VERSION ""

NS_ :

BS_:

BU_: Bat1 OpticalSensor EMUS_BMS SCIMO_PE TelemetryNode Master SensorF SensorR BrakeF BrakeR PDU HVCU HVTU TestBench MDB1 MDB2 MDB3 MDB4 MDB5 MDB6 Track CLU

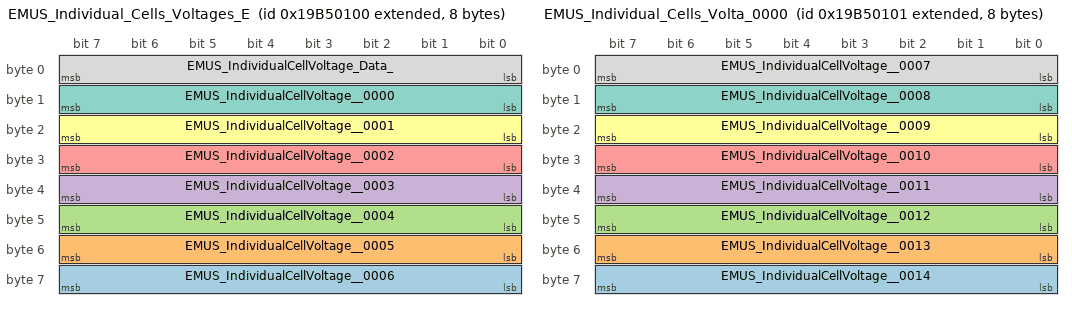
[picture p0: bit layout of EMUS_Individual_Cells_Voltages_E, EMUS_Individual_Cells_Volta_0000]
BO_ 2578776320 EMUS_Individual_Cells_Voltages_E: 8 EMUS_BMS
 SG_ EMUS_IndividualCellVoltage__0006 : 56|8@1+ (0.01,2) [2|4.55] "V" Vector__XXX
 SG_ EMUS_IndividualCellVoltage__0005 : 48|8@1+ (0.01,2) [2|4.55] "V" Vector__XXX
 SG_ EMUS_IndividualCellVoltage__0004 : 40|8@1+ (0.01,2) [2|4.55] "V" Vector__XXX
 SG_ EMUS_IndividualCellVoltage__0003 : 32|8@1+ (0.01,2) [2|4.55] "V" Vector__XXX
 SG_ EMUS_IndividualCellVoltage__0002 : 24|8@1+ (0.01,2) [2|4.55] "V" Vector__XXX
 SG_ EMUS_IndividualCellVoltage__0001 : 16|8@1+ (0.01,2) [2|4.55] "V" Vector__XXX
 SG_ EMUS_IndividualCellVoltage__0000 : 8|8@1+ (0.01,2) [2|4.55] "V" Vector__XXX
 SG_ EMUS_IndividualCellVoltage_Data_ : 0|8@1+ (0.01,2) [2|4.55] "V" Vector__XXX

BO_ 2578776321 EMUS_Individual_Cells_Volta_0000: 8 EMUS_BMS
 SG_ EMUS_IndividualCellVoltage__0014 : 56|8@1+ (0.01,2) [2|4.55] "V" Vector__XXX
 SG_ EMUS_IndividualCellVoltage__0013 : 48|8@1+ (0.01,2) [2|4.55] "V" Vector__XXX
 SG_ EMUS_IndividualCellVoltage__0012 : 40|8@1+ (0.01,2) [2|4.55] "V" Vector__XXX
 SG_ EMUS_IndividualCellVoltage__0011 : 32|8@1+ (0.01,2) [2|4.55] "V" Vector__XXX
 SG_ EMUS_IndividualCellVoltage__0010 : 24|8@1+ (0.01,2) [2|4.55] "V" Vector__XXX
 SG_ EMUS_IndividualCellVoltage__0009 : 16|8@1+ (0.01,2) [2|4.55] "V" Vector__XXX
 SG_ EMUS_IndividualCellVoltage__0008 : 8|8@1+ (0.01,2) [2|4.55] "V" Vector__XXX
 SG_ EMUS_IndividualCellVoltage__0007 : 0|8@1+ (0.01,2) [2|4.55] "V" Vector__XXX

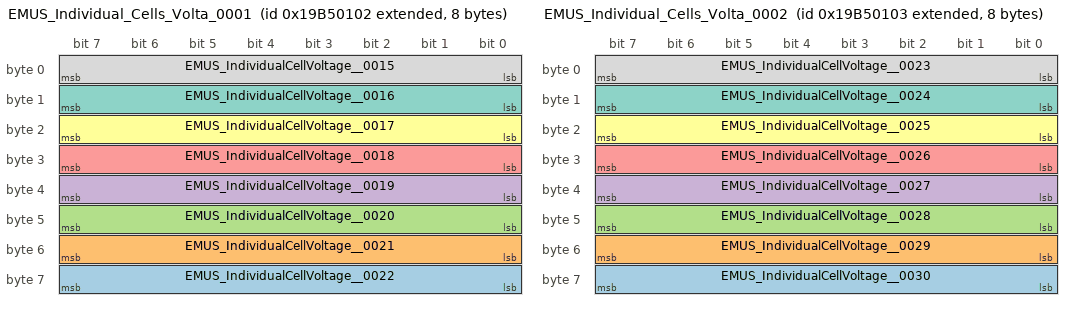
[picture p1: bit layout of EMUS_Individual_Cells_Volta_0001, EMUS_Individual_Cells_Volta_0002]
BO_ 2578776322 EMUS_Individual_Cells_Volta_0001: 8 EMUS_BMS
 SG_ EMUS_IndividualCellVoltage__0022 : 56|8@1+ (0.01,2) [2|4.55] "V" Vector__XXX
 SG_ EMUS_IndividualCellVoltage__0021 : 48|8@1+ (0.01,2) [2|4.55] "V" Vector__XXX
 SG_ EMUS_IndividualCellVoltage__0020 : 40|8@1+ (0.01,2) [2|4.55] "V" Vector__XXX
 SG_ EMUS_IndividualCellVoltage__0019 : 32|8@1+ (0.01,2) [2|4.55] "V" Vector__XXX
 SG_ EMUS_IndividualCellVoltage__0018 : 24|8@1+ (0.01,2) [2|4.55] "V" Vector__XXX
 SG_ EMUS_IndividualCellVoltage__0017 : 16|8@1+ (0.01,2) [2|4.55] "V" Vector__XXX
 SG_ EMUS_IndividualCellVoltage__0016 : 8|8@1+ (0.01,2) [2|4.55] "V" Vector__XXX
 SG_ EMUS_IndividualCellVoltage__0015 : 0|8@1+ (0.01,2) [2|4.55] "V" Vector__XXX

BO_ 2578776323 EMUS_Individual_Cells_Volta_0002: 8 EMUS_BMS
 SG_ EMUS_IndividualCellVoltage__0030 : 56|8@1+ (0.01,2) [2|4.55] "V" Vector__XXX
 SG_ EMUS_IndividualCellVoltage__0029 : 48|8@1+ (0.01,2) [2|4.55] "V" Vector__XXX
 SG_ EMUS_IndividualCellVoltage__0028 : 40|8@1+ (0.01,2) [2|4.55] "V" Vector__XXX
 SG_ EMUS_IndividualCellVoltage__0027 : 32|8@1+ (0.01,2) [2|4.55] "V" Vector__XXX
 SG_ EMUS_IndividualCellVoltage__0026 : 24|8@1+ (0.01,2) [2|4.55] "V" Vector__XXX
 SG_ EMUS_IndividualCellVoltage__0025 : 16|8@1+ (0.01,2) [2|4.55] "V" Vector__XXX
 SG_ EMUS_IndividualCellVoltage__0024 : 8|8@1+ (0.01,2) [2|4.55] "V" Vector__XXX
 SG_ EMUS_IndividualCellVoltage__0023 : 0|8@1+ (0.01,2) [2|4.55] "V" Vector__XXX

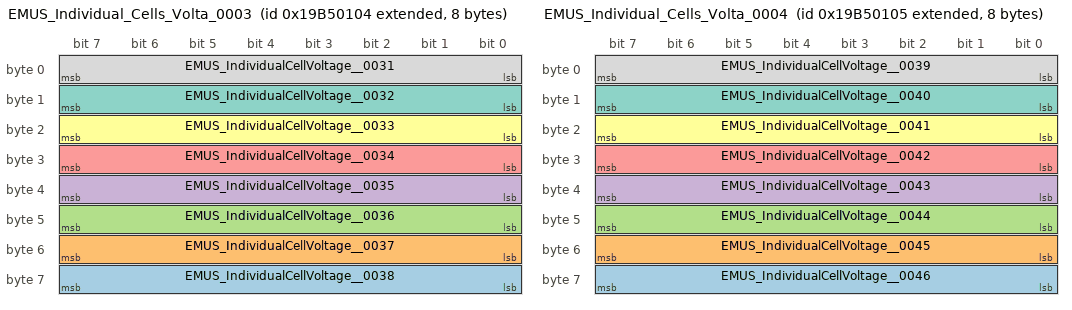
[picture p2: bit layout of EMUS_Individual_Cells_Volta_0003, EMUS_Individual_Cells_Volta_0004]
BO_ 2578776324 EMUS_Individual_Cells_Volta_0003: 8 EMUS_BMS
 SG_ EMUS_IndividualCellVoltage__0038 : 56|8@1+ (0.01,2) [2|4.55] "V" Vector__XXX
 SG_ EMUS_IndividualCellVoltage__0037 : 48|8@1+ (0.01,2) [2|4.55] "V" Vector__XXX
 SG_ EMUS_IndividualCellVoltage__0036 : 40|8@1+ (0.01,2) [2|4.55] "V" Vector__XXX
 SG_ EMUS_IndividualCellVoltage__0035 : 32|8@1+ (0.01,2) [2|4.55] "V" Vector__XXX
 SG_ EMUS_IndividualCellVoltage__0034 : 24|8@1+ (0.01,2) [2|4.55] "V" Vector__XXX
 SG_ EMUS_IndividualCellVoltage__0033 : 16|8@1+ (0.01,2) [2|4.55] "V" Vector__XXX
 SG_ EMUS_IndividualCellVoltage__0032 : 8|8@1+ (0.01,2) [2|4.55] "V" Vector__XXX
 SG_ EMUS_IndividualCellVoltage__0031 : 0|8@1+ (0.01,2) [2|4.55] "V" Vector__XXX

BO_ 2578776325 EMUS_Individual_Cells_Volta_0004: 8 EMUS_BMS
 SG_ EMUS_IndividualCellVoltage__0046 : 56|8@1+ (0.01,2) [2|4.55] "V" Vector__XXX
 SG_ EMUS_IndividualCellVoltage__0045 : 48|8@1+ (0.01,2) [2|4.55] "V" Vector__XXX
 SG_ EMUS_IndividualCellVoltage__0044 : 40|8@1+ (0.01,2) [2|4.55] "V" Vector__XXX
 SG_ EMUS_IndividualCellVoltage__0043 : 32|8@1+ (0.01,2) [2|4.55] "V" Vector__XXX
 SG_ EMUS_IndividualCellVoltage__0042 : 24|8@1+ (0.01,2) [2|4.55] "V" Vector__XXX
 SG_ EMUS_IndividualCellVoltage__0041 : 16|8@1+ (0.01,2) [2|4.55] "V" Vector__XXX
 SG_ EMUS_IndividualCellVoltage__0040 : 8|8@1+ (0.01,2) [2|4.55] "V" Vector__XXX
 SG_ EMUS_IndividualCellVoltage__0039 : 0|8@1+ (0.01,2) [2|4.55] "V" Vector__XXX

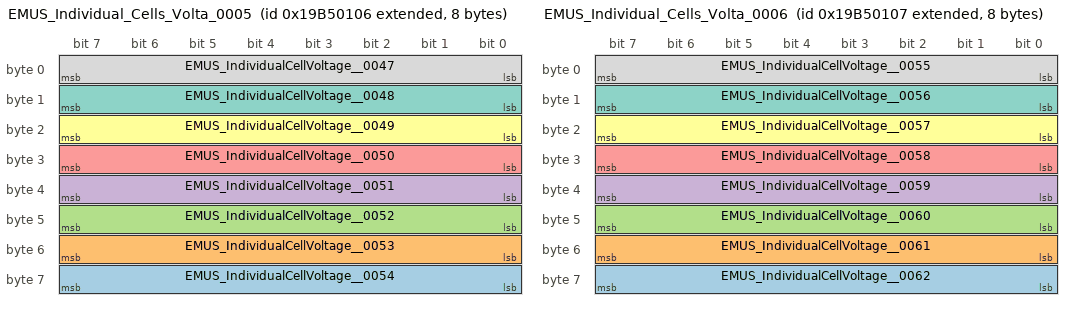
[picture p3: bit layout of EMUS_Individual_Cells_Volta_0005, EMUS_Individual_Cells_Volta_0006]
BO_ 2578776326 EMUS_Individual_Cells_Volta_0005: 8 EMUS_BMS
 SG_ EMUS_IndividualCellVoltage__0054 : 56|8@1+ (0.01,2) [2|4.55] "V" Vector__XXX
 SG_ EMUS_IndividualCellVoltage__0053 : 48|8@1+ (0.01,2) [2|4.55] "V" Vector__XXX
 SG_ EMUS_IndividualCellVoltage__0052 : 40|8@1+ (0.01,2) [2|4.55] "V" Vector__XXX
 SG_ EMUS_IndividualCellVoltage__0051 : 32|8@1+ (0.01,2) [2|4.55] "V" Vector__XXX
 SG_ EMUS_IndividualCellVoltage__0050 : 24|8@1+ (0.01,2) [2|4.55] "V" Vector__XXX
 SG_ EMUS_IndividualCellVoltage__0049 : 16|8@1+ (0.01,2) [2|4.55] "V" Vector__XXX
 SG_ EMUS_IndividualCellVoltage__0048 : 8|8@1+ (0.01,2) [2|4.55] "V" Vector__XXX
 SG_ EMUS_IndividualCellVoltage__0047 : 0|8@1+ (0.01,2) [2|4.55] "V" Vector__XXX

BO_ 2578776327 EMUS_Individual_Cells_Volta_0006: 8 EMUS_BMS
 SG_ EMUS_IndividualCellVoltage__0062 : 56|8@1+ (0.01,2) [2|4.55] "V" Vector__XXX
 SG_ EMUS_IndividualCellVoltage__0061 : 48|8@1+ (0.01,2) [2|4.55] "V" Vector__XXX
 SG_ EMUS_IndividualCellVoltage__0060 : 40|8@1+ (0.01,2) [2|4.55] "V" Vector__XXX
 SG_ EMUS_IndividualCellVoltage__0059 : 32|8@1+ (0.01,2) [2|4.55] "V" Vector__XXX
 SG_ EMUS_IndividualCellVoltage__0058 : 24|8@1+ (0.01,2) [2|4.55] "V" Vector__XXX
 SG_ EMUS_IndividualCellVoltage__0057 : 16|8@1+ (0.01,2) [2|4.55] "V" Vector__XXX
 SG_ EMUS_IndividualCellVoltage__0056 : 8|8@1+ (0.01,2) [2|4.55] "V" Vector__XXX
 SG_ EMUS_IndividualCellVoltage__0055 : 0|8@1+ (0.01,2) [2|4.55] "V" Vector__XXX

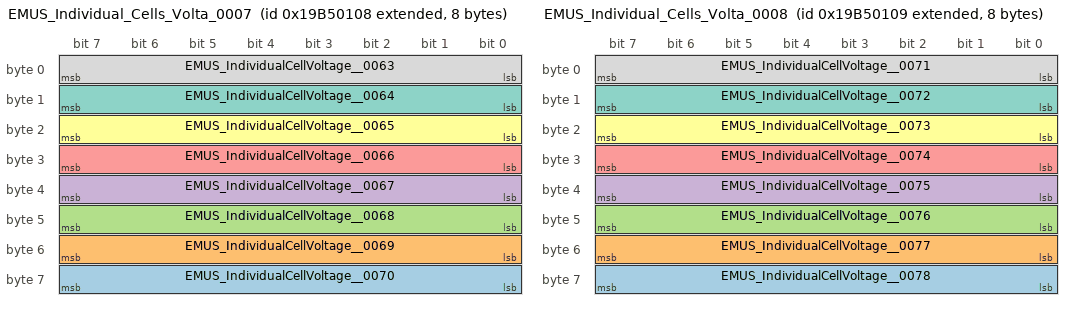
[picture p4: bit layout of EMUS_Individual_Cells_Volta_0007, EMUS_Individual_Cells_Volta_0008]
BO_ 2578776328 EMUS_Individual_Cells_Volta_0007: 8 EMUS_BMS
 SG_ EMUS_IndividualCellVoltage__0070 : 56|8@1+ (0.01,2) [2|4.55] "V" Vector__XXX
 SG_ EMUS_IndividualCellVoltage__0069 : 48|8@1+ (0.01,2) [2|4.55] "V" Vector__XXX
 SG_ EMUS_IndividualCellVoltage__0068 : 40|8@1+ (0.01,2) [2|4.55] "V" Vector__XXX
 SG_ EMUS_IndividualCellVoltage__0067 : 32|8@1+ (0.01,2) [2|4.55] "V" Vector__XXX
 SG_ EMUS_IndividualCellVoltage__0066 : 24|8@1+ (0.01,2) [2|4.55] "V" Vector__XXX
 SG_ EMUS_IndividualCellVoltage__0065 : 16|8@1+ (0.01,2) [2|4.55] "V" Vector__XXX
 SG_ EMUS_IndividualCellVoltage__0064 : 8|8@1+ (0.01,2) [2|4.55] "V" Vector__XXX
 SG_ EMUS_IndividualCellVoltage__0063 : 0|8@1+ (0.01,2) [2|4.55] "V" Vector__XXX

BO_ 2578776329 EMUS_Individual_Cells_Volta_0008: 8 EMUS_BMS
 SG_ EMUS_IndividualCellVoltage__0078 : 56|8@1+ (0.01,2) [2|4.55] "V" Vector__XXX
 SG_ EMUS_IndividualCellVoltage__0077 : 48|8@1+ (0.01,2) [2|4.55] "V" Vector__XXX
 SG_ EMUS_IndividualCellVoltage__0076 : 40|8@1+ (0.01,2) [2|4.55] "V" Vector__XXX
 SG_ EMUS_IndividualCellVoltage__0075 : 32|8@1+ (0.01,2) [2|4.55] "V" Vector__XXX
 SG_ EMUS_IndividualCellVoltage__0074 : 24|8@1+ (0.01,2) [2|4.55] "V" Vector__XXX
 SG_ EMUS_IndividualCellVoltage__0073 : 16|8@1+ (0.01,2) [2|4.55] "V" Vector__XXX
 SG_ EMUS_IndividualCellVoltage__0072 : 8|8@1+ (0.01,2) [2|4.55] "V" Vector__XXX
 SG_ EMUS_IndividualCellVoltage__0071 : 0|8@1+ (0.01,2) [2|4.55] "V" Vector__XXX

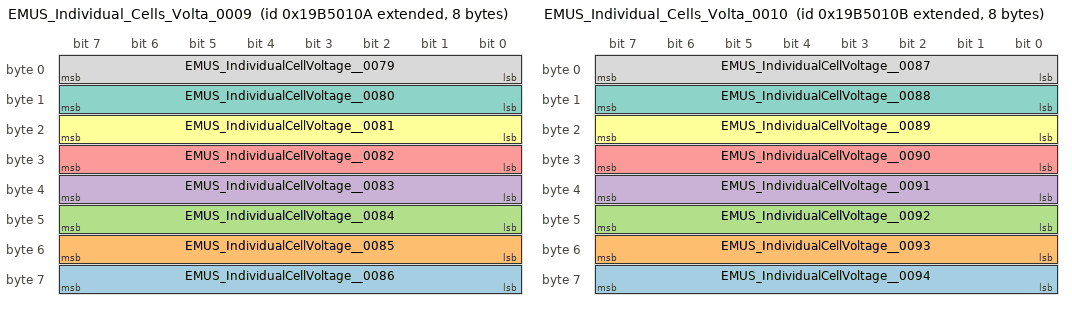
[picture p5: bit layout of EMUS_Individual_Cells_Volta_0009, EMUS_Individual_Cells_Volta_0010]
BO_ 2578776330 EMUS_Individual_Cells_Volta_0009: 8 EMUS_BMS
 SG_ EMUS_IndividualCellVoltage__0086 : 56|8@1+ (0.01,2) [2|4.55] "V" Vector__XXX
 SG_ EMUS_IndividualCellVoltage__0085 : 48|8@1+ (0.01,2) [2|4.55] "V" Vector__XXX
 SG_ EMUS_IndividualCellVoltage__0084 : 40|8@1+ (0.01,2) [2|4.55] "V" Vector__XXX
 SG_ EMUS_IndividualCellVoltage__0083 : 32|8@1+ (0.01,2) [2|4.55] "V" Vector__XXX
 SG_ EMUS_IndividualCellVoltage__0082 : 24|8@1+ (0.01,2) [2|4.55] "V" Vector__XXX
 SG_ EMUS_IndividualCellVoltage__0081 : 16|8@1+ (0.01,2) [2|4.55] "V" Vector__XXX
 SG_ EMUS_IndividualCellVoltage__0080 : 8|8@1+ (0.01,2) [2|4.55] "V" Vector__XXX
 SG_ EMUS_IndividualCellVoltage__0079 : 0|8@1+ (0.01,2) [2|4.55] "V" Vector__XXX

BO_ 2578776331 EMUS_Individual_Cells_Volta_0010: 8 EMUS_BMS
 SG_ EMUS_IndividualCellVoltage__0094 : 56|8@1+ (0.01,2) [2|4.55] "V" Vector__XXX
 SG_ EMUS_IndividualCellVoltage__0093 : 48|8@1+ (0.01,2) [2|4.55] "V" Vector__XXX
 SG_ EMUS_IndividualCellVoltage__0092 : 40|8@1+ (0.01,2) [2|4.55] "V" Vector__XXX
 SG_ EMUS_IndividualCellVoltage__0091 : 32|8@1+ (0.01,2) [2|4.55] "V" Vector__XXX
 SG_ EMUS_IndividualCellVoltage__0090 : 24|8@1+ (0.01,2) [2|4.55] "V" Vector__XXX
 SG_ EMUS_IndividualCellVoltage__0089 : 16|8@1+ (0.01,2) [2|4.55] "V" Vector__XXX
 SG_ EMUS_IndividualCellVoltage__0088 : 8|8@1+ (0.01,2) [2|4.55] "V" Vector__XXX
 SG_ EMUS_IndividualCellVoltage__0087 : 0|8@1+ (0.01,2) [2|4.55] "V" Vector__XXX

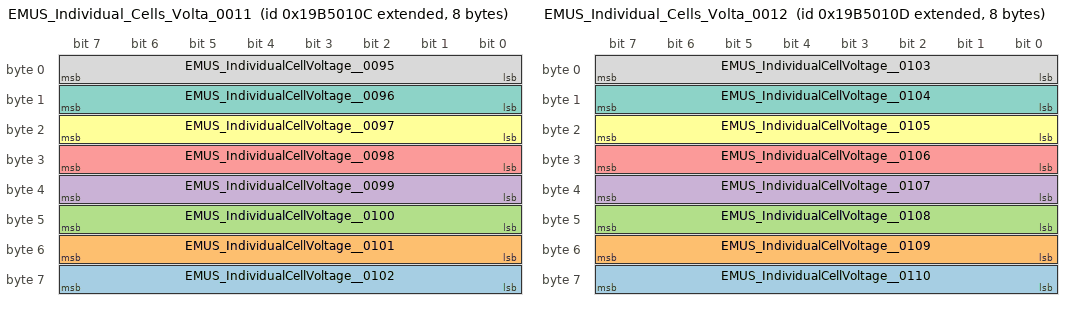
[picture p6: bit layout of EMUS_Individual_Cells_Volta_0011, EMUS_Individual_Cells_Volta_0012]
BO_ 2578776332 EMUS_Individual_Cells_Volta_0011: 8 EMUS_BMS
 SG_ EMUS_IndividualCellVoltage__0102 : 56|8@1+ (0.01,2) [2|4.55] "V" Vector__XXX
 SG_ EMUS_IndividualCellVoltage__0101 : 48|8@1+ (0.01,2) [2|4.55] "V" Vector__XXX
 SG_ EMUS_IndividualCellVoltage__0100 : 40|8@1+ (0.01,2) [2|4.55] "V" Vector__XXX
 SG_ EMUS_IndividualCellVoltage__0099 : 32|8@1+ (0.01,2) [2|4.55] "V" Vector__XXX
 SG_ EMUS_IndividualCellVoltage__0098 : 24|8@1+ (0.01,2) [2|4.55] "V" Vector__XXX
 SG_ EMUS_IndividualCellVoltage__0097 : 16|8@1+ (0.01,2) [2|4.55] "V" Vector__XXX
 SG_ EMUS_IndividualCellVoltage__0096 : 8|8@1+ (0.01,2) [2|4.55] "V" Vector__XXX
 SG_ EMUS_IndividualCellVoltage__0095 : 0|8@1+ (0.01,2) [2|4.55] "V" Vector__XXX

BO_ 2578776333 EMUS_Individual_Cells_Volta_0012: 8 EMUS_BMS
 SG_ EMUS_IndividualCellVoltage__0110 : 56|8@1+ (0.01,2) [2|4.55] "V" Vector__XXX
 SG_ EMUS_IndividualCellVoltage__0109 : 48|8@1+ (0.01,2) [2|4.55] "V" Vector__XXX
 SG_ EMUS_IndividualCellVoltage__0108 : 40|8@1+ (0.01,2) [2|4.55] "V" Vector__XXX
 SG_ EMUS_IndividualCellVoltage__0107 : 32|8@1+ (0.01,2) [2|4.55] "V" Vector__XXX
 SG_ EMUS_IndividualCellVoltage__0106 : 24|8@1+ (0.01,2) [2|4.55] "V" Vector__XXX
 SG_ EMUS_IndividualCellVoltage__0105 : 16|8@1+ (0.01,2) [2|4.55] "V" Vector__XXX
 SG_ EMUS_IndividualCellVoltage__0104 : 8|8@1+ (0.01,2) [2|4.55] "V" Vector__XXX
 SG_ EMUS_IndividualCellVoltage__0103 : 0|8@1+ (0.01,2) [2|4.55] "V" Vector__XXX

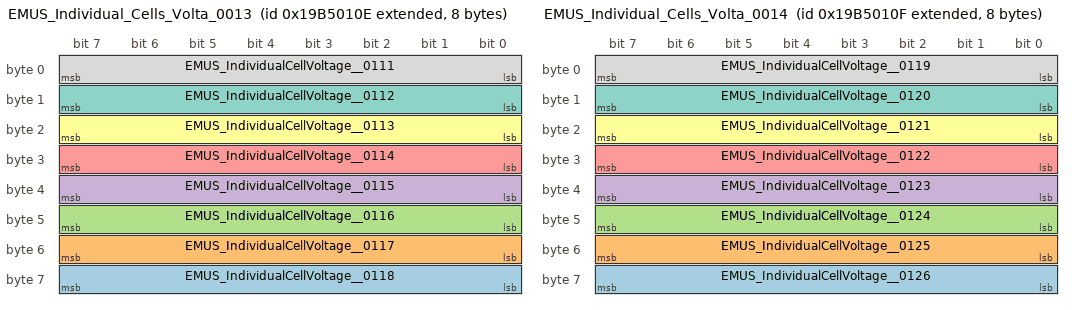
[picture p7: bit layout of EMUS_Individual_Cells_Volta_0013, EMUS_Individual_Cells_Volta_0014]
BO_ 2578776334 EMUS_Individual_Cells_Volta_0013: 8 EMUS_BMS
 SG_ EMUS_IndividualCellVoltage__0118 : 56|8@1+ (0.01,2) [2|4.55] "V" Vector__XXX
 SG_ EMUS_IndividualCellVoltage__0117 : 48|8@1+ (0.01,2) [2|4.55] "V" Vector__XXX
 SG_ EMUS_IndividualCellVoltage__0116 : 40|8@1+ (0.01,2) [2|4.55] "V" Vector__XXX
 SG_ EMUS_IndividualCellVoltage__0115 : 32|8@1+ (0.01,2) [2|4.55] "V" Vector__XXX
 SG_ EMUS_IndividualCellVoltage__0114 : 24|8@1+ (0.01,2) [2|4.55] "V" Vector__XXX
 SG_ EMUS_IndividualCellVoltage__0113 : 16|8@1+ (0.01,2) [2|4.55] "V" Vector__XXX
 SG_ EMUS_IndividualCellVoltage__0112 : 8|8@1+ (0.01,2) [2|4.55] "V" Vector__XXX
 SG_ EMUS_IndividualCellVoltage__0111 : 0|8@1+ (0.01,2) [2|4.55] "V" Vector__XXX

BO_ 2578776335 EMUS_Individual_Cells_Volta_0014: 8 EMUS_BMS
 SG_ EMUS_IndividualCellVoltage__0126 : 56|8@1+ (0.01,2) [2|4.55] "V" Vector__XXX
 SG_ EMUS_IndividualCellVoltage__0125 : 48|8@1+ (0.01,2) [2|4.55] "V" Vector__XXX
 SG_ EMUS_IndividualCellVoltage__0124 : 40|8@1+ (0.01,2) [2|4.55] "V" Vector__XXX
 SG_ EMUS_IndividualCellVoltage__0123 : 32|8@1+ (0.01,2) [2|4.55] "V" Vector__XXX
 SG_ EMUS_IndividualCellVoltage__0122 : 24|8@1+ (0.01,2) [2|4.55] "V" Vector__XXX
 SG_ EMUS_IndividualCellVoltage__0121 : 16|8@1+ (0.01,2) [2|4.55] "V" Vector__XXX
 SG_ EMUS_IndividualCellVoltage__0120 : 8|8@1+ (0.01,2) [2|4.55] "V" Vector__XXX
 SG_ EMUS_IndividualCellVoltage__0119 : 0|8@1+ (0.01,2) [2|4.55] "V" Vector__XXX

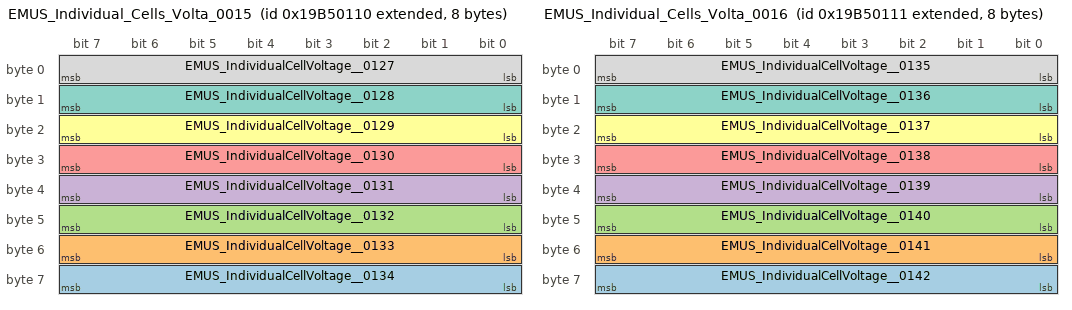
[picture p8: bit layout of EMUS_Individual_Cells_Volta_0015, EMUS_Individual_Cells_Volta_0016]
BO_ 2578776336 EMUS_Individual_Cells_Volta_0015: 8 EMUS_BMS
 SG_ EMUS_IndividualCellVoltage__0134 : 56|8@1+ (0.01,2) [2|4.55] "V" Vector__XXX
 SG_ EMUS_IndividualCellVoltage__0133 : 48|8@1+ (0.01,2) [2|4.55] "V" Vector__XXX
 SG_ EMUS_IndividualCellVoltage__0132 : 40|8@1+ (0.01,2) [2|4.55] "V" Vector__XXX
 SG_ EMUS_IndividualCellVoltage__0131 : 32|8@1+ (0.01,2) [2|4.55] "V" Vector__XXX
 SG_ EMUS_IndividualCellVoltage__0130 : 24|8@1+ (0.01,2) [2|4.55] "V" Vector__XXX
 SG_ EMUS_IndividualCellVoltage__0129 : 16|8@1+ (0.01,2) [2|4.55] "V" Vector__XXX
 SG_ EMUS_IndividualCellVoltage__0128 : 8|8@1+ (0.01,2) [2|4.55] "V" Vector__XXX
 SG_ EMUS_IndividualCellVoltage__0127 : 0|8@1+ (0.01,2) [2|4.55] "V" Vector__XXX

BO_ 2578776337 EMUS_Individual_Cells_Volta_0016: 8 EMUS_BMS
 SG_ EMUS_IndividualCellVoltage__0142 : 56|8@1+ (0.01,2) [2|4.55] "V" Vector__XXX
 SG_ EMUS_IndividualCellVoltage__0141 : 48|8@1+ (0.01,2) [2|4.55] "V" Vector__XXX
 SG_ EMUS_IndividualCellVoltage__0140 : 40|8@1+ (0.01,2) [2|4.55] "V" Vector__XXX
 SG_ EMUS_IndividualCellVoltage__0139 : 32|8@1+ (0.01,2) [2|4.55] "V" Vector__XXX
 SG_ EMUS_IndividualCellVoltage__0138 : 24|8@1+ (0.01,2) [2|4.55] "V" Vector__XXX
 SG_ EMUS_IndividualCellVoltage__0137 : 16|8@1+ (0.01,2) [2|4.55] "V" Vector__XXX
 SG_ EMUS_IndividualCellVoltage__0136 : 8|8@1+ (0.01,2) [2|4.55] "V" Vector__XXX
 SG_ EMUS_IndividualCellVoltage__0135 : 0|8@1+ (0.01,2) [2|4.55] "V" Vector__XXX

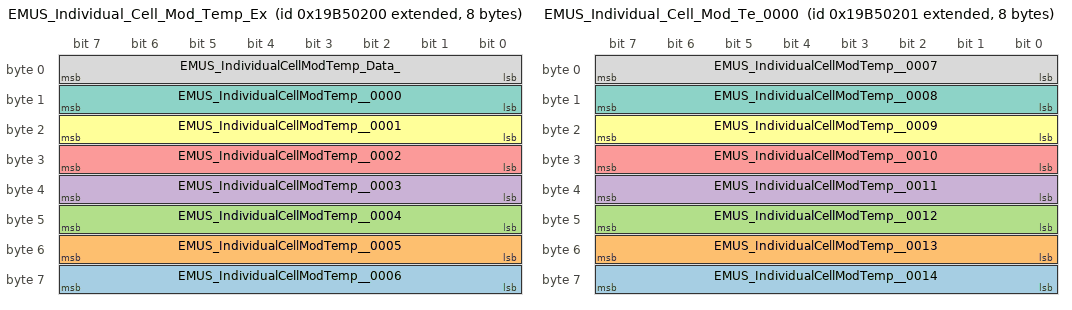
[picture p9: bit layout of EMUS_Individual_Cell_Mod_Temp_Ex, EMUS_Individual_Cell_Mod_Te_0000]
BO_ 2578776576 EMUS_Individual_Cell_Mod_Temp_Ex: 8 EMUS_BMS
 SG_ EMUS_IndividualCellModTemp__0006 : 56|8@1+ (1,-100) [-100|155] "%" Vector__XXX
 SG_ EMUS_IndividualCellModTemp__0005 : 48|8@1+ (1,-100) [-100|155] "%" Vector__XXX
 SG_ EMUS_IndividualCellModTemp__0004 : 40|8@1+ (1,-100) [-100|155] "%" Vector__XXX
 SG_ EMUS_IndividualCellModTemp__0003 : 32|8@1+ (1,-100) [-100|155] "%" Vector__XXX
 SG_ EMUS_IndividualCellModTemp__0002 : 24|8@1+ (1,-100) [-100|155] "%" Vector__XXX
 SG_ EMUS_IndividualCellModTemp__0001 : 16|8@1+ (1,-100) [-100|155] "%" Vector__XXX
 SG_ EMUS_IndividualCellModTemp__0000 : 8|8@1+ (1,-100) [-100|155] "%" Vector__XXX
 SG_ EMUS_IndividualCellModTemp_Data_ : 0|8@1+ (1,-100) [-100|155] "%" Vector__XXX

BO_ 2578776577 EMUS_Individual_Cell_Mod_Te_0000: 8 EMUS_BMS
 SG_ EMUS_IndividualCellModTemp__0014 : 56|8@1+ (1,-100) [-100|155] "%" Vector__XXX
 SG_ EMUS_IndividualCellModTemp__0013 : 48|8@1+ (1,-100) [-100|155] "%" Vector__XXX
 SG_ EMUS_IndividualCellModTemp__0012 : 40|8@1+ (1,-100) [-100|155] "%" Vector__XXX
 SG_ EMUS_IndividualCellModTemp__0011 : 32|8@1+ (1,-100) [-100|155] "%" Vector__XXX
 SG_ EMUS_IndividualCellModTemp__0010 : 24|8@1+ (1,-100) [-100|155] "%" Vector__XXX
 SG_ EMUS_IndividualCellModTemp__0009 : 16|8@1+ (1,-100) [-100|155] "%" Vector__XXX
 SG_ EMUS_IndividualCellModTemp__0008 : 8|8@1+ (1,-100) [-100|155] "%" Vector__XXX
 SG_ EMUS_IndividualCellModTemp__0007 : 0|8@1+ (1,-100) [-100|155] "%" Vector__XXX

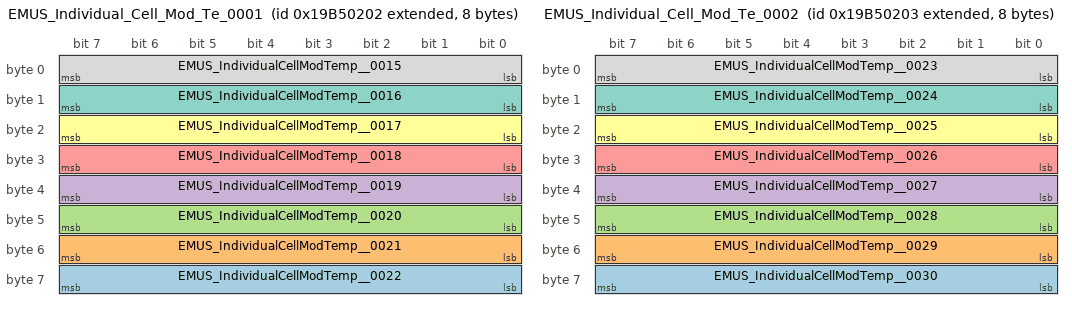
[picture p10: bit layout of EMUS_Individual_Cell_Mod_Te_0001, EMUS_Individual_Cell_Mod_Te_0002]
BO_ 2578776578 EMUS_Individual_Cell_Mod_Te_0001: 8 EMUS_BMS
 SG_ EMUS_IndividualCellModTemp__0022 : 56|8@1+ (1,-100) [-100|155] "%" Vector__XXX
 SG_ EMUS_IndividualCellModTemp__0021 : 48|8@1+ (1,-100) [-100|155] "%" Vector__XXX
 SG_ EMUS_IndividualCellModTemp__0020 : 40|8@1+ (1,-100) [-100|155] "%" Vector__XXX
 SG_ EMUS_IndividualCellModTemp__0019 : 32|8@1+ (1,-100) [-100|155] "%" Vector__XXX
 SG_ EMUS_IndividualCellModTemp__0018 : 24|8@1+ (1,-100) [-100|155] "%" Vector__XXX
 SG_ EMUS_IndividualCellModTemp__0017 : 16|8@1+ (1,-100) [-100|155] "%" Vector__XXX
 SG_ EMUS_IndividualCellModTemp__0016 : 8|8@1+ (1,-100) [-100|155] "%" Vector__XXX
 SG_ EMUS_IndividualCellModTemp__0015 : 0|8@1+ (1,-100) [-100|155] "%" Vector__XXX

BO_ 2578776579 EMUS_Individual_Cell_Mod_Te_0002: 8 EMUS_BMS
 SG_ EMUS_IndividualCellModTemp__0030 : 56|8@1+ (1,-100) [-100|155] "%" Vector__XXX
 SG_ EMUS_IndividualCellModTemp__0029 : 48|8@1+ (1,-100) [-100|155] "%" Vector__XXX
 SG_ EMUS_IndividualCellModTemp__0028 : 40|8@1+ (1,-100) [-100|155] "%" Vector__XXX
 SG_ EMUS_IndividualCellModTemp__0027 : 32|8@1+ (1,-100) [-100|155] "%" Vector__XXX
 SG_ EMUS_IndividualCellModTemp__0026 : 24|8@1+ (1,-100) [-100|155] "%" Vector__XXX
 SG_ EMUS_IndividualCellModTemp__0025 : 16|8@1+ (1,-100) [-100|155] "%" Vector__XXX
 SG_ EMUS_IndividualCellModTemp__0024 : 8|8@1+ (1,-100) [-100|155] "%" Vector__XXX
 SG_ EMUS_IndividualCellModTemp__0023 : 0|8@1+ (1,-100) [-100|155] "%" Vector__XXX

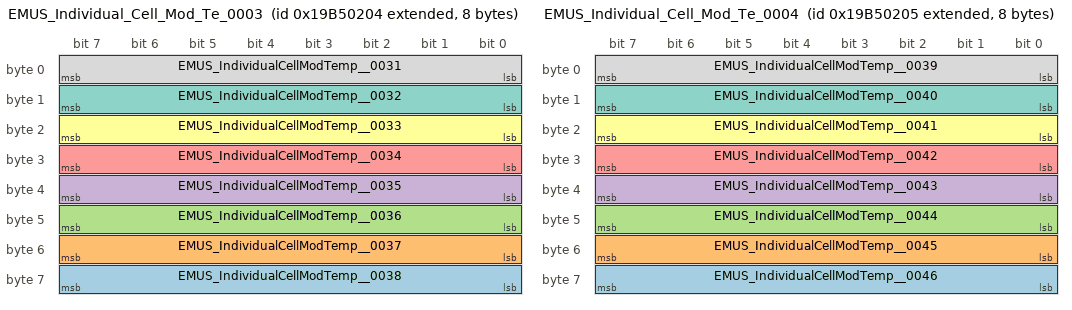
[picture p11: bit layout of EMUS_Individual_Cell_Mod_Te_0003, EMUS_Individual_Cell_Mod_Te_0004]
BO_ 2578776580 EMUS_Individual_Cell_Mod_Te_0003: 8 EMUS_BMS
 SG_ EMUS_IndividualCellModTemp__0038 : 56|8@1+ (1,-100) [-100|155] "%" Vector__XXX
 SG_ EMUS_IndividualCellModTemp__0037 : 48|8@1+ (1,-100) [-100|155] "%" Vector__XXX
 SG_ EMUS_IndividualCellModTemp__0036 : 40|8@1+ (1,-100) [-100|155] "%" Vector__XXX
 SG_ EMUS_IndividualCellModTemp__0035 : 32|8@1+ (1,-100) [-100|155] "%" Vector__XXX
 SG_ EMUS_IndividualCellModTemp__0034 : 24|8@1+ (1,-100) [-100|155] "%" Vector__XXX
 SG_ EMUS_IndividualCellModTemp__0033 : 16|8@1+ (1,-100) [-100|155] "%" Vector__XXX
 SG_ EMUS_IndividualCellModTemp__0032 : 8|8@1+ (1,-100) [-100|155] "%" Vector__XXX
 SG_ EMUS_IndividualCellModTemp__0031 : 0|8@1+ (1,-100) [-100|155] "%" Vector__XXX

BO_ 2578776581 EMUS_Individual_Cell_Mod_Te_0004: 8 EMUS_BMS
 SG_ EMUS_IndividualCellModTemp__0046 : 56|8@1+ (1,-100) [-100|155] "%" Vector__XXX
 SG_ EMUS_IndividualCellModTemp__0045 : 48|8@1+ (1,-100) [-100|155] "%" Vector__XXX
 SG_ EMUS_IndividualCellModTemp__0044 : 40|8@1+ (1,-100) [-100|155] "%" Vector__XXX
 SG_ EMUS_IndividualCellModTemp__0043 : 32|8@1+ (1,-100) [-100|155] "%" Vector__XXX
 SG_ EMUS_IndividualCellModTemp__0042 : 24|8@1+ (1,-100) [-100|155] "%" Vector__XXX
 SG_ EMUS_IndividualCellModTemp__0041 : 16|8@1+ (1,-100) [-100|155] "%" Vector__XXX
 SG_ EMUS_IndividualCellModTemp__0040 : 8|8@1+ (1,-100) [-100|155] "%" Vector__XXX
 SG_ EMUS_IndividualCellModTemp__0039 : 0|8@1+ (1,-100) [-100|155] "%" Vector__XXX

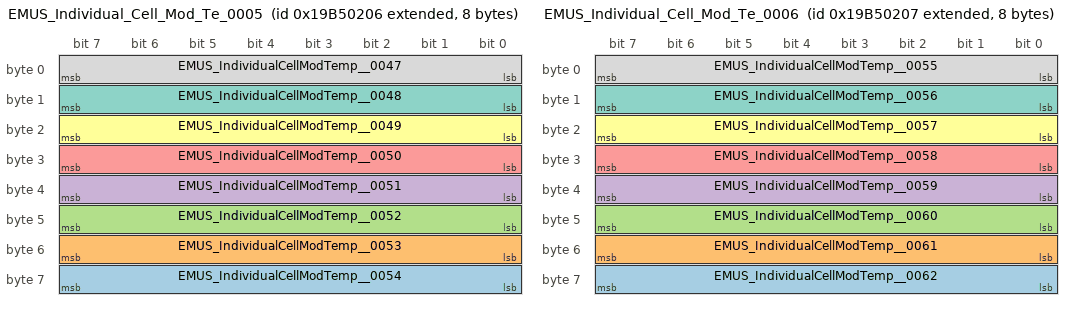
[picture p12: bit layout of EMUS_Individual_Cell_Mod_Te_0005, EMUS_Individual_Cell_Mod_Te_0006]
BO_ 2578776582 EMUS_Individual_Cell_Mod_Te_0005: 8 EMUS_BMS
 SG_ EMUS_IndividualCellModTemp__0054 : 56|8@1+ (1,-100) [-100|155] "%" Vector__XXX
 SG_ EMUS_IndividualCellModTemp__0053 : 48|8@1+ (1,-100) [-100|155] "%" Vector__XXX
 SG_ EMUS_IndividualCellModTemp__0052 : 40|8@1+ (1,-100) [-100|155] "%" Vector__XXX
 SG_ EMUS_IndividualCellModTemp__0051 : 32|8@1+ (1,-100) [-100|155] "%" Vector__XXX
 SG_ EMUS_IndividualCellModTemp__0050 : 24|8@1+ (1,-100) [-100|155] "%" Vector__XXX
 SG_ EMUS_IndividualCellModTemp__0049 : 16|8@1+ (1,-100) [-100|155] "%" Vector__XXX
 SG_ EMUS_IndividualCellModTemp__0048 : 8|8@1+ (1,-100) [-100|155] "%" Vector__XXX
 SG_ EMUS_IndividualCellModTemp__0047 : 0|8@1+ (1,-100) [-100|155] "%" Vector__XXX

BO_ 2578776583 EMUS_Individual_Cell_Mod_Te_0006: 8 EMUS_BMS
 SG_ EMUS_IndividualCellModTemp__0062 : 56|8@1+ (1,-100) [-100|155] "%" Vector__XXX
 SG_ EMUS_IndividualCellModTemp__0061 : 48|8@1+ (1,-100) [-100|155] "%" Vector__XXX
 SG_ EMUS_IndividualCellModTemp__0060 : 40|8@1+ (1,-100) [-100|155] "%" Vector__XXX
 SG_ EMUS_IndividualCellModTemp__0059 : 32|8@1+ (1,-100) [-100|155] "%" Vector__XXX
 SG_ EMUS_IndividualCellModTemp__0058 : 24|8@1+ (1,-100) [-100|155] "%" Vector__XXX
 SG_ EMUS_IndividualCellModTemp__0057 : 16|8@1+ (1,-100) [-100|155] "%" Vector__XXX
 SG_ EMUS_IndividualCellModTemp__0056 : 8|8@1+ (1,-100) [-100|155] "%" Vector__XXX
 SG_ EMUS_IndividualCellModTemp__0055 : 0|8@1+ (1,-100) [-100|155] "%" Vector__XXX

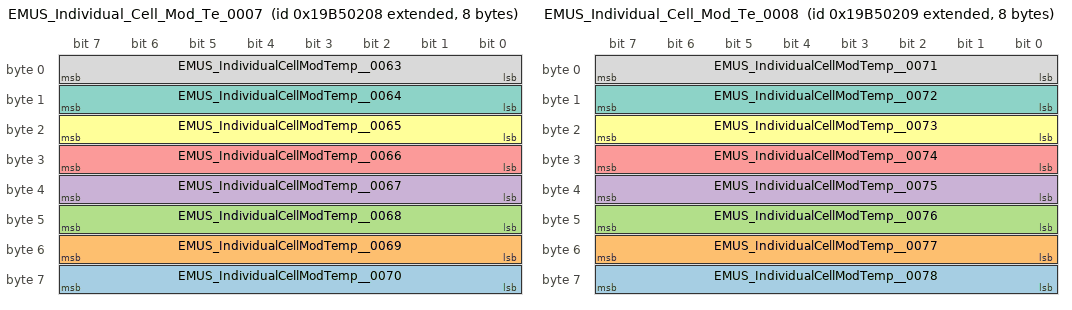
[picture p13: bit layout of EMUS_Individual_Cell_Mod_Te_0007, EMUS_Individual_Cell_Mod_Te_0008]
BO_ 2578776584 EMUS_Individual_Cell_Mod_Te_0007: 8 EMUS_BMS
 SG_ EMUS_IndividualCellModTemp__0070 : 56|8@1+ (1,-100) [-100|155] "%" Vector__XXX
 SG_ EMUS_IndividualCellModTemp__0069 : 48|8@1+ (1,-100) [-100|155] "%" Vector__XXX
 SG_ EMUS_IndividualCellModTemp__0068 : 40|8@1+ (1,-100) [-100|155] "%" Vector__XXX
 SG_ EMUS_IndividualCellModTemp__0067 : 32|8@1+ (1,-100) [-100|155] "%" Vector__XXX
 SG_ EMUS_IndividualCellModTemp__0066 : 24|8@1+ (1,-100) [-100|155] "%" Vector__XXX
 SG_ EMUS_IndividualCellModTemp__0065 : 16|8@1+ (1,-100) [-100|155] "%" Vector__XXX
 SG_ EMUS_IndividualCellModTemp__0064 : 8|8@1+ (1,-100) [-100|155] "%" Vector__XXX
 SG_ EMUS_IndividualCellModTemp__0063 : 0|8@1+ (1,-100) [-100|155] "%" Vector__XXX

BO_ 2578776585 EMUS_Individual_Cell_Mod_Te_0008: 8 EMUS_BMS
 SG_ EMUS_IndividualCellModTemp__0078 : 56|8@1+ (1,-100) [-100|155] "%" Vector__XXX
 SG_ EMUS_IndividualCellModTemp__0077 : 48|8@1+ (1,-100) [-100|155] "%" Vector__XXX
 SG_ EMUS_IndividualCellModTemp__0076 : 40|8@1+ (1,-100) [-100|155] "%" Vector__XXX
 SG_ EMUS_IndividualCellModTemp__0075 : 32|8@1+ (1,-100) [-100|155] "%" Vector__XXX
 SG_ EMUS_IndividualCellModTemp__0074 : 24|8@1+ (1,-100) [-100|155] "%" Vector__XXX
 SG_ EMUS_IndividualCellModTemp__0073 : 16|8@1+ (1,-100) [-100|155] "%" Vector__XXX
 SG_ EMUS_IndividualCellModTemp__0072 : 8|8@1+ (1,-100) [-100|155] "%" Vector__XXX
 SG_ EMUS_IndividualCellModTemp__0071 : 0|8@1+ (1,-100) [-100|155] "%" Vector__XXX

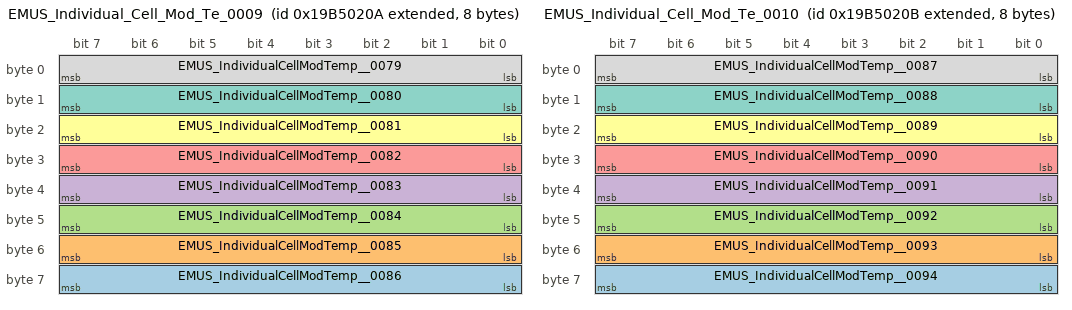
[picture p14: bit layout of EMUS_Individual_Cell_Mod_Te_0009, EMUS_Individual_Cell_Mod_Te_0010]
BO_ 2578776586 EMUS_Individual_Cell_Mod_Te_0009: 8 EMUS_BMS
 SG_ EMUS_IndividualCellModTemp__0086 : 56|8@1+ (1,-100) [-100|155] "%" Vector__XXX
 SG_ EMUS_IndividualCellModTemp__0085 : 48|8@1+ (1,-100) [-100|155] "%" Vector__XXX
 SG_ EMUS_IndividualCellModTemp__0084 : 40|8@1+ (1,-100) [-100|155] "%" Vector__XXX
 SG_ EMUS_IndividualCellModTemp__0083 : 32|8@1+ (1,-100) [-100|155] "%" Vector__XXX
 SG_ EMUS_IndividualCellModTemp__0082 : 24|8@1+ (1,-100) [-100|155] "%" Vector__XXX
 SG_ EMUS_IndividualCellModTemp__0081 : 16|8@1+ (1,-100) [-100|155] "%" Vector__XXX
 SG_ EMUS_IndividualCellModTemp__0080 : 8|8@1+ (1,-100) [-100|155] "%" Vector__XXX
 SG_ EMUS_IndividualCellModTemp__0079 : 0|8@1+ (1,-100) [-100|155] "%" Vector__XXX

BO_ 2578776587 EMUS_Individual_Cell_Mod_Te_0010: 8 EMUS_BMS
 SG_ EMUS_IndividualCellModTemp__0094 : 56|8@1+ (1,-100) [-100|155] "%" Vector__XXX
 SG_ EMUS_IndividualCellModTemp__0093 : 48|8@1+ (1,-100) [-100|155] "%" Vector__XXX
 SG_ EMUS_IndividualCellModTemp__0092 : 40|8@1+ (1,-100) [-100|155] "%" Vector__XXX
 SG_ EMUS_IndividualCellModTemp__0091 : 32|8@1+ (1,-100) [-100|155] "%" Vector__XXX
 SG_ EMUS_IndividualCellModTemp__0090 : 24|8@1+ (1,-100) [-100|155] "%" Vector__XXX
 SG_ EMUS_IndividualCellModTemp__0089 : 16|8@1+ (1,-100) [-100|155] "%" Vector__XXX
 SG_ EMUS_IndividualCellModTemp__0088 : 8|8@1+ (1,-100) [-100|155] "%" Vector__XXX
 SG_ EMUS_IndividualCellModTemp__0087 : 0|8@1+ (1,-100) [-100|155] "%" Vector__XXX

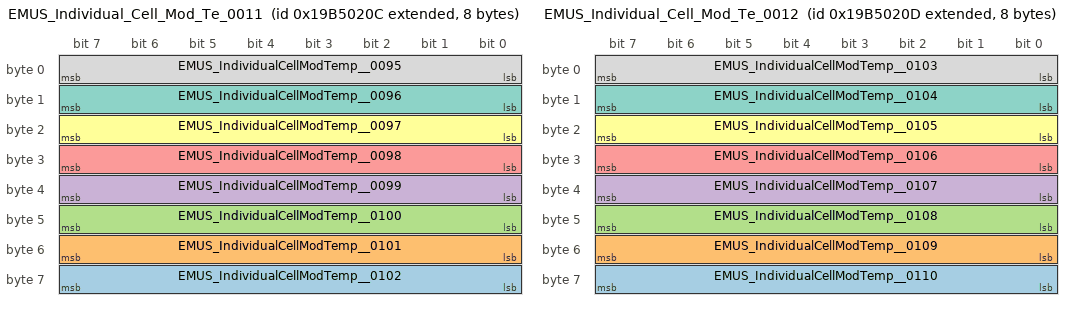
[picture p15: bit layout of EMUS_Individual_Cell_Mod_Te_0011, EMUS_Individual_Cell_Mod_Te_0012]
BO_ 2578776588 EMUS_Individual_Cell_Mod_Te_0011: 8 EMUS_BMS
 SG_ EMUS_IndividualCellModTemp__0102 : 56|8@1+ (1,-100) [-100|155] "%" Vector__XXX
 SG_ EMUS_IndividualCellModTemp__0101 : 48|8@1+ (1,-100) [-100|155] "%" Vector__XXX
 SG_ EMUS_IndividualCellModTemp__0100 : 40|8@1+ (1,-100) [-100|155] "%" Vector__XXX
 SG_ EMUS_IndividualCellModTemp__0099 : 32|8@1+ (1,-100) [-100|155] "%" Vector__XXX
 SG_ EMUS_IndividualCellModTemp__0098 : 24|8@1+ (1,-100) [-100|155] "%" Vector__XXX
 SG_ EMUS_IndividualCellModTemp__0097 : 16|8@1+ (1,-100) [-100|155] "%" Vector__XXX
 SG_ EMUS_IndividualCellModTemp__0096 : 8|8@1+ (1,-100) [-100|155] "%" Vector__XXX
 SG_ EMUS_IndividualCellModTemp__0095 : 0|8@1+ (1,-100) [-100|155] "%" Vector__XXX

BO_ 2578776589 EMUS_Individual_Cell_Mod_Te_0012: 8 EMUS_BMS
 SG_ EMUS_IndividualCellModTemp__0110 : 56|8@1+ (1,-100) [-100|155] "%" Vector__XXX
 SG_ EMUS_IndividualCellModTemp__0109 : 48|8@1+ (1,-100) [-100|155] "%" Vector__XXX
 SG_ EMUS_IndividualCellModTemp__0108 : 40|8@1+ (1,-100) [-100|155] "%" Vector__XXX
 SG_ EMUS_IndividualCellModTemp__0107 : 32|8@1+ (1,-100) [-100|155] "%" Vector__XXX
 SG_ EMUS_IndividualCellModTemp__0106 : 24|8@1+ (1,-100) [-100|155] "%" Vector__XXX
 SG_ EMUS_IndividualCellModTemp__0105 : 16|8@1+ (1,-100) [-100|155] "%" Vector__XXX
 SG_ EMUS_IndividualCellModTemp__0104 : 8|8@1+ (1,-100) [-100|155] "%" Vector__XXX
 SG_ EMUS_IndividualCellModTemp__0103 : 0|8@1+ (1,-100) [-100|155] "%" Vector__XXX

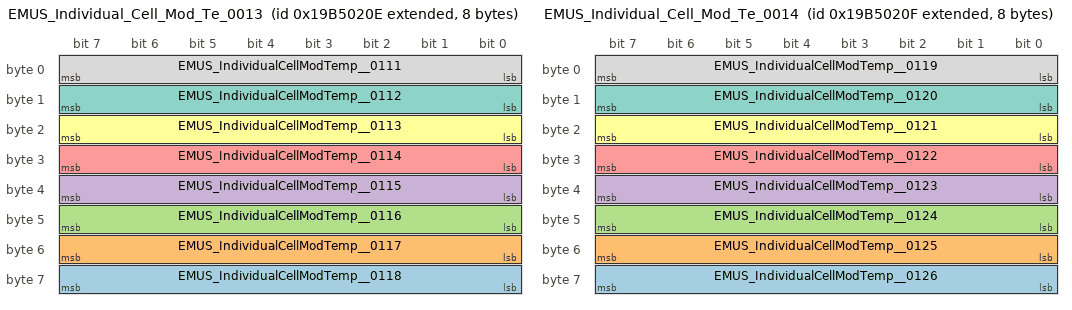
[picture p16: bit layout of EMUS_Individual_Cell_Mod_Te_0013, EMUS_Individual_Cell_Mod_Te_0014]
BO_ 2578776590 EMUS_Individual_Cell_Mod_Te_0013: 8 EMUS_BMS
 SG_ EMUS_IndividualCellModTemp__0118 : 56|8@1+ (1,-100) [-100|155] "%" Vector__XXX
 SG_ EMUS_IndividualCellModTemp__0117 : 48|8@1+ (1,-100) [-100|155] "%" Vector__XXX
 SG_ EMUS_IndividualCellModTemp__0116 : 40|8@1+ (1,-100) [-100|155] "%" Vector__XXX
 SG_ EMUS_IndividualCellModTemp__0115 : 32|8@1+ (1,-100) [-100|155] "%" Vector__XXX
 SG_ EMUS_IndividualCellModTemp__0114 : 24|8@1+ (1,-100) [-100|155] "%" Vector__XXX
 SG_ EMUS_IndividualCellModTemp__0113 : 16|8@1+ (1,-100) [-100|155] "%" Vector__XXX
 SG_ EMUS_IndividualCellModTemp__0112 : 8|8@1+ (1,-100) [-100|155] "%" Vector__XXX
 SG_ EMUS_IndividualCellModTemp__0111 : 0|8@1+ (1,-100) [-100|155] "%" Vector__XXX

BO_ 2578776591 EMUS_Individual_Cell_Mod_Te_0014: 8 EMUS_BMS
 SG_ EMUS_IndividualCellModTemp__0126 : 56|8@1+ (1,-100) [-100|155] "%" Vector__XXX
 SG_ EMUS_IndividualCellModTemp__0125 : 48|8@1+ (1,-100) [-100|155] "%" Vector__XXX
 SG_ EMUS_IndividualCellModTemp__0124 : 40|8@1+ (1,-100) [-100|155] "%" Vector__XXX
 SG_ EMUS_IndividualCellModTemp__0123 : 32|8@1+ (1,-100) [-100|155] "%" Vector__XXX
 SG_ EMUS_IndividualCellModTemp__0122 : 24|8@1+ (1,-100) [-100|155] "%" Vector__XXX
 SG_ EMUS_IndividualCellModTemp__0121 : 16|8@1+ (1,-100) [-100|155] "%" Vector__XXX
 SG_ EMUS_IndividualCellModTemp__0120 : 8|8@1+ (1,-100) [-100|155] "%" Vector__XXX
 SG_ EMUS_IndividualCellModTemp__0119 : 0|8@1+ (1,-100) [-100|155] "%" Vector__XXX

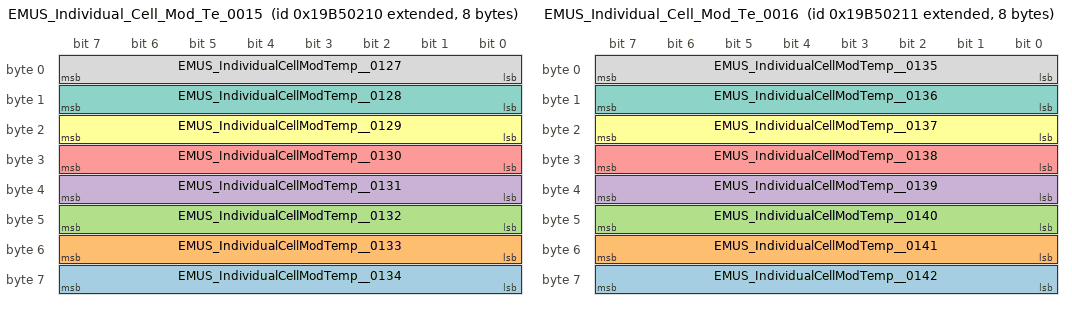
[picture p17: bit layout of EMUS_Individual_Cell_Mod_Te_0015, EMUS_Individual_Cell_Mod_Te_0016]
BO_ 2578776592 EMUS_Individual_Cell_Mod_Te_0015: 8 EMUS_BMS
 SG_ EMUS_IndividualCellModTemp__0134 : 56|8@1+ (1,-100) [-100|155] "%" Vector__XXX
 SG_ EMUS_IndividualCellModTemp__0133 : 48|8@1+ (1,-100) [-100|155] "%" Vector__XXX
 SG_ EMUS_IndividualCellModTemp__0132 : 40|8@1+ (1,-100) [-100|155] "%" Vector__XXX
 SG_ EMUS_IndividualCellModTemp__0131 : 32|8@1+ (1,-100) [-100|155] "%" Vector__XXX
 SG_ EMUS_IndividualCellModTemp__0130 : 24|8@1+ (1,-100) [-100|155] "%" Vector__XXX
 SG_ EMUS_IndividualCellModTemp__0129 : 16|8@1+ (1,-100) [-100|155] "%" Vector__XXX
 SG_ EMUS_IndividualCellModTemp__0128 : 8|8@1+ (1,-100) [-100|155] "%" Vector__XXX
 SG_ EMUS_IndividualCellModTemp__0127 : 0|8@1+ (1,-100) [-100|155] "%" Vector__XXX

BO_ 2578776593 EMUS_Individual_Cell_Mod_Te_0016: 8 EMUS_BMS
 SG_ EMUS_IndividualCellModTemp__0142 : 56|8@1+ (1,-100) [-100|155] "%" Vector__XXX
 SG_ EMUS_IndividualCellModTemp__0141 : 48|8@1+ (1,-100) [-100|155] "%" Vector__XXX
 SG_ EMUS_IndividualCellModTemp__0140 : 40|8@1+ (1,-100) [-100|155] "%" Vector__XXX
 SG_ EMUS_IndividualCellModTemp__0139 : 32|8@1+ (1,-100) [-100|155] "%" Vector__XXX
 SG_ EMUS_IndividualCellModTemp__0138 : 24|8@1+ (1,-100) [-100|155] "%" Vector__XXX
 SG_ EMUS_IndividualCellModTemp__0137 : 16|8@1+ (1,-100) [-100|155] "%" Vector__XXX
 SG_ EMUS_IndividualCellModTemp__0136 : 8|8@1+ (1,-100) [-100|155] "%" Vector__XXX
 SG_ EMUS_IndividualCellModTemp__0135 : 0|8@1+ (1,-100) [-100|155] "%" Vector__XXX

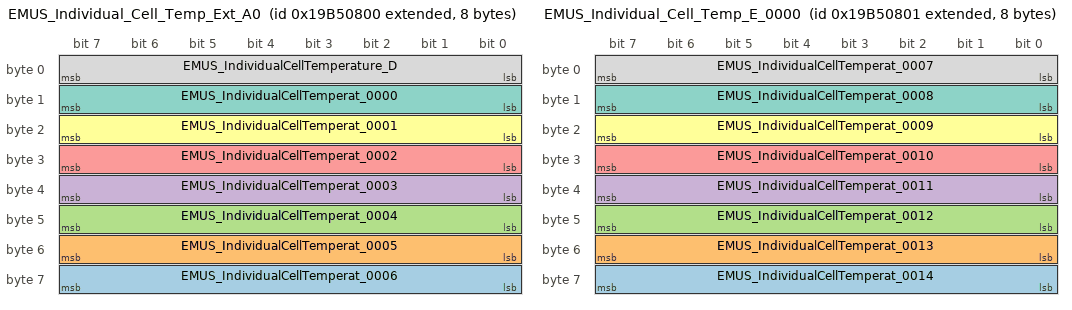
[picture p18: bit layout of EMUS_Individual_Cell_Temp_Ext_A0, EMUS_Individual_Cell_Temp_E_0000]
BO_ 2578778112 EMUS_Individual_Cell_Temp_Ext_A0: 8 EMUS_BMS
 SG_ EMUS_IndividualCellTemperat_0006 : 56|8@1+ (1,-100) [-100|155] "%" Vector__XXX
 SG_ EMUS_IndividualCellTemperat_0005 : 48|8@1+ (1,-100) [-100|155] "%" Vector__XXX
 SG_ EMUS_IndividualCellTemperat_0004 : 40|8@1+ (1,-100) [-100|155] "%" Vector__XXX
 SG_ EMUS_IndividualCellTemperat_0003 : 32|8@1+ (1,-100) [-100|155] "%" Vector__XXX
 SG_ EMUS_IndividualCellTemperat_0002 : 24|8@1+ (1,-100) [-100|155] "%" Vector__XXX
 SG_ EMUS_IndividualCellTemperat_0001 : 16|8@1+ (1,-100) [-100|155] "%" Vector__XXX
 SG_ EMUS_IndividualCellTemperat_0000 : 8|8@1+ (1,-100) [-100|155] "%" Vector__XXX
 SG_ EMUS_IndividualCellTemperature_D : 0|8@1+ (1,-100) [-100|155] "%" Vector__XXX

BO_ 2578778113 EMUS_Individual_Cell_Temp_E_0000: 8 EMUS_BMS
 SG_ EMUS_IndividualCellTemperat_0014 : 56|8@1+ (1,-100) [-100|155] "%" Vector__XXX
 SG_ EMUS_IndividualCellTemperat_0013 : 48|8@1+ (1,-100) [-100|155] "%" Vector__XXX
 SG_ EMUS_IndividualCellTemperat_0012 : 40|8@1+ (1,-100) [-100|155] "%" Vector__XXX
 SG_ EMUS_IndividualCellTemperat_0011 : 32|8@1+ (1,-100) [-100|155] "%" Vector__XXX
 SG_ EMUS_IndividualCellTemperat_0010 : 24|8@1+ (1,-100) [-100|155] "%" Vector__XXX
 SG_ EMUS_IndividualCellTemperat_0009 : 16|8@1+ (1,-100) [-100|155] "%" Vector__XXX
 SG_ EMUS_IndividualCellTemperat_0008 : 8|8@1+ (1,-100) [-100|155] "%" Vector__XXX
 SG_ EMUS_IndividualCellTemperat_0007 : 0|8@1+ (1,-100) [-100|155] "%" Vector__XXX

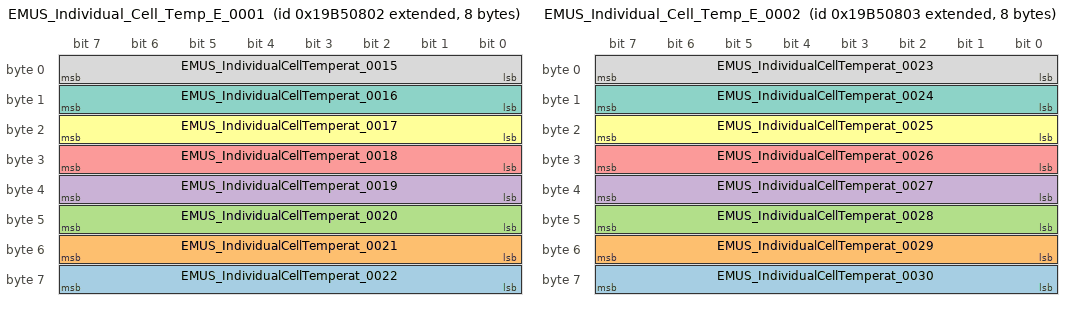
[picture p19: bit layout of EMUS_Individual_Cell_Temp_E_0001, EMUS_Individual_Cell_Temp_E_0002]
BO_ 2578778114 EMUS_Individual_Cell_Temp_E_0001: 8 EMUS_BMS
 SG_ EMUS_IndividualCellTemperat_0022 : 56|8@1+ (1,-100) [-100|155] "%" Vector__XXX
 SG_ EMUS_IndividualCellTemperat_0021 : 48|8@1+ (1,-100) [-100|155] "%" Vector__XXX
 SG_ EMUS_IndividualCellTemperat_0020 : 40|8@1+ (1,-100) [-100|155] "%" Vector__XXX
 SG_ EMUS_IndividualCellTemperat_0019 : 32|8@1+ (1,-100) [-100|155] "%" Vector__XXX
 SG_ EMUS_IndividualCellTemperat_0018 : 24|8@1+ (1,-100) [-100|155] "%" Vector__XXX
 SG_ EMUS_IndividualCellTemperat_0017 : 16|8@1+ (1,-100) [-100|155] "%" Vector__XXX
 SG_ EMUS_IndividualCellTemperat_0016 : 8|8@1+ (1,-100) [-100|155] "%" Vector__XXX
 SG_ EMUS_IndividualCellTemperat_0015 : 0|8@1+ (1,-100) [-100|155] "%" Vector__XXX

BO_ 2578778115 EMUS_Individual_Cell_Temp_E_0002: 8 EMUS_BMS
 SG_ EMUS_IndividualCellTemperat_0030 : 56|8@1+ (1,-100) [-100|155] "%" Vector__XXX
 SG_ EMUS_IndividualCellTemperat_0029 : 48|8@1+ (1,-100) [-100|155] "%" Vector__XXX
 SG_ EMUS_IndividualCellTemperat_0028 : 40|8@1+ (1,-100) [-100|155] "%" Vector__XXX
 SG_ EMUS_IndividualCellTemperat_0027 : 32|8@1+ (1,-100) [-100|155] "%" Vector__XXX
 SG_ EMUS_IndividualCellTemperat_0026 : 24|8@1+ (1,-100) [-100|155] "%" Vector__XXX
 SG_ EMUS_IndividualCellTemperat_0025 : 16|8@1+ (1,-100) [-100|155] "%" Vector__XXX
 SG_ EMUS_IndividualCellTemperat_0024 : 8|8@1+ (1,-100) [-100|155] "%" Vector__XXX
 SG_ EMUS_IndividualCellTemperat_0023 : 0|8@1+ (1,-100) [-100|155] "%" Vector__XXX

BO_ 2578778116 EMUS_Individual_Cell_Temp_E_0003: 8 EMUS_BMS
 SG_ EMUS_IndividualCellTemperat_0038 : 56|8@1+ (1,-100) [-100|155] "%" Vector__XXX
 SG_ EMUS_IndividualCellTemperat_0037 : 48|8@1+ (1,-100) [-100|155] "%" Vector__XXX
 SG_ EMUS_IndividualCellTemperat_0036 : 40|8@1+ (1,-100) [-100|155] "%" Vector__XXX
 SG_ EMUS_IndividualCellTemperat_0035 : 32|8@1+ (1,-100) [-100|155] "%" Vector__XXX
 SG_ EMUS_IndividualCellTemperat_0034 : 24|8@1+ (1,-100) [-100|155] "%" Vector__XXX
 SG_ EMUS_IndividualCellTemperat_0033 : 16|8@1+ (1,-100) [-100|155] "%" Vector__XXX
 SG_ EMUS_IndividualCellTemperat_0032 : 8|8@1+ (1,-100) [-100|155] "%" Vector__XXX
 SG_ EMUS_IndividualCellTemperat_0031 : 0|8@1+ (1,-100) [-100|155] "%" Vector__XXX

BO_ 2578778117 EMUS_Individual_Cell_Temp_E_0004: 8 EMUS_BMS
 SG_ EMUS_IndividualCellTemperat_0046 : 56|8@1+ (1,-100) [-100|155] "%" Vector__XXX
 SG_ EMUS_IndividualCellTemperat_0045 : 48|8@1+ (1,-100) [-100|155] "%" Vector__XXX
 SG_ EMUS_IndividualCellTemperat_0044 : 40|8@1+ (1,-100) [-100|155] "%" Vector__XXX
 SG_ EMUS_IndividualCellTemperat_0043 : 32|8@1+ (1,-100) [-100|155] "%" Vector__XXX
 SG_ EMUS_IndividualCellTemperat_0042 : 24|8@1+ (1,-100) [-100|155] "%" Vector__XXX
 SG_ EMUS_IndividualCellTemperat_0041 : 16|8@1+ (1,-100) [-100|155] "%" Vector__XXX
 SG_ EMUS_IndividualCellTemperat_0040 : 8|8@1+ (1,-100) [-100|155] "%" Vector__XXX
 SG_ EMUS_IndividualCellTemperat_0039 : 0|8@1+ (1,-100) [-100|155] "%" Vector__XXX

BO_ 2578778118 EMUS_Individual_Cell_Temp_E_0005: 8 EMUS_BMS
 SG_ EMUS_IndividualCellTemperat_0054 : 56|8@1+ (1,-100) [-100|155] "%" Vector__XXX
 SG_ EMUS_IndividualCellTemperat_0053 : 48|8@1+ (1,-100) [-100|155] "%" Vector__XXX
 SG_ EMUS_IndividualCellTemperat_0052 : 40|8@1+ (1,-100) [-100|155] "%" Vector__XXX
 SG_ EMUS_IndividualCellTemperat_0051 : 32|8@1+ (1,-100) [-100|155] "%" Vector__XXX
 SG_ EMUS_IndividualCellTemperat_0050 : 24|8@1+ (1,-100) [-100|155] "%" Vector__XXX
 SG_ EMUS_IndividualCellTemperat_0049 : 16|8@1+ (1,-100) [-100|155] "%" Vector__XXX
 SG_ EMUS_IndividualCellTemperat_0048 : 8|8@1+ (1,-100) [-100|155] "%" Vector__XXX
 SG_ EMUS_IndividualCellTemperat_0047 : 0|8@1+ (1,-100) [-100|155] "%" Vector__XXX

BO_ 2578778119 EMUS_Individual_Cell_Temp_E_0006: 8 EMUS_BMS
 SG_ EMUS_IndividualCellTemperat_0062 : 56|8@1+ (1,-100) [-100|155] "%" Vector__XXX
 SG_ EMUS_IndividualCellTemperat_0061 : 48|8@1+ (1,-100) [-100|155] "%" Vector__XXX
 SG_ EMUS_IndividualCellTemperat_0060 : 40|8@1+ (1,-100) [-100|155] "%" Vector__XXX
 SG_ EMUS_IndividualCellTemperat_0059 : 32|8@1+ (1,-100) [-100|155] "%" Vector__XXX
 SG_ EMUS_IndividualCellTemperat_0058 : 24|8@1+ (1,-100) [-100|155] "%" Vector__XXX
 SG_ EMUS_IndividualCellTemperat_0057 : 16|8@1+ (1,-100) [-100|155] "%" Vector__XXX
 SG_ EMUS_IndividualCellTemperat_0056 : 8|8@1+ (1,-100) [-100|155] "%" Vector__XXX
 SG_ EMUS_IndividualCellTemperat_0055 : 0|8@1+ (1,-100) [-100|155] "%" Vector__XXX

BO_ 2578778120 EMUS_Individual_Cell_Temp_E_0007: 8 EMUS_BMS
 SG_ EMUS_IndividualCellTemperat_0070 : 56|8@1+ (1,-100) [-100|155] "%" Vector__XXX
 SG_ EMUS_IndividualCellTemperat_0069 : 48|8@1+ (1,-100) [-100|155] "%" Vector__XXX
 SG_ EMUS_IndividualCellTemperat_0068 : 40|8@1+ (1,-100) [-100|155] "%" Vector__XXX
 SG_ EMUS_IndividualCellTemperat_0067 : 32|8@1+ (1,-100) [-100|155] "%" Vector__XXX
 SG_ EMUS_IndividualCellTemperat_0066 : 24|8@1+ (1,-100) [-100|155] "%" Vector__XXX
 SG_ EMUS_IndividualCellTemperat_0065 : 16|8@1+ (1,-100) [-100|155] "%" Vector__XXX
 SG_ EMUS_IndividualCellTemperat_0064 : 8|8@1+ (1,-100) [-100|155] "%" Vector__XXX
 SG_ EMUS_IndividualCellTemperat_0063 : 0|8@1+ (1,-100) [-100|155] "%" Vector__XXX

BO_ 2578778121 EMUS_Individual_Cell_Temp_E_0008: 8 EMUS_BMS
 SG_ EMUS_IndividualCellTemperat_0078 : 56|8@1+ (1,-100) [-100|155] "%" Vector__XXX
 SG_ EMUS_IndividualCellTemperat_0077 : 48|8@1+ (1,-100) [-100|155] "%" Vector__XXX
 SG_ EMUS_IndividualCellTemperat_0076 : 40|8@1+ (1,-100) [-100|155] "%" Vector__XXX
 SG_ EMUS_IndividualCellTemperat_0075 : 32|8@1+ (1,-100) [-100|155] "%" Vector__XXX
 SG_ EMUS_IndividualCellTemperat_0074 : 24|8@1+ (1,-100) [-100|155] "%" Vector__XXX
 SG_ EMUS_IndividualCellTemperat_0073 : 16|8@1+ (1,-100) [-100|155] "%" Vector__XXX
 SG_ EMUS_IndividualCellTemperat_0072 : 8|8@1+ (1,-100) [-100|155] "%" Vector__XXX
 SG_ EMUS_IndividualCellTemperat_0071 : 0|8@1+ (1,-100) [-100|155] "%" Vector__XXX

BO_ 2578778122 EMUS_Individual_Cell_Temp_Ext_A1: 8 EMUS_BMS
 SG_ EMUS_IndividualCellTemperat_0086 : 56|8@1+ (1,-100) [-100|155] "%" Vector__XXX
 SG_ EMUS_IndividualCellTemperat_0085 : 48|8@1+ (1,-100) [-100|155] "%" Vector__XXX
 SG_ EMUS_IndividualCellTemperat_0084 : 40|8@1+ (1,-100) [-100|155] "%" Vector__XXX
 SG_ EMUS_IndividualCellTemperat_0083 : 32|8@1+ (1,-100) [-100|155] "%" Vector__XXX
 SG_ EMUS_IndividualCellTemperat_0082 : 24|8@1+ (1,-100) [-100|155] "%" Vector__XXX
 SG_ EMUS_IndividualCellTemperat_0081 : 16|8@1+ (1,-100) [-100|155] "%" Vector__XXX
 SG_ EMUS_IndividualCellTemperat_0080 : 8|8@1+ (1,-100) [-100|155] "%" Vector__XXX
 SG_ EMUS_IndividualCellTemperat_0079 : 0|8@1+ (1,-100) [-100|155] "%" Vector__XXX

BO_ 2578776075 EMUS_Individual_Cells_Volta_0017: 8 EMUS_BMS
 SG_ EMUS_IndividualCellVoltage__0149 : 56|8@1+ (0.01,2) [2|4.55] "V" Vector__XXX
 SG_ EMUS_IndividualCellVoltage__0148 : 48|8@1+ (0.01,2) [2|4.55] "V" Vector__XXX
 SG_ EMUS_IndividualCellVoltage__0147 : 40|8@1+ (0.01,2) [2|4.55] "V" Vector__XXX
 SG_ EMUS_IndividualCellVoltage__0146 : 32|8@1+ (0.01,2) [2|4.55] "V" Vector__XXX
 SG_ EMUS_IndividualCellVoltage__0145 : 24|8@1+ (0.01,2) [2|4.55] "V" Vector__XXX
 SG_ EMUS_IndividualCellVoltage__0144 : 16|8@1+ (0.01,2) [2|4.55] "V" Vector__XXX
 SG_ EMUS_IndividualCellVoltage__0143 : 8|8@1+ (0.01,2) [2|4.55] "V" Vector__XXX
 SG_ EMUS_Individual_Cells_Group_Opt_ : 0|8@1+ (1,0) [0|255] "" Vector__XXX

BO_ 2578776077 EMUS_Individual_Cell_Balan_Rate_: 8 EMUS_BMS
 SG_ EMUS_IndividualCellBalancRa_0005 : 56|8@1+ (0.392156862745098,0) [0|100] "%" Vector__XXX
 SG_ EMUS_IndividualCellBalancRa_0004 : 48|8@1+ (0.392156862745098,0) [0|100] "%" Vector__XXX
 SG_ EMUS_IndividualCellBalancRa_0003 : 40|8@1+ (0.392156862745098,0) [0|100] "%" Vector__XXX
 SG_ EMUS_IndividualCellBalancRa_0002 : 32|8@1+ (0.392156862745098,0) [0|100] "%" Vector__XXX
 SG_ EMUS_IndividualCellBalancRa_0001 : 24|8@1+ (0.392156862745098,0) [0|100] "%" Vector__XXX
 SG_ EMUS_IndividualCellBalancRa_0000 : 16|8@1+ (0.392156862745098,0) [0|100] "%" Vector__XXX
 SG_ EMUS_IndividualCellBalancRate_Da : 8|8@1+ (0.392156862745098,0) [0|100] "%" Vector__XXX
 SG_ EMUS_Individual_Cells_Group_0000 : 0|8@1+ (1,0) [0|255] "" Vector__XXX

BO_ 2578776832 EMUS_Individual_Cell_Balan__0000: 8 EMUS_BMS
 SG_ EMUS_IndividualCellBalancRa_0013 : 56|8@1+ (0.392156862745098,0) [0|100] "%" Vector__XXX
 SG_ EMUS_IndividualCellBalancRa_0012 : 48|8@1+ (0.392156862745098,0) [0|100] "%" Vector__XXX
 SG_ EMUS_IndividualCellBalancRa_0011 : 40|8@1+ (0.392156862745098,0) [0|100] "%" Vector__XXX
 SG_ EMUS_IndividualCellBalancRa_0010 : 32|8@1+ (0.392156862745098,0) [0|100] "%" Vector__XXX
 SG_ EMUS_IndividualCellBalancRa_0009 : 24|8@1+ (0.392156862745098,0) [0|100] "%" Vector__XXX
 SG_ EMUS_IndividualCellBalancRa_0008 : 16|8@1+ (0.392156862745098,0) [0|100] "%" Vector__XXX
 SG_ EMUS_IndividualCellBalancRa_0007 : 8|8@1+ (0.392156862745098,0) [0|100] "%" Vector__XXX
 SG_ EMUS_IndividualCellBalancRa_0006 : 0|8@1+ (0.392156862745098,0) [0|100] "%" Vector__XXX

BO_ 2578776833 EMUS_Individual_Cell_Balan__0001: 8 EMUS_BMS
 SG_ EMUS_IndividualCellBalancRa_0021 : 56|8@1+ (0.392156862745098,0) [0|100] "%" Vector__XXX
 SG_ EMUS_IndividualCellBalancRa_0020 : 48|8@1+ (0.392156862745098,0) [0|100] "%" Vector__XXX
 SG_ EMUS_IndividualCellBalancRa_0019 : 40|8@1+ (0.392156862745098,0) [0|100] "%" Vector__XXX
 SG_ EMUS_IndividualCellBalancRa_0018 : 32|8@1+ (0.392156862745098,0) [0|100] "%" Vector__XXX
 SG_ EMUS_IndividualCellBalancRa_0017 : 24|8@1+ (0.392156862745098,0) [0|100] "%" Vector__XXX
 SG_ EMUS_IndividualCellBalancRa_0016 : 16|8@1+ (0.392156862745098,0) [0|100] "%" Vector__XXX
 SG_ EMUS_IndividualCellBalancRa_0015 : 8|8@1+ (0.392156862745098,0) [0|100] "%" Vector__XXX
 SG_ EMUS_IndividualCellBalancRa_0014 : 0|8@1+ (0.392156862745098,0) [0|100] "%" Vector__XXX

BO_ 2578776834 EMUS_Individual_Cell_Balan__0002: 8 EMUS_BMS
 SG_ EMUS_IndividualCellBalancRa_0029 : 56|8@1+ (0.392156862745098,0) [0|100] "%" Vector__XXX
 SG_ EMUS_IndividualCellBalancRa_0028 : 48|8@1+ (0.392156862745098,0) [0|100] "%" Vector__XXX
 SG_ EMUS_IndividualCellBalancRa_0027 : 40|8@1+ (0.392156862745098,0) [0|100] "%" Vector__XXX
 SG_ EMUS_IndividualCellBalancRa_0026 : 32|8@1+ (0.392156862745098,0) [0|100] "%" Vector__XXX
 SG_ EMUS_IndividualCellBalancRa_0025 : 24|8@1+ (0.392156862745098,0) [0|100] "%" Vector__XXX
 SG_ EMUS_IndividualCellBalancRa_0024 : 16|8@1+ (0.392156862745098,0) [0|100] "%" Vector__XXX
 SG_ EMUS_IndividualCellBalancRa_0023 : 8|8@1+ (0.392156862745098,0) [0|100] "%" Vector__XXX
 SG_ EMUS_IndividualCellBalancRa_0022 : 0|8@1+ (0.392156862745098,0) [0|100] "%" Vector__XXX

BO_ 2578776835 EMUS_Individual_Cell_Balan__0003: 8 EMUS_BMS
 SG_ EMUS_IndividualCellBalancRa_0037 : 56|8@1+ (0.392156862745098,0) [0|100] "%" Vector__XXX
 SG_ EMUS_IndividualCellBalancRa_0036 : 48|8@1+ (0.392156862745098,0) [0|100] "%" Vector__XXX
 SG_ EMUS_IndividualCellBalancRa_0035 : 40|8@1+ (0.392156862745098,0) [0|100] "%" Vector__XXX
 SG_ EMUS_IndividualCellBalancRa_0034 : 32|8@1+ (0.392156862745098,0) [0|100] "%" Vector__XXX
 SG_ EMUS_IndividualCellBalancRa_0033 : 24|8@1+ (0.392156862745098,0) [0|100] "%" Vector__XXX
 SG_ EMUS_IndividualCellBalancRa_0032 : 16|8@1+ (0.392156862745098,0) [0|100] "%" Vector__XXX
 SG_ EMUS_IndividualCellBalancRa_0031 : 8|8@1+ (0.392156862745098,0) [0|100] "%" Vector__XXX
 SG_ EMUS_IndividualCellBalancRa_0030 : 0|8@1+ (0.392156862745098,0) [0|100] "%" Vector__XXX

BO_ 2578776836 EMUS_Individual_Cell_Balan__0004: 8 EMUS_BMS
 SG_ EMUS_IndividualCellBalancRa_0045 : 56|8@1+ (0.392156862745098,0) [0|100] "%" Vector__XXX
 SG_ EMUS_IndividualCellBalancRa_0044 : 48|8@1+ (0.392156862745098,0) [0|100] "%" Vector__XXX
 SG_ EMUS_IndividualCellBalancRa_0043 : 40|8@1+ (0.392156862745098,0) [0|100] "%" Vector__XXX
 SG_ EMUS_IndividualCellBalancRa_0042 : 32|8@1+ (0.392156862745098,0) [0|100] "%" Vector__XXX
 SG_ EMUS_IndividualCellBalancRa_0041 : 24|8@1+ (0.392156862745098,0) [0|100] "%" Vector__XXX
 SG_ EMUS_IndividualCellBalancRa_0040 : 16|8@1+ (0.392156862745098,0) [0|100] "%" Vector__XXX
 SG_ EMUS_IndividualCellBalancRa_0039 : 8|8@1+ (0.392156862745098,0) [0|100] "%" Vector__XXX
 SG_ EMUS_IndividualCellBalancRa_0038 : 0|8@1+ (0.392156862745098,0) [0|100] "%" Vector__XXX

BO_ 2578776837 EMUS_Individual_Cell_Balan__0005: 8 EMUS_BMS
 SG_ EMUS_IndividualCellBalancRa_0053 : 56|8@1+ (0.392156862745098,0) [0|100] "%" Vector__XXX
 SG_ EMUS_IndividualCellBalancRa_0052 : 48|8@1+ (0.392156862745098,0) [0|100] "%" Vector__XXX
 SG_ EMUS_IndividualCellBalancRa_0051 : 40|8@1+ (0.392156862745098,0) [0|100] "%" Vector__XXX
 SG_ EMUS_IndividualCellBalancRa_0050 : 32|8@1+ (0.392156862745098,0) [0|100] "%" Vector__XXX
 SG_ EMUS_IndividualCellBalancRa_0049 : 24|8@1+ (0.392156862745098,0) [0|100] "%" Vector__XXX
 SG_ EMUS_IndividualCellBalancRa_0048 : 16|8@1+ (0.392156862745098,0) [0|100] "%" Vector__XXX
 SG_ EMUS_IndividualCellBalancRa_0047 : 8|8@1+ (0.392156862745098,0) [0|100] "%" Vector__XXX
 SG_ EMUS_IndividualCellBalancRa_0046 : 0|8@1+ (0.392156862745098,0) [0|100] "%" Vector__XXX

BO_ 2578776838 EMUS_Individual_Cell_Balan__0006: 8 EMUS_BMS
 SG_ EMUS_IndividualCellBalancRa_0061 : 56|8@1+ (0.392156862745098,0) [0|100] "%" Vector__XXX
 SG_ EMUS_IndividualCellBalancRa_0060 : 48|8@1+ (0.392156862745098,0) [0|100] "%" Vector__XXX
 SG_ EMUS_IndividualCellBalancRa_0059 : 40|8@1+ (0.392156862745098,0) [0|100] "%" Vector__XXX
 SG_ EMUS_IndividualCellBalancRa_0058 : 32|8@1+ (0.392156862745098,0) [0|100] "%" Vector__XXX
 SG_ EMUS_IndividualCellBalancRa_0057 : 24|8@1+ (0.392156862745098,0) [0|100] "%" Vector__XXX
 SG_ EMUS_IndividualCellBalancRa_0056 : 16|8@1+ (0.392156862745098,0) [0|100] "%" Vector__XXX
 SG_ EMUS_IndividualCellBalancRa_0055 : 8|8@1+ (0.392156862745098,0) [0|100] "%" Vector__XXX
 SG_ EMUS_IndividualCellBalancRa_0054 : 0|8@1+ (0.392156862745098,0) [0|100] "%" Vector__XXX

BO_ 2578776839 EMUS_Individual_Cell_Balan__0007: 8 EMUS_BMS
 SG_ EMUS_IndividualCellBalancRa_0069 : 56|8@1+ (0.392156862745098,0) [0|100] "%" Vector__XXX
 SG_ EMUS_IndividualCellBalancRa_0068 : 48|8@1+ (0.392156862745098,0) [0|100] "%" Vector__XXX
 SG_ EMUS_IndividualCellBalancRa_0067 : 40|8@1+ (0.392156862745098,0) [0|100] "%" Vector__XXX
 SG_ EMUS_IndividualCellBalancRa_0066 : 32|8@1+ (0.392156862745098,0) [0|100] "%" Vector__XXX
 SG_ EMUS_IndividualCellBalancRa_0065 : 24|8@1+ (0.392156862745098,0) [0|100] "%" Vector__XXX
 SG_ EMUS_IndividualCellBalancRa_0064 : 16|8@1+ (0.392156862745098,0) [0|100] "%" Vector__XXX
 SG_ EMUS_IndividualCellBalancRa_0063 : 8|8@1+ (0.392156862745098,0) [0|100] "%" Vector__XXX
 SG_ EMUS_IndividualCellBalancRa_0062 : 0|8@1+ (0.392156862745098,0) [0|100] "%" Vector__XXX

BO_ 2578776840 EMUS_Individual_Cell_Balan__0008: 8 EMUS_BMS
 SG_ EMUS_IndividualCellBalancRa_0077 : 56|8@1+ (0.392156862745098,0) [0|100] "%" Vector__XXX
 SG_ EMUS_IndividualCellBalancRa_0076 : 48|8@1+ (0.392156862745098,0) [0|100] "%" Vector__XXX
 SG_ EMUS_IndividualCellBalancRa_0075 : 40|8@1+ (0.392156862745098,0) [0|100] "%" Vector__XXX
 SG_ EMUS_IndividualCellBalancRa_0074 : 32|8@1+ (0.392156862745098,0) [0|100] "%" Vector__XXX
 SG_ EMUS_IndividualCellBalancRa_0073 : 24|8@1+ (0.392156862745098,0) [0|100] "%" Vector__XXX
 SG_ EMUS_IndividualCellBalancRa_0072 : 16|8@1+ (0.392156862745098,0) [0|100] "%" Vector__XXX
 SG_ EMUS_IndividualCellBalancRa_0071 : 8|8@1+ (0.392156862745098,0) [0|100] "%" Vector__XXX
 SG_ EMUS_IndividualCellBalancRa_0070 : 0|8@1+ (0.392156862745098,0) [0|100] "%" Vector__XXX

BO_ 2578776841 EMUS_Individual_Cell_Balan__0009: 8 EMUS_BMS
 SG_ EMUS_IndividualCellBalancRa_0085 : 56|8@1+ (0.392156862745098,0) [0|100] "%" Vector__XXX
 SG_ EMUS_IndividualCellBalancRa_0084 : 48|8@1+ (0.392156862745098,0) [0|100] "%" Vector__XXX
 SG_ EMUS_IndividualCellBalancRa_0083 : 40|8@1+ (0.392156862745098,0) [0|100] "%" Vector__XXX
 SG_ EMUS_IndividualCellBalancRa_0082 : 32|8@1+ (0.392156862745098,0) [0|100] "%" Vector__XXX
 SG_ EMUS_IndividualCellBalancRa_0081 : 24|8@1+ (0.392156862745098,0) [0|100] "%" Vector__XXX
 SG_ EMUS_IndividualCellBalancRa_0080 : 16|8@1+ (0.392156862745098,0) [0|100] "%" Vector__XXX
 SG_ EMUS_IndividualCellBalancRa_0079 : 8|8@1+ (0.392156862745098,0) [0|100] "%" Vector__XXX
 SG_ EMUS_IndividualCellBalancRa_0078 : 0|8@1+ (0.392156862745098,0) [0|100] "%" Vector__XXX

BO_ 2578776842 EMUS_Individual_Cell_Balan__0010: 8 EMUS_BMS
 SG_ EMUS_IndividualCellBalancRa_0093 : 56|8@1+ (0.392156862745098,0) [0|100] "%" Vector__XXX
 SG_ EMUS_IndividualCellBalancRa_0092 : 48|8@1+ (0.392156862745098,0) [0|100] "%" Vector__XXX
 SG_ EMUS_IndividualCellBalancRa_0091 : 40|8@1+ (0.392156862745098,0) [0|100] "%" Vector__XXX
 SG_ EMUS_IndividualCellBalancRa_0090 : 32|8@1+ (0.392156862745098,0) [0|100] "%" Vector__XXX
 SG_ EMUS_IndividualCellBalancRa_0089 : 24|8@1+ (0.392156862745098,0) [0|100] "%" Vector__XXX
 SG_ EMUS_IndividualCellBalancRa_0088 : 16|8@1+ (0.392156862745098,0) [0|100] "%" Vector__XXX
 SG_ EMUS_IndividualCellBalancRa_0087 : 8|8@1+ (0.392156862745098,0) [0|100] "%" Vector__XXX
 SG_ EMUS_IndividualCellBalancRa_0086 : 0|8@1+ (0.392156862745098,0) [0|100] "%" Vector__XXX

BO_ 2578776843 EMUS_Individual_Cell_Balan__0011: 8 EMUS_BMS
 SG_ EMUS_IndividualCellBalancRa_0101 : 56|8@1+ (0.392156862745098,0) [0|100] "%" Vector__XXX
 SG_ EMUS_IndividualCellBalancRa_0100 : 48|8@1+ (0.392156862745098,0) [0|100] "%" Vector__XXX
 SG_ EMUS_IndividualCellBalancRa_0099 : 40|8@1+ (0.392156862745098,0) [0|100] "%" Vector__XXX
 SG_ EMUS_IndividualCellBalancRa_0098 : 32|8@1+ (0.392156862745098,0) [0|100] "%" Vector__XXX
 SG_ EMUS_IndividualCellBalancRa_0097 : 24|8@1+ (0.392156862745098,0) [0|100] "%" Vector__XXX
 SG_ EMUS_IndividualCellBalancRa_0096 : 16|8@1+ (0.392156862745098,0) [0|100] "%" Vector__XXX
 SG_ EMUS_IndividualCellBalancRa_0095 : 8|8@1+ (0.392156862745098,0) [0|100] "%" Vector__XXX
 SG_ EMUS_IndividualCellBalancRa_0094 : 0|8@1+ (0.392156862745098,0) [0|100] "%" Vector__XXX

BO_ 2578776844 EMUS_Individual_Cell_Balan__0012: 8 EMUS_BMS
 SG_ EMUS_IndividualCellBalancRa_0109 : 56|8@1+ (0.392156862745098,0) [0|100] "%" Vector__XXX
 SG_ EMUS_IndividualCellBalancRa_0108 : 48|8@1+ (0.392156862745098,0) [0|100] "%" Vector__XXX
 SG_ EMUS_IndividualCellBalancRa_0107 : 40|8@1+ (0.392156862745098,0) [0|100] "%" Vector__XXX
 SG_ EMUS_IndividualCellBalancRa_0106 : 32|8@1+ (0.392156862745098,0) [0|100] "%" Vector__XXX
 SG_ EMUS_IndividualCellBalancRa_0105 : 24|8@1+ (0.392156862745098,0) [0|100] "%" Vector__XXX
 SG_ EMUS_IndividualCellBalancRa_0104 : 16|8@1+ (0.392156862745098,0) [0|100] "%" Vector__XXX
 SG_ EMUS_IndividualCellBalancRa_0103 : 8|8@1+ (0.392156862745098,0) [0|100] "%" Vector__XXX
 SG_ EMUS_IndividualCellBalancRa_0102 : 0|8@1+ (0.392156862745098,0) [0|100] "%" Vector__XXX

BO_ 2578776845 EMUS_Individual_Cell_Balan__0013: 8 EMUS_BMS
 SG_ EMUS_IndividualCellBalancRa_0117 : 56|8@1+ (0.392156862745098,0) [0|100] "%" Vector__XXX
 SG_ EMUS_IndividualCellBalancRa_0116 : 48|8@1+ (0.392156862745098,0) [0|100] "%" Vector__XXX
 SG_ EMUS_IndividualCellBalancRa_0115 : 40|8@1+ (0.392156862745098,0) [0|100] "%" Vector__XXX
 SG_ EMUS_IndividualCellBalancRa_0114 : 32|8@1+ (0.392156862745098,0) [0|100] "%" Vector__XXX
 SG_ EMUS_IndividualCellBalancRa_0113 : 24|8@1+ (0.392156862745098,0) [0|100] "%" Vector__XXX
 SG_ EMUS_IndividualCellBalancRa_0112 : 16|8@1+ (0.392156862745098,0) [0|100] "%" Vector__XXX
 SG_ EMUS_IndividualCellBalancRa_0111 : 8|8@1+ (0.392156862745098,0) [0|100] "%" Vector__XXX
 SG_ EMUS_IndividualCellBalancRa_0110 : 0|8@1+ (0.392156862745098,0) [0|100] "%" Vector__XXX

BO_ 2578776846 EMUS_Individual_Cell_Balan__0014: 8 EMUS_BMS
 SG_ EMUS_IndividualCellBalancRa_0125 : 56|8@1+ (0.392156862745098,0) [0|100] "%" Vector__XXX
 SG_ EMUS_IndividualCellBalancRa_0124 : 48|8@1+ (0.392156862745098,0) [0|100] "%" Vector__XXX
 SG_ EMUS_IndividualCellBalancRa_0123 : 40|8@1+ (0.392156862745098,0) [0|100] "%" Vector__XXX
 SG_ EMUS_IndividualCellBalancRa_0122 : 32|8@1+ (0.392156862745098,0) [0|100] "%" Vector__XXX
 SG_ EMUS_IndividualCellBalancRa_0121 : 24|8@1+ (0.392156862745098,0) [0|100] "%" Vector__XXX
 SG_ EMUS_IndividualCellBalancRa_0120 : 16|8@1+ (0.392156862745098,0) [0|100] "%" Vector__XXX
 SG_ EMUS_IndividualCellBalancRa_0119 : 8|8@1+ (0.392156862745098,0) [0|100] "%" Vector__XXX
 SG_ EMUS_IndividualCellBalancRa_0118 : 0|8@1+ (0.392156862745098,0) [0|100] "%" Vector__XXX

BO_ 2578776847 EMUS_Individual_Cell_Balan__0015: 8 EMUS_BMS
 SG_ EMUS_IndividualCellBalancRa_0133 : 56|8@1+ (0.392156862745098,0) [0|100] "%" Vector__XXX
 SG_ EMUS_IndividualCellBalancRa_0132 : 48|8@1+ (0.392156862745098,0) [0|100] "%" Vector__XXX
 SG_ EMUS_IndividualCellBalancRa_0131 : 40|8@1+ (0.392156862745098,0) [0|100] "%" Vector__XXX
 SG_ EMUS_IndividualCellBalancRa_0130 : 32|8@1+ (0.392156862745098,0) [0|100] "%" Vector__XXX
 SG_ EMUS_IndividualCellBalancRa_0129 : 24|8@1+ (0.392156862745098,0) [0|100] "%" Vector__XXX
 SG_ EMUS_IndividualCellBalancRa_0128 : 16|8@1+ (0.392156862745098,0) [0|100] "%" Vector__XXX
 SG_ EMUS_IndividualCellBalancRa_0127 : 8|8@1+ (0.392156862745098,0) [0|100] "%" Vector__XXX
 SG_ EMUS_IndividualCellBalancRa_0126 : 0|8@1+ (0.392156862745098,0) [0|100] "%" Vector__XXX

BO_ 2578776848 EMUS_Individual_Cell_Balan__0016: 8 EMUS_BMS
 SG_ EMUS_IndividualCellBalancRa_0141 : 56|8@1+ (0.392156862745098,0) [0|100] "%" Vector__XXX
 SG_ EMUS_IndividualCellBalancRa_0140 : 48|8@1+ (0.392156862745098,0) [0|100] "%" Vector__XXX
 SG_ EMUS_IndividualCellBalancRa_0139 : 40|8@1+ (0.392156862745098,0) [0|100] "%" Vector__XXX
 SG_ EMUS_IndividualCellBalancRa_0138 : 32|8@1+ (0.392156862745098,0) [0|100] "%" Vector__XXX
 SG_ EMUS_IndividualCellBalancRa_0137 : 24|8@1+ (0.392156862745098,0) [0|100] "%" Vector__XXX
 SG_ EMUS_IndividualCellBalancRa_0136 : 16|8@1+ (0.392156862745098,0) [0|100] "%" Vector__XXX
 SG_ EMUS_IndividualCellBalancRa_0135 : 8|8@1+ (0.392156862745098,0) [0|100] "%" Vector__XXX
 SG_ EMUS_IndividualCellBalancRa_0134 : 0|8@1+ (0.392156862745098,0) [0|100] "%" Vector__XXX

BO_ 2578776849 EMUS_Individual_Cell_Balan__0017: 8 EMUS_BMS
 SG_ EMUS_IndividualCellBalancRa_0149 : 56|8@1+ (0.392156862745098,0) [0|100] "%" Vector__XXX
 SG_ EMUS_IndividualCellBalancRa_0148 : 48|8@1+ (0.392156862745098,0) [0|100] "%" Vector__XXX
 SG_ EMUS_IndividualCellBalancRa_0147 : 40|8@1+ (0.392156862745098,0) [0|100] "%" Vector__XXX
 SG_ EMUS_IndividualCellBalancRa_0146 : 32|8@1+ (0.392156862745098,0) [0|100] "%" Vector__XXX
 SG_ EMUS_IndividualCellBalancRa_0145 : 24|8@1+ (0.392156862745098,0) [0|100] "%" Vector__XXX
 SG_ EMUS_IndividualCellBalancRa_0144 : 16|8@1+ (0.392156862745098,0) [0|100] "%" Vector__XXX
 SG_ EMUS_IndividualCellBalancRa_0143 : 8|8@1+ (0.392156862745098,0) [0|100] "%" Vector__XXX
 SG_ EMUS_IndividualCellBalancRa_0142 : 0|8@1+ (0.392156862745098,0) [0|100] "%" Vector__XXX

BO_ 2578776076 EMUS_Individual_Cell_Mod_Te_0017: 8 EMUS_BMS
 SG_ EMUS_IndividualCellModTemp__0149 : 56|8@1+ (1,-100) [-100|155] "%" Vector__XXX
 SG_ EMUS_IndividualCellModTemp__0148 : 48|8@1+ (1,-100) [-100|155] "%" Vector__XXX
 SG_ EMUS_IndividualCellModTemp__0147 : 40|8@1+ (1,-100) [-100|155] "%" Vector__XXX
 SG_ EMUS_IndividualCellModTemp__0146 : 32|8@1+ (1,-100) [-100|155] "%" Vector__XXX
 SG_ EMUS_IndividualCellModTemp__0145 : 24|8@1+ (1,-100) [-100|155] "%" Vector__XXX
 SG_ EMUS_IndividualCellModTemp__0144 : 16|8@1+ (1,-100) [-100|155] "%" Vector__XXX
 SG_ EMUS_IndividualCellModTemp__0143 : 8|8@1+ (1,-100) [-100|155] "%" Vector__XXX
 SG_ EMUS_Individual_Cells_Group_0001 : 0|8@1+ (1,0) [0|255] "" Vector__XXX

BO_ 2578776078 EMUS_Individual_Cell_Temp_Ext_B: 8 EMUS_BMS
 SG_ EMUS_IndividualCellTemperat_0149 : 56|8@1+ (1,-100) [-100|155] "%" Vector__XXX
 SG_ EMUS_IndividualCellTemperat_0148 : 48|8@1+ (1,-100) [-100|155] "%" Vector__XXX
 SG_ EMUS_IndividualCellTemperat_0147 : 40|8@1+ (1,-100) [-100|155] "%" Vector__XXX
 SG_ EMUS_IndividualCellTemperat_0146 : 32|8@1+ (1,-100) [-100|155] "%" Vector__XXX
 SG_ EMUS_IndividualCellTemperat_0145 : 24|8@1+ (1,-100) [-100|155] "%" Vector__XXX
 SG_ EMUS_IndividualCellTemperat_0144 : 16|8@1+ (1,-100) [-100|155] "%" Vector__XXX
 SG_ EMUS_IndividualCellTemperat_0143 : 8|8@1+ (1,-100) [-100|155] "%" Vector__XXX
 SG_ EMUS_Individual_Cells_Group_0002 : 0|8@1+ (1,0) [0|255] "" Vector__XXX

BO_ 2578777091 EMUS_Login_Set_Password_Status_E: 8 EMUS_BMS
 SG_ EMUS_LoginSetPasswordStatus : 0|8@1+ (1,0) [0|255] "" Vector__XXX

BO_ 409 HVTU_TX_Voltage: 6 HVTU
 SG_ HVTU_EMUS_MaxCellVoltage : 40|8@1+ (0.01,2) [2|4.55] "V" Vector__XXX
 SG_ HVTU_EMUS_Pack_Voltage : 16|24@1- (0.01,0) [-83886.08|83886.07] "V" Vector__XXX
 SG_ HVTU_EMUS_AvgCellVoltage : 8|8@1+ (0.01,2) [2|4.55] "V" Vector__XXX
 SG_ HVTU_EMUS_MinCellVoltage : 0|8@1+ (0.01,2) [2|4.55] "V" Vector__XXX

BO_ 473 HVTU_RX_PDO1: 0 Vector__XXX

BO_ 537 HVTU_TX_Balance_Rate: 3 HVTU
 SG_ HVTU_EMUS_MinCellBalanceRate : 16|8@1+ (0.392156862745098,0) [0|100] "%" Vector__XXX
 SG_ HVTU_EMUS_MaxCellBalanceRate : 8|8@1+ (0.392156862745098,0) [0|100] "%" Vector__XXX
 SG_ HVTU_EMUS_AvgCellBalanceRate : 0|8@1+ (0.392156862745098,0) [0|100] "%" Vector__XXX

BO_ 601 HVTU_RX_PDO2: 0 Vector__XXX

BO_ 665 HVTU_TX_Cell_Mod_Temp: 3 HVTU
 SG_ HVTU_EMUS_MinCellModTemp : 16|8@1+ (1,-100) [-100|155] "ï¿½C" Vector__XXX
 SG_ HVTU_EMUS_AvgCellModTemp : 8|8@1+ (1,-100) [-100|155] "ï¿½C" Vector__XXX
 SG_ HVTU_EMUS_MaxCellModTemp : 0|8@1+ (1,-100) [-100|155] "ï¿½C" Vector__XXX

BO_ 729 HVTU_RX_PDO3: 0 Vector__XXX

BO_ 793 HVTU_TX_Cell_Temp: 3 HVTU
 SG_ HVTU_EMUS_MinCellTemp : 16|8@1+ (1,-100) [-100|155] "ï¿½C" Vector__XXX
 SG_ HVTU_EMUS_MaxCellTemp : 8|8@1+ (1,-100) [-100|155] "ï¿½C" Vector__XXX
 SG_ HVTU_EMUS_AvgCellTemp : 0|8@1+ (1,-100) [-100|155] "ï¿½C" Vector__XXX

BO_ 857 HVTU_RX_PDO4: 0 Vector__XXX

BO_ 921 HVTU_TX_Diagnostics: 3 HVTU
 SG_ HVTU_EMUS_Diag_UnderVoltage : 18|1@1+ (1,0) [0|0] "" Vector__XXX
 SG_ HVTU_EMUS_Diag_Pack_UnderVoltage : 17|1@1+ (1,0) [0|0] "" Vector__XXX
 SG_ HVTU_EMUS_Diag_OverVoltage : 16|1@1+ (1,0) [0|0] "" Vector__XXX
 SG_ HVTU_EMUS_Diag_NoCurrentSensor : 15|1@1+ (1,0) [0|0] "" Vector__XXX
 SG_ HVTU_EMUS_Diag_NumOfCellsVal : 14|1@1+ (1,0) [0|0] "" Vector__XXX
 SG_ HVTU_EMUS_Diag_NoCellComm : 13|1@1+ (1,0) [0|0] "" Vector__XXX
 SG_ HVTU_EMUS_Diag_LowVoltage : 12|1@1+ (1,0) [0|0] "" Vector__XXX
 SG_ HVTU_EMUS_Diag_Leackage : 11|1@1+ (1,0) [0|0] "" Vector__XXX
 SG_ HVTU_EMUS_Diag_HighTemp : 10|1@1+ (1,0) [0|0] "" Vector__XXX
 SG_ HVTU_EMUS_Diag_HighCurrent : 9|1@1+ (1,0) [0|0] "" Vector__XXX
 SG_ HVTU_EMUS_Diag_DchrgOverCurrent : 8|1@1+ (1,0) [0|0] "" Vector__XXX
 SG_ HVTU_EMUS_Diag_ChargeOverCurrent : 7|1@1+ (1,0) [0|0] "" Vector__XXX
 SG_ HVTU_EMUS_Diag_CellVoltValid : 6|1@1+ (1,0) [0|0] "" Vector__XXX
 SG_ HVTU_EMUS_Diag_CellTempValid : 5|1@1+ (1,0) [0|0] "" Vector__XXX
 SG_ HVTU_EMUS_Diag_CellOverHeat : 4|1@1+ (1,0) [0|0] "" Vector__XXX
 SG_ HVTU_EMUS_Diag_CellModTempValid : 3|1@1+ (1,0) [0|0] "" Vector__XXX
 SG_ HVTU_EMUS_Diag_CellModOverHeat : 2|1@1+ (1,0) [0|0] "" Vector__XXX
 SG_ HVTU_EMUS_Diag_CellBalanceValid : 1|1@1+ (1,0) [0|0] "" Vector__XXX
 SG_ HVTU_EMUS_Diag_BatChargeFinish : 0|1@1+ (1,0) [0|0] "" Vector__XXX

BO_ 985 HVTU_TX_Current_SOC: 5 HVTU
 SG_ HVTU_EMUS_Pack_SOC : 32|8@1+ (1,0) [0|100] "%" Vector__XXX
 SG_ HVTU_EMUS_Pack_Est_Charge : 16|16@1+ (0.1,0) [0|6553.5] "Ah" Vector__XXX
 SG_ HVTU_EMUS_Pack_Current : 0|16@1- (0.1,0) [-3276.8|3276.7] "A" Vector__XXX

BO_ 1049 HVTU_TX_PDO7: 0 HVTU

BO_ 1113 HVTU_TX_PDO8: 0 HVTU

BO_ 1177 HVTU_TX_PDO9: 0 HVTU

BO_ 1241 HVTU_TX_PDO10: 0 HVTU

BO_ 1305 HVTU_TX_PDO11: 0 HVTU

BO_ 1369 HVTU_TX_PDO12: 0 HVTU

BO_ 1433 HVTU_SDO_Resp: 8 HVTU
 SG_ HVTU_OD_CAN2_DelayedTxMessages m1129 : 16|24@1+ (1,0) [0|16777215] ""  TelemetryNode
 SG_ HVTU_OD_CAN2_ErrorStatus m1128 : 16|8@1+ (1,0) [0|255] ""  TelemetryNode
 SG_ HVTU_OD_CAN2_DiscardedTxMessages m1127 : 16|24@1+ (1,0) [0|16777215] ""  TelemetryNode
 SG_ HVTU_OD_CAN2_Status m1126 : 16|8@1+ (1,0) [0|255] ""  TelemetryNode
 SG_ HVTU_OD_CAN2_Baudrate m1124 : 16|16@1+ (1,0) [125|1000] "kbps"  TelemetryNode
 SG_ HVTU_OD_CAN2_autoErrorReset m1123 : 16|8@1+ (1,0) [0|255] ""  TelemetryNode
 SG_ HVTU_OD_CAN2_lastErrorCode m1122 : 16|32@1+ (1,0) [0|4294967295] ""  TelemetryNode
 SG_ HVTU_OD_CAN2_RxErrCnt m1121 : 16|8@1+ (1,0) [0|255] ""  TelemetryNode
 SG_ HVTU_OD_CAN2_TxErrCnt m1120 : 16|8@1+ (1,0) [0|255] ""  TelemetryNode
 SG_ HVTU_OD_CAN1_DelayedTxMessages m1113 : 16|24@1+ (1,0) [0|16777215] ""  TelemetryNode
 SG_ HVTU_OD_CAN1_ErrorStatus m1112 : 16|8@1+ (1,0) [0|255] ""  TelemetryNode
 SG_ HVTU_OD_CAN1_DiscardedTxMessages m1111 : 16|24@1+ (1,0) [0|16777215] ""  TelemetryNode
 SG_ HVTU_OD_CAN1_Status m1110 : 16|8@1+ (1,0) [0|255] ""  TelemetryNode
 SG_ HVTU_OD_CAN1_Baudrate m1108 : 16|16@1+ (1,0) [125|1000] "kbps"  TelemetryNode
 SG_ HVTU_OD_CAN1_autoErrorReset m1107 : 16|8@1+ (1,0) [0|255] ""  TelemetryNode
 SG_ HVTU_OD_CAN1_lastErrorCode m1106 : 16|32@1+ (1,0) [0|4294967295] ""  TelemetryNode
 SG_ HVTU_OD_CAN1_RxErrCnt m1105 : 16|8@1+ (1,0) [0|255] ""  TelemetryNode
 SG_ HVTU_OD_CAN1_TxErrCnt m1104 : 16|8@1+ (1,0) [0|255] ""  TelemetryNode
 SG_ HVTU_OD_BuildTime m1073 : 16|24@1+ (1,0) [0|16777215] ""  TelemetryNode
 SG_ HVTU_OD_BuildDate m1072 : 16|32@1+ (1,0) [0|4294967295] ""  TelemetryNode
 SG_ HVTU_OD_ChipUID2 m1057 : 16|48@1+ (1,0) [0|281474976710655] ""  TelemetryNode
 SG_ HVTU_OD_ChipUID1 m1056 : 16|48@1+ (1,0) [0|281474976710655] ""  TelemetryNode
 SG_ HVTU_OD_SdcOut m1046 : 16|8@1+ (1,0) [0|255] ""  TelemetryNode
 SG_ HVTU_OD_SdcIn m1045 : 16|8@1+ (1,0) [0|255] ""  TelemetryNode
 SG_ HVTU_OD_runtime m1044 : 16|24@1+ (1,0) [0|16777215] "ms"  TelemetryNode
 SG_ HVTU_OD_InputVoltage m1043 : 16|16@1+ (0.001,0) [0|65.535] "V"  TelemetryNode
 SG_ HVTU_OD_BoardTemp m1042 : 16|16@1+ (0.01,-30) [-30|625.35] "°C"  TelemetryNode
 SG_ HVTU_OD_MemFree m1041 : 16|16@1+ (4,0) [0|262140] "bytes"  TelemetryNode
 SG_ HVTU_OD_CpuUsage m1040 : 16|8@1+ (0.5,0) [0|100] "%"  TelemetryNode
 SG_ HVTU_OD_OdEntrySendInterval m33 : 16|16@1+ (1,0) [0|65535] "ms"  TelemetryNode
 SG_ HVTU_OD_SendOdOnBootup m32 : 16|8@1+ (1,0) [0|255] ""  TelemetryNode
 SG_ HVTU_OD_HeartbeatInterval m16 : 16|16@1+ (1,0) [0|65535] "ms"  TelemetryNode
 SG_ HVTU_OD_DbcVersion m5 : 16|16@1+ (1,0) [0|65535] ""  TelemetryNode
 SG_ HVTU_OD_StackVersion m4 : 16|16@1+ (1,0) [0|65535] ""  TelemetryNode
 SG_ HVTU_OD_ProtocolVersion m3 : 16|16@1+ (1,0) [0|65535] ""  TelemetryNode
 SG_ HVTU_OD_NodeStatus m2 : 16|8@1+ (1,0) [0|255] ""  TelemetryNode
 SG_ HVTU_OD_NodeID m1 : 16|8@1+ (1,0) [0|255] ""  TelemetryNode
 SG_ HVTU_SDO_RespCode : 12|4@1+ (1,0) [0|0] ""  TelemetryNode
 SG_ HVTU_SDO_ID M : 0|12@1+ (1,0) [0|4095] ""  TelemetryNode

BO_ 1497 HVTU_SDO_Req_Up: 8 TelemetryNode
 SG_ HVTU_OD_CAN2_DelayedTxMessages m1129 : 16|24@1+ (1,0) [0|16777215] ""  HVTU
 SG_ HVTU_OD_CAN2_ErrorStatus m1128 : 16|8@1+ (1,0) [0|255] ""  HVTU
 SG_ HVTU_OD_CAN2_DiscardedTxMessages m1127 : 16|24@1+ (1,0) [0|16777215] ""  HVTU
 SG_ HVTU_OD_CAN2_Status m1126 : 16|8@1+ (1,0) [0|255] ""  HVTU
 SG_ HVTU_OD_CAN2_Baudrate m1124 : 16|16@1+ (1,0) [125|1000] "kbps"  HVTU
 SG_ HVTU_OD_CAN2_autoErrorReset m1123 : 16|8@1+ (1,0) [0|255] ""  HVTU
 SG_ HVTU_OD_CAN2_lastErrorCode m1122 : 16|32@1+ (1,0) [0|4294967295] ""  HVTU
 SG_ HVTU_OD_CAN2_RxErrCnt m1121 : 16|8@1+ (1,0) [0|255] ""  HVTU
 SG_ HVTU_OD_CAN2_TxErrCnt m1120 : 16|8@1+ (1,0) [0|255] ""  HVTU
 SG_ HVTU_OD_CAN1_DelayedTxMessages m1113 : 16|24@1+ (1,0) [0|16777215] ""  HVTU
 SG_ HVTU_OD_CAN1_ErrorStatus m1112 : 16|8@1+ (1,0) [0|255] ""  HVTU
 SG_ HVTU_OD_CAN1_DiscardedTxMessages m1111 : 16|24@1+ (1,0) [0|16777215] ""  HVTU
 SG_ HVTU_OD_CAN1_Status m1110 : 16|8@1+ (1,0) [0|255] ""  HVTU
 SG_ HVTU_OD_CAN1_Baudrate m1108 : 16|16@1+ (1,0) [125|1000] "kbps"  HVTU
 SG_ HVTU_OD_CAN1_autoErrorReset m1107 : 16|8@1+ (1,0) [0|255] ""  HVTU
 SG_ HVTU_OD_CAN1_lastErrorCode m1106 : 16|32@1+ (1,0) [0|4294967295] ""  HVTU
 SG_ HVTU_OD_CAN1_RxErrCnt m1105 : 16|8@1+ (1,0) [0|255] ""  HVTU
 SG_ HVTU_OD_CAN1_TxErrCnt m1104 : 16|8@1+ (1,0) [0|255] ""  HVTU
 SG_ HVTU_OD_BuildTime m1073 : 16|24@1+ (1,0) [0|16777215] ""  HVTU
 SG_ HVTU_OD_BuildDate m1072 : 16|32@1+ (1,0) [0|4294967295] ""  HVTU
 SG_ HVTU_OD_ChipUID2 m1057 : 16|48@1+ (1,0) [0|281474976710655] ""  HVTU
 SG_ HVTU_OD_ChipUID1 m1056 : 16|48@1+ (1,0) [0|281474976710655] ""  HVTU
 SG_ HVTU_OD_SdcOut m1046 : 16|8@1+ (1,0) [0|255] ""  HVTU
 SG_ HVTU_OD_SdcIn m1045 : 16|8@1+ (1,0) [0|255] ""  HVTU
 SG_ HVTU_OD_runtime m1044 : 16|24@1+ (1,0) [0|16777215] "ms"  HVTU
 SG_ HVTU_OD_InputVoltage m1043 : 16|16@1+ (0.001,0) [0|65.535] "V"  HVTU
 SG_ HVTU_OD_BoardTemp m1042 : 16|16@1+ (0.01,-30) [-30|625.35] "°C"  HVTU
 SG_ HVTU_OD_MemFree m1041 : 16|16@1+ (4,0) [0|262140] "bytes"  HVTU
 SG_ HVTU_OD_CpuUsage m1040 : 16|8@1+ (0.5,0) [0|100] "%"  HVTU
 SG_ HVTU_OD_OdEntrySendInterval m33 : 16|16@1+ (1,0) [0|65535] "ms"  HVTU
 SG_ HVTU_OD_SendOdOnBootup m32 : 16|8@1+ (1,0) [0|255] ""  HVTU
 SG_ HVTU_OD_HeartbeatInterval m16 : 16|16@1+ (1,0) [0|65535] "ms"  HVTU
 SG_ HVTU_OD_DbcVersion m5 : 16|16@1+ (1,0) [0|65535] ""  HVTU
 SG_ HVTU_OD_StackVersion m4 : 16|16@1+ (1,0) [0|65535] ""  HVTU
 SG_ HVTU_OD_ProtocolVersion m3 : 16|16@1+ (1,0) [0|65535] ""  HVTU
 SG_ HVTU_OD_NodeStatus m2 : 16|8@1+ (1,0) [0|255] ""  HVTU
 SG_ HVTU_OD_NodeID m1 : 16|8@1+ (1,0) [0|255] ""  HVTU
 SG_ HVTU_SDO_ID M : 0|12@1+ (1,0) [0|4095] ""  HVTU

BO_ 1561 HVTU_SDO_Req_Down: 2 TelemetryNode
 SG_ HVTU_SDO_ID M : 0|12@1+ (1,0) [0|4095] ""  HVTU

BO_ 1817 HVTU_Heartbeat: 1 HVTU
 SG_ HVTU_NodeState : 0|8@1+ (1,0) [0|0] ""  Master,TelemetryNode

BO_ 1881 HVTU_BTL_TX: 8 HVTU

BO_ 1945 HVTU_BTL_RX: 8 TelemetryNode

BO_ 162 TelemetryNode_EMCY: 4 TelemetryNode
 SG_ TelemetryNode_E0_OtherError : 12|1@1+ (1,0) [0|0] ""  Master,TelemetryNode
 SG_ TelemetryNode_W0_OtherWarning : 0|1@1+ (1,0) [0|0] ""  Master,TelemetryNode

BO_ 418 TelemetryNode_TX_PDO1: 0 TelemetryNode

BO_ 482 TelemetryNode_RX_Shutdown: 1 Vector__XXX
 SG_ TelemetryNode_RX_Shutdown : 0|8@1+ (1,0) [0|0] "" Vector__XXX

BO_ 546 TelemetryNode_TX_PDO2: 0 TelemetryNode

BO_ 610 TelemetryNode_RX_PDO2: 0 Vector__XXX

BO_ 674 TelemetryNode_TX_PDO3: 0 TelemetryNode

BO_ 738 TelemetryNode_RX_PDO3: 0 Vector__XXX

BO_ 802 TelemetryNode_TX_PDO4: 0 TelemetryNode

BO_ 866 TelemetryNode_RX_PDO4: 0 Vector__XXX

BO_ 930 TelemetryNode_TX_PDO5: 0 TelemetryNode

BO_ 994 TelemetryNode_TX_PDO6: 0 TelemetryNode

BO_ 1058 TelemetryNode_TX_PDO7: 0 TelemetryNode

BO_ 1122 TelemetryNode_TX_PDO8: 0 TelemetryNode

BO_ 1186 TelemetryNode_TX_PDO9: 0 TelemetryNode

BO_ 1250 TelemetryNode_TX_PDO10: 0 TelemetryNode

BO_ 1314 TelemetryNode_TX_CAN_Error: 6 TelemetryNode
 SG_ TelemetryNode_CAN2_TxErrors : 38|10@1+ (1,0) [0|4095] "" Vector__XXX
 SG_ TelemetryNode_CAN2_RxErrors : 24|14@1+ (1,0) [0|16383] "" Vector__XXX
 SG_ TelemetryNode_CAN1_TxErrors : 14|10@1+ (1,0) [0|4095] "" Vector__XXX
 SG_ TelemetryNode_CAN1_RxErrors : 0|14@1+ (1,0) [0|16383] "" Vector__XXX

BO_ 1378 TelemetryNode_TX_Info: 7 TelemetryNode
 SG_ TelemetryNode_Date : 36|18@1+ (1,20200000) [20200000|20462143] "" Vector__XXX
 SG_ TelemetryNode_Time : 18|18@1+ (1,0) [0|262143] "" Vector__XXX
 SG_ TelemetryNode_Temperature : 10|8@1+ (0.4,-10) [-10|92] "Â°C" Vector__XXX
 SG_ TelemetryNode_CpuUsage : 0|10@1+ (0.1,0) [0|102.3] "%" Vector__XXX

BO_ 1442 TelemetryNode_SDO_Resp: 8 TelemetryNode
 SG_ TelemetryNode_OD_CanRestart m2050 : 16|8@1+ (1,0) [0|255] ""  TelemetryNode
 SG_ TelemetryNode_OD_Reboot m2049 : 16|8@1+ (1,0) [0|255] ""  TelemetryNode
 SG_ TelemetryNode_OD_Shutdown m2048 : 16|8@1+ (1,0) [0|255] ""  TelemetryNode
 SG_ TelemetryNode_OD_CAN2_DelayedTxM m1129 : 16|24@1+ (1,0) [0|16777215] ""  TelemetryNode
 SG_ TelemetryNode_OD_CAN2_ErrorStatu m1128 : 16|8@1+ (1,0) [0|255] ""  TelemetryNode
 SG_ TelemetryNode_OD_CAN2_DiscardedT m1127 : 16|24@1+ (1,0) [0|16777215] ""  TelemetryNode
 SG_ TelemetryNode_OD_CAN2_Status m1126 : 16|8@1+ (1,0) [0|255] ""  TelemetryNode
 SG_ TelemetryNode_OD_CAN2_Baudrate m1124 : 16|16@1+ (1,0) [125|1000] "kbps"  TelemetryNode
 SG_ TelemetryNode_OD_CAN2_autoErrorR m1123 : 16|8@1+ (1,0) [0|255] ""  TelemetryNode
 SG_ TelemetryNode_OD_CAN2_lastErrorC m1122 : 16|32@1+ (1,0) [0|4294967295] ""  TelemetryNode
 SG_ TelemetryNode_OD_CAN2_RxErrCnt m1121 : 16|8@1+ (1,0) [0|255] ""  TelemetryNode
 SG_ TelemetryNode_OD_CAN2_TxErrCnt m1120 : 16|8@1+ (1,0) [0|255] ""  TelemetryNode
 SG_ TelemetryNode_OD_CAN1_DelayedTxM m1113 : 16|24@1+ (1,0) [0|16777215] ""  TelemetryNode
 SG_ TelemetryNode_OD_CAN1_ErrorStatu m1112 : 16|8@1+ (1,0) [0|255] ""  TelemetryNode
 SG_ TelemetryNode_OD_CAN1_DiscardedT m1111 : 16|24@1+ (1,0) [0|16777215] ""  TelemetryNode
 SG_ TelemetryNode_OD_CAN1_Status m1110 : 16|8@1+ (1,0) [0|255] ""  TelemetryNode
 SG_ TelemetryNode_OD_CAN1_Baudrate m1108 : 16|16@1+ (1,0) [125|1000] "kbps"  TelemetryNode
 SG_ TelemetryNode_OD_CAN1_autoErrorR m1107 : 16|8@1+ (1,0) [0|255] ""  TelemetryNode
 SG_ TelemetryNode_OD_CAN1_lastErrorC m1106 : 16|32@1+ (1,0) [0|4294967295] ""  TelemetryNode
 SG_ TelemetryNode_OD_CAN1_RxErrCnt m1105 : 16|8@1+ (1,0) [0|255] ""  TelemetryNode
 SG_ TelemetryNode_OD_CAN1_TxErrCnt m1104 : 16|8@1+ (1,0) [0|255] ""  TelemetryNode
 SG_ TelemetryNode_OD_BuildTime m1073 : 16|24@1+ (1,0) [0|16777215] ""  TelemetryNode
 SG_ TelemetryNode_OD_BuildDate m1072 : 16|32@1+ (1,0) [0|4294967295] ""  TelemetryNode
 SG_ TelemetryNode_OD_ChipUID2 m1057 : 16|48@1+ (1,0) [0|281474976710655] ""  TelemetryNode
 SG_ TelemetryNode_OD_ChipUID1 m1056 : 16|48@1+ (1,0) [0|281474976710655] ""  TelemetryNode
 SG_ TelemetryNode_OD_SdcOut m1046 : 16|8@1+ (1,0) [0|255] ""  TelemetryNode
 SG_ TelemetryNode_OD_SdcIn m1045 : 16|8@1+ (1,0) [0|255] ""  TelemetryNode
 SG_ TelemetryNode_OD_runtime m1044 : 16|24@1+ (1,0) [0|16777215] "ms"  TelemetryNode
 SG_ TelemetryNode_OD_InputVoltage m1043 : 16|16@1+ (0.001,0) [0|65.535] "V"  TelemetryNode
 SG_ TelemetryNode_OD_BoardTemp m1042 : 16|16@1+ (0.01,-30) [-30|625.35] "°C"  TelemetryNode
 SG_ TelemetryNode_OD_MemFree m1041 : 16|16@1+ (4,0) [0|262140] "bytes"  TelemetryNode
 SG_ TelemetryNode_OD_CpuUsage m1040 : 16|8@1+ (0.5,0) [0|100] "%"  TelemetryNode
 SG_ TelemetryNode_OD_OdEntrySendInte m33 : 16|16@1+ (1,0) [0|65535] "ms"  TelemetryNode
 SG_ TelemetryNode_OD_SendOdOnBootup m32 : 16|8@1+ (1,0) [0|255] ""  TelemetryNode
 SG_ TelemetryNode_OD_HeartbeatInterv m16 : 16|16@1+ (1,0) [0|65535] "ms"  TelemetryNode
 SG_ TelemetryNode_OD_DbcVersion m5 : 16|16@1+ (1,0) [0|65535] ""  TelemetryNode
 SG_ TelemetryNode_OD_StackVersion m4 : 16|16@1+ (1,0) [0|65535] ""  TelemetryNode
 SG_ TelemetryNode_OD_ProtocolVersion m3 : 16|16@1+ (1,0) [0|65535] ""  TelemetryNode
 SG_ TelemetryNode_OD_NodeStatus m2 : 16|8@1+ (1,0) [0|255] ""  TelemetryNode
 SG_ TelemetryNode_OD_NodeID m1 : 16|8@1+ (1,0) [0|255] ""  TelemetryNode
 SG_ TelemetryNode_SDO_RespCode : 12|4@1+ (1,0) [0|0] ""  TelemetryNode
 SG_ TelemetryNode_SDO_ID M : 0|12@1+ (1,0) [0|4095] ""  TelemetryNode

BO_ 1506 TelemetryNode_SDO_Req_Up: 8 TelemetryNode
 SG_ TelemetryNode_OD_CanRestart m2050 : 16|8@1+ (1,0) [0|255] ""  TelemetryNode
 SG_ TelemetryNode_OD_Reboot m2049 : 16|8@1+ (1,0) [0|255] ""  TelemetryNode
 SG_ TelemetryNode_OD_Shutdown m2048 : 16|8@1+ (1,0) [0|255] ""  TelemetryNode
 SG_ TelemetryNode_OD_CAN2_Delay_0000 m1129 : 16|24@1+ (1,0) [0|16777215] ""  TelemetryNode
 SG_ TelemetryNode_OD_CAN2_Error_0000 m1128 : 16|8@1+ (1,0) [0|255] ""  TelemetryNode
 SG_ TelemetryNode_OD_CAN2_Disca_0000 m1127 : 16|24@1+ (1,0) [0|16777215] ""  TelemetryNode
 SG_ TelemetryNode_OD_CAN2_Status m1126 : 16|8@1+ (1,0) [0|255] ""  TelemetryNode
 SG_ TelemetryNode_OD_CAN2_Baudrate m1124 : 16|16@1+ (1,0) [125|1000] "kbps"  TelemetryNode
 SG_ TelemetryNode_OD_CAN2_autoE_0000 m1123 : 16|8@1+ (1,0) [0|255] ""  TelemetryNode
 SG_ TelemetryNode_OD_CAN2_lastE_0000 m1122 : 16|32@1+ (1,0) [0|4294967295] ""  TelemetryNode
 SG_ TelemetryNode_OD_CAN2_RxErrCnt m1121 : 16|8@1+ (1,0) [0|255] ""  TelemetryNode
 SG_ TelemetryNode_OD_CAN2_TxErrCnt m1120 : 16|8@1+ (1,0) [0|255] ""  TelemetryNode
 SG_ TelemetryNode_OD_CAN1_Delay_0000 m1113 : 16|24@1+ (1,0) [0|16777215] ""  TelemetryNode
 SG_ TelemetryNode_OD_CAN1_Error_0000 m1112 : 16|8@1+ (1,0) [0|255] ""  TelemetryNode
 SG_ TelemetryNode_OD_CAN1_Disca_0000 m1111 : 16|24@1+ (1,0) [0|16777215] ""  TelemetryNode
 SG_ TelemetryNode_OD_CAN1_Status m1110 : 16|8@1+ (1,0) [0|255] ""  TelemetryNode
 SG_ TelemetryNode_OD_CAN1_Baudrate m1108 : 16|16@1+ (1,0) [125|1000] "kbps"  TelemetryNode
 SG_ TelemetryNode_OD_CAN1_autoE_0000 m1107 : 16|8@1+ (1,0) [0|255] ""  TelemetryNode
 SG_ TelemetryNode_OD_CAN1_lastE_0000 m1106 : 16|32@1+ (1,0) [0|4294967295] ""  TelemetryNode
 SG_ TelemetryNode_OD_CAN1_RxErrCnt m1105 : 16|8@1+ (1,0) [0|255] ""  TelemetryNode
 SG_ TelemetryNode_OD_CAN1_TxErrCnt m1104 : 16|8@1+ (1,0) [0|255] ""  TelemetryNode
 SG_ TelemetryNode_OD_BuildTime m1073 : 16|24@1+ (1,0) [0|16777215] ""  TelemetryNode
 SG_ TelemetryNode_OD_BuildDate m1072 : 16|32@1+ (1,0) [0|4294967295] ""  TelemetryNode
 SG_ TelemetryNode_OD_ChipUID2 m1057 : 16|48@1+ (1,0) [0|281474976710655] ""  TelemetryNode
 SG_ TelemetryNode_OD_ChipUID1 m1056 : 16|48@1+ (1,0) [0|281474976710655] ""  TelemetryNode
 SG_ TelemetryNode_OD_SdcOut m1046 : 16|8@1+ (1,0) [0|255] ""  TelemetryNode
 SG_ TelemetryNode_OD_SdcIn m1045 : 16|8@1+ (1,0) [0|255] ""  TelemetryNode
 SG_ TelemetryNode_OD_runtime m1044 : 16|24@1+ (1,0) [0|16777215] "ms"  TelemetryNode
 SG_ TelemetryNode_OD_InputVoltage m1043 : 16|16@1+ (0.001,0) [0|65.535] "V"  TelemetryNode
 SG_ TelemetryNode_OD_BoardTemp m1042 : 16|16@1+ (0.01,-30) [-30|625.35] "°C"  TelemetryNode
 SG_ TelemetryNode_OD_MemFree m1041 : 16|16@1+ (4,0) [0|262140] "bytes"  TelemetryNode
 SG_ TelemetryNode_OD_CpuUsage m1040 : 16|8@1+ (0.5,0) [0|100] "%"  TelemetryNode
 SG_ TelemetryNode_OD_OdEntrySen_0000 m33 : 16|16@1+ (1,0) [0|65535] "ms"  TelemetryNode
 SG_ TelemetryNode_OD_SendOdOnBootup m32 : 16|8@1+ (1,0) [0|255] ""  TelemetryNode
 SG_ TelemetryNode_OD_HeartbeatI_0000 m16 : 16|16@1+ (1,0) [0|65535] "ms"  TelemetryNode
 SG_ TelemetryNode_OD_DbcVersion m5 : 16|16@1+ (1,0) [0|65535] ""  TelemetryNode
 SG_ TelemetryNode_OD_StackVersion m4 : 16|16@1+ (1,0) [0|65535] ""  TelemetryNode
 SG_ TelemetryNode_OD_ProtocolVersion m3 : 16|16@1+ (1,0) [0|65535] ""  TelemetryNode
 SG_ TelemetryNode_OD_NodeStatus m2 : 16|8@1+ (1,0) [0|255] ""  TelemetryNode
 SG_ TelemetryNode_OD_NodeID m1 : 16|8@1+ (1,0) [0|255] ""  TelemetryNode
 SG_ TelemetryNode_SDO_ID M : 0|12@1+ (1,0) [0|4095] ""  TelemetryNode

BO_ 1570 TelemetryNode_SDO_Req_Down: 2 TelemetryNode
 SG_ TelemetryNode_SDO_ID M : 0|12@1+ (1,0) [0|4095] ""  TelemetryNode

BO_ 1826 TelemetryNode_Heartbeat: 1 TelemetryNode
 SG_ TelemetryNode_NodeState : 0|8@1+ (1,0) [0|0] ""  SensorF,Master,TelemetryNode

BO_ 1890 TelemetryNode_BTL_TX: 8 TelemetryNode

BO_ 1954 TelemetryNode_BTL_RX: 8 TelemetryNode

BO_ 161 MDB1_EMCY: 4 MDB1
 SG_ MDB1_E0_OtherError : 12|1@1+ (1,0) [0|0] ""  Master,TelemetryNode
 SG_ MDB1_W0_OtherWarning : 0|1@1+ (1,0) [0|0] ""  Master,TelemetryNode

BO_ 417 MDB1_TX_PDO1: 0 MDB1

BO_ 481 MDB1_RX_PDO1: 0 Vector__XXX

BO_ 545 MDB1_TX_PDO2: 0 MDB1

BO_ 609 MDB1_RX_PDO2: 0 Vector__XXX

BO_ 673 MDB1_TX_PDO3: 0 MDB1

BO_ 737 MDB1_RX_PDO3: 0 Vector__XXX

BO_ 801 MDB1_TX_PDO4: 0 MDB1

BO_ 865 MDB1_RX_PDO4: 0 Vector__XXX

BO_ 929 MDB1_TX_PDO5: 0 MDB1

BO_ 993 MDB1_TX_PDO6: 0 MDB1

BO_ 1057 MDB1_TX_PDO7: 0 MDB1

BO_ 1121 MDB1_TX_PDO8: 0 MDB1

BO_ 1185 MDB1_TX_PDO9: 0 MDB1

BO_ 1249 MDB1_TX_PDO10: 0 MDB1

BO_ 1313 MDB1_TX_PDO11: 0 MDB1

BO_ 1377 MDB1_TX_PDO12: 0 MDB1

BO_ 1441 MDB1_SDO_Resp: 8 MDB1
 SG_ MDB1_OD_CAN2_DelayedTxMessages m1129 : 16|24@1+ (1,0) [0|16777215] ""  TelemetryNode
 SG_ MDB1_OD_CAN2_ErrorStatus m1128 : 16|8@1+ (1,0) [0|255] ""  TelemetryNode
 SG_ MDB1_OD_CAN2_DiscardedTxMessages m1127 : 16|24@1+ (1,0) [0|16777215] ""  TelemetryNode
 SG_ MDB1_OD_CAN2_Status m1126 : 16|8@1+ (1,0) [0|255] ""  TelemetryNode
 SG_ MDB1_OD_CAN2_Baudrate m1124 : 16|16@1+ (1,0) [125|1000] "kbps"  TelemetryNode
 SG_ MDB1_OD_CAN2_autoErrorReset m1123 : 16|8@1+ (1,0) [0|255] ""  TelemetryNode
 SG_ MDB1_OD_CAN2_lastErrorCode m1122 : 16|32@1+ (1,0) [0|4294967295] ""  TelemetryNode
 SG_ MDB1_OD_CAN2_RxErrCnt m1121 : 16|8@1+ (1,0) [0|255] ""  TelemetryNode
 SG_ MDB1_OD_CAN2_TxErrCnt m1120 : 16|8@1+ (1,0) [0|255] ""  TelemetryNode
 SG_ MDB1_OD_CAN1_DelayedTxMessages m1113 : 16|24@1+ (1,0) [0|16777215] ""  TelemetryNode
 SG_ MDB1_OD_CAN1_ErrorStatus m1112 : 16|8@1+ (1,0) [0|255] ""  TelemetryNode
 SG_ MDB1_OD_CAN1_DiscardedTxMessages m1111 : 16|24@1+ (1,0) [0|16777215] ""  TelemetryNode
 SG_ MDB1_OD_CAN1_Status m1110 : 16|8@1+ (1,0) [0|255] ""  TelemetryNode
 SG_ MDB1_OD_CAN1_Baudrate m1108 : 16|16@1+ (1,0) [125|1000] "kbps"  TelemetryNode
 SG_ MDB1_OD_CAN1_autoErrorReset m1107 : 16|8@1+ (1,0) [0|255] ""  TelemetryNode
 SG_ MDB1_OD_CAN1_lastErrorCode m1106 : 16|32@1+ (1,0) [0|4294967295] ""  TelemetryNode
 SG_ MDB1_OD_CAN1_RxErrCnt m1105 : 16|8@1+ (1,0) [0|255] ""  TelemetryNode
 SG_ MDB1_OD_CAN1_TxErrCnt m1104 : 16|8@1+ (1,0) [0|255] ""  TelemetryNode
 SG_ MDB1_OD_BuildTime m1073 : 16|24@1+ (1,0) [0|16777215] ""  TelemetryNode
 SG_ MDB1_OD_BuildDate m1072 : 16|32@1+ (1,0) [0|4294967295] ""  TelemetryNode
 SG_ MDB1_OD_ChipUID2 m1057 : 16|48@1+ (1,0) [0|281474976710655] ""  TelemetryNode
 SG_ MDB1_OD_ChipUID1 m1056 : 16|48@1+ (1,0) [0|281474976710655] ""  TelemetryNode
 SG_ MDB1_OD_SdcOut m1046 : 16|8@1+ (1,0) [0|255] ""  TelemetryNode
 SG_ MDB1_OD_SdcIn m1045 : 16|8@1+ (1,0) [0|255] ""  TelemetryNode
 SG_ MDB1_OD_runtime m1044 : 16|24@1+ (1,0) [0|16777215] "ms"  TelemetryNode
 SG_ MDB1_OD_InputVoltage m1043 : 16|16@1+ (0.001,0) [0|65.535] "V"  TelemetryNode
 SG_ MDB1_OD_BoardTemp m1042 : 16|16@1+ (0.01,-30) [-30|625.35] "°C"  TelemetryNode
 SG_ MDB1_OD_MemFree m1041 : 16|16@1+ (4,0) [0|262140] "bytes"  TelemetryNode
 SG_ MDB1_OD_CpuUsage m1040 : 16|8@1+ (0.5,0) [0|100] "%"  TelemetryNode
 SG_ MDB1_OD_OdEntrySendInterval m33 : 16|16@1+ (1,0) [0|65535] "ms"  TelemetryNode
 SG_ MDB1_OD_SendOdOnBootup m32 : 16|8@1+ (1,0) [0|255] ""  TelemetryNode
 SG_ MDB1_OD_HeartbeatInterval m16 : 16|16@1+ (1,0) [0|65535] "ms"  TelemetryNode
 SG_ MDB1_OD_DbcVersion m5 : 16|16@1+ (1,0) [0|65535] ""  TelemetryNode
 SG_ MDB1_OD_StackVersion m4 : 16|16@1+ (1,0) [0|65535] ""  TelemetryNode
 SG_ MDB1_OD_ProtocolVersion m3 : 16|16@1+ (1,0) [0|65535] ""  TelemetryNode
 SG_ MDB1_OD_NodeStatus m2 : 16|8@1+ (1,0) [0|255] ""  TelemetryNode
 SG_ MDB1_OD_NodeID m1 : 16|8@1+ (1,0) [0|255] ""  TelemetryNode
 SG_ MDB1_SDO_RespCode : 12|4@1+ (1,0) [0|0] ""  TelemetryNode
 SG_ MDB1_SDO_ID M : 0|12@1+ (1,0) [0|4095] ""  TelemetryNode

BO_ 1505 MDB1_SDO_Req_Up: 8 TelemetryNode
 SG_ MDB1_OD_CAN2_DelayedTxMessages m1129 : 16|24@1+ (1,0) [0|16777215] ""  MDB1
 SG_ MDB1_OD_CAN2_ErrorStatus m1128 : 16|8@1+ (1,0) [0|255] ""  MDB1
 SG_ MDB1_OD_CAN2_DiscardedTxMessages m1127 : 16|24@1+ (1,0) [0|16777215] ""  MDB1
 SG_ MDB1_OD_CAN2_Status m1126 : 16|8@1+ (1,0) [0|255] ""  MDB1
 SG_ MDB1_OD_CAN2_Baudrate m1124 : 16|16@1+ (1,0) [125|1000] "kbps"  MDB1
 SG_ MDB1_OD_CAN2_autoErrorReset m1123 : 16|8@1+ (1,0) [0|255] ""  MDB1
 SG_ MDB1_OD_CAN2_lastErrorCode m1122 : 16|32@1+ (1,0) [0|4294967295] ""  MDB1
 SG_ MDB1_OD_CAN2_RxErrCnt m1121 : 16|8@1+ (1,0) [0|255] ""  MDB1
 SG_ MDB1_OD_CAN2_TxErrCnt m1120 : 16|8@1+ (1,0) [0|255] ""  MDB1
 SG_ MDB1_OD_CAN1_DelayedTxMessages m1113 : 16|24@1+ (1,0) [0|16777215] ""  MDB1
 SG_ MDB1_OD_CAN1_ErrorStatus m1112 : 16|8@1+ (1,0) [0|255] ""  MDB1
 SG_ MDB1_OD_CAN1_DiscardedTxMessages m1111 : 16|24@1+ (1,0) [0|16777215] ""  MDB1
 SG_ MDB1_OD_CAN1_Status m1110 : 16|8@1+ (1,0) [0|255] ""  MDB1
 SG_ MDB1_OD_CAN1_Baudrate m1108 : 16|16@1+ (1,0) [125|1000] "kbps"  MDB1
 SG_ MDB1_OD_CAN1_autoErrorReset m1107 : 16|8@1+ (1,0) [0|255] ""  MDB1
 SG_ MDB1_OD_CAN1_lastErrorCode m1106 : 16|32@1+ (1,0) [0|4294967295] ""  MDB1
 SG_ MDB1_OD_CAN1_RxErrCnt m1105 : 16|8@1+ (1,0) [0|255] ""  MDB1
 SG_ MDB1_OD_CAN1_TxErrCnt m1104 : 16|8@1+ (1,0) [0|255] ""  MDB1
 SG_ MDB1_OD_BuildTime m1073 : 16|24@1+ (1,0) [0|16777215] ""  MDB1
 SG_ MDB1_OD_BuildDate m1072 : 16|32@1+ (1,0) [0|4294967295] ""  MDB1
 SG_ MDB1_OD_ChipUID2 m1057 : 16|48@1+ (1,0) [0|281474976710655] ""  MDB1
 SG_ MDB1_OD_ChipUID1 m1056 : 16|48@1+ (1,0) [0|281474976710655] ""  MDB1
 SG_ MDB1_OD_SdcOut m1046 : 16|8@1+ (1,0) [0|255] ""  MDB1
 SG_ MDB1_OD_SdcIn m1045 : 16|8@1+ (1,0) [0|255] ""  MDB1
 SG_ MDB1_OD_runtime m1044 : 16|24@1+ (1,0) [0|16777215] "ms"  MDB1
 SG_ MDB1_OD_InputVoltage m1043 : 16|16@1+ (0.001,0) [0|65.535] "V"  MDB1
 SG_ MDB1_OD_BoardTemp m1042 : 16|16@1+ (0.01,-30) [-30|625.35] "°C"  MDB1
 SG_ MDB1_OD_MemFree m1041 : 16|16@1+ (4,0) [0|262140] "bytes"  MDB1
 SG_ MDB1_OD_CpuUsage m1040 : 16|8@1+ (0.5,0) [0|100] "%"  MDB1
 SG_ MDB1_OD_OdEntrySendInterval m33 : 16|16@1+ (1,0) [0|65535] "ms"  MDB1
 SG_ MDB1_OD_SendOdOnBootup m32 : 16|8@1+ (1,0) [0|255] ""  MDB1
 SG_ MDB1_OD_HeartbeatInterval m16 : 16|16@1+ (1,0) [0|65535] "ms"  MDB1
 SG_ MDB1_OD_DbcVersion m5 : 16|16@1+ (1,0) [0|65535] ""  MDB1
 SG_ MDB1_OD_StackVersion m4 : 16|16@1+ (1,0) [0|65535] ""  MDB1
 SG_ MDB1_OD_ProtocolVersion m3 : 16|16@1+ (1,0) [0|65535] ""  MDB1
 SG_ MDB1_OD_NodeStatus m2 : 16|8@1+ (1,0) [0|255] ""  MDB1
 SG_ MDB1_OD_NodeID m1 : 16|8@1+ (1,0) [0|255] ""  MDB1
 SG_ MDB1_SDO_ID M : 0|12@1+ (1,0) [0|4095] ""  MDB1

BO_ 1569 MDB1_SDO_Req_Down: 2 TelemetryNode
 SG_ MDB1_SDO_ID M : 0|12@1+ (1,0) [0|4095] ""  MDB1

BO_ 1825 MDB1_Heartbeat: 1 MDB1
 SG_ MDB1_NodeState : 0|8@1+ (1,0) [0|0] ""  Master,TelemetryNode

BO_ 1889 MDB1_BTL_TX: 8 MDB1

BO_ 1953 MDB1_BTL_RX: 8 TelemetryNode

BO_ 163 MDB2_EMCY: 4 MDB2
 SG_ MDB2_E0_OtherError : 12|1@1+ (1,0) [0|0] ""  Master,TelemetryNode
 SG_ MDB2_W0_OtherWarning : 0|1@1+ (1,0) [0|0] ""  Master,TelemetryNode

BO_ 419 MDB2_TX_PDO1: 0 MDB2

BO_ 483 MDB2_RX_PDO1: 0 Vector__XXX

BO_ 547 MDB2_TX_PDO2: 0 MDB2

BO_ 611 MDB2_RX_PDO2: 0 Vector__XXX

BO_ 675 MDB2_TX_PDO3: 0 MDB2

BO_ 739 MDB2_RX_PDO3: 0 Vector__XXX

BO_ 803 MDB2_TX_PDO4: 0 MDB2

BO_ 867 MDB2_RX_PDO4: 0 Vector__XXX

BO_ 931 MDB2_TX_PDO5: 0 MDB2

BO_ 995 MDB2_TX_PDO6: 0 MDB2

BO_ 1059 MDB2_TX_PDO7: 0 MDB2

BO_ 1123 MDB2_TX_PDO8: 0 MDB2

BO_ 1187 MDB2_TX_PDO9: 0 MDB2

BO_ 1251 MDB2_TX_PDO10: 0 MDB2

BO_ 1315 MDB2_TX_PDO11: 0 MDB2

BO_ 1379 MDB2_TX_PDO12: 0 MDB2

BO_ 1443 MDB2_SDO_Resp: 8 MDB2
 SG_ MDB2_OD_CAN2_DelayedTxMessages m1129 : 16|24@1+ (1,0) [0|16777215] ""  TelemetryNode
 SG_ MDB2_OD_CAN2_ErrorStatus m1128 : 16|8@1+ (1,0) [0|255] ""  TelemetryNode
 SG_ MDB2_OD_CAN2_DiscardedTxMessages m1127 : 16|24@1+ (1,0) [0|16777215] ""  TelemetryNode
 SG_ MDB2_OD_CAN2_Status m1126 : 16|8@1+ (1,0) [0|255] ""  TelemetryNode
 SG_ MDB2_OD_CAN2_Baudrate m1124 : 16|16@1+ (1,0) [125|1000] "kbps"  TelemetryNode
 SG_ MDB2_OD_CAN2_autoErrorReset m1123 : 16|8@1+ (1,0) [0|255] ""  TelemetryNode
 SG_ MDB2_OD_CAN2_lastErrorCode m1122 : 16|32@1+ (1,0) [0|4294967295] ""  TelemetryNode
 SG_ MDB2_OD_CAN2_RxErrCnt m1121 : 16|8@1+ (1,0) [0|255] ""  TelemetryNode
 SG_ MDB2_OD_CAN2_TxErrCnt m1120 : 16|8@1+ (1,0) [0|255] ""  TelemetryNode
 SG_ MDB2_OD_CAN1_DelayedTxMessages m1113 : 16|24@1+ (1,0) [0|16777215] ""  TelemetryNode
 SG_ MDB2_OD_CAN1_ErrorStatus m1112 : 16|8@1+ (1,0) [0|255] ""  TelemetryNode
 SG_ MDB2_OD_CAN1_DiscardedTxMessages m1111 : 16|24@1+ (1,0) [0|16777215] ""  TelemetryNode
 SG_ MDB2_OD_CAN1_Status m1110 : 16|8@1+ (1,0) [0|255] ""  TelemetryNode
 SG_ MDB2_OD_CAN1_Baudrate m1108 : 16|16@1+ (1,0) [125|1000] "kbps"  TelemetryNode
 SG_ MDB2_OD_CAN1_autoErrorReset m1107 : 16|8@1+ (1,0) [0|255] ""  TelemetryNode
 SG_ MDB2_OD_CAN1_lastErrorCode m1106 : 16|32@1+ (1,0) [0|4294967295] ""  TelemetryNode
 SG_ MDB2_OD_CAN1_RxErrCnt m1105 : 16|8@1+ (1,0) [0|255] ""  TelemetryNode
 SG_ MDB2_OD_CAN1_TxErrCnt m1104 : 16|8@1+ (1,0) [0|255] ""  TelemetryNode
 SG_ MDB2_OD_BuildTime m1073 : 16|24@1+ (1,0) [0|16777215] ""  TelemetryNode
 SG_ MDB2_OD_BuildDate m1072 : 16|32@1+ (1,0) [0|4294967295] ""  TelemetryNode
 SG_ MDB2_OD_ChipUID2 m1057 : 16|48@1+ (1,0) [0|281474976710655] ""  TelemetryNode
 SG_ MDB2_OD_ChipUID1 m1056 : 16|48@1+ (1,0) [0|281474976710655] ""  TelemetryNode
 SG_ MDB2_OD_SdcOut m1046 : 16|8@1+ (1,0) [0|255] ""  TelemetryNode
 SG_ MDB2_OD_SdcIn m1045 : 16|8@1+ (1,0) [0|255] ""  TelemetryNode
 SG_ MDB2_OD_runtime m1044 : 16|24@1+ (1,0) [0|16777215] "ms"  TelemetryNode
 SG_ MDB2_OD_InputVoltage m1043 : 16|16@1+ (0.001,0) [0|65.535] "V"  TelemetryNode
 SG_ MDB2_OD_BoardTemp m1042 : 16|16@1+ (0.01,-30) [-30|625.35] "°C"  TelemetryNode
 SG_ MDB2_OD_MemFree m1041 : 16|16@1+ (4,0) [0|262140] "bytes"  TelemetryNode
 SG_ MDB2_OD_CpuUsage m1040 : 16|8@1+ (0.5,0) [0|100] "%"  TelemetryNode
 SG_ MDB2_OD_OdEntrySendInterval m33 : 16|16@1+ (1,0) [0|65535] "ms"  TelemetryNode
 SG_ MDB2_OD_SendOdOnBootup m32 : 16|8@1+ (1,0) [0|255] ""  TelemetryNode
 SG_ MDB2_OD_HeartbeatInterval m16 : 16|16@1+ (1,0) [0|65535] "ms"  TelemetryNode
 SG_ MDB2_OD_DbcVersion m5 : 16|16@1+ (1,0) [0|65535] ""  TelemetryNode
 SG_ MDB2_OD_StackVersion m4 : 16|16@1+ (1,0) [0|65535] ""  TelemetryNode
 SG_ MDB2_OD_ProtocolVersion m3 : 16|16@1+ (1,0) [0|65535] ""  TelemetryNode
 SG_ MDB2_OD_NodeStatus m2 : 16|8@1+ (1,0) [0|255] ""  TelemetryNode
 SG_ MDB2_OD_NodeID m1 : 16|8@1+ (1,0) [0|255] ""  TelemetryNode
 SG_ MDB2_SDO_RespCode : 12|4@1+ (1,0) [0|0] ""  TelemetryNode
 SG_ MDB2_SDO_ID M : 0|12@1+ (1,0) [0|4095] ""  TelemetryNode

BO_ 1507 MDB2_SDO_Req_Up: 8 TelemetryNode
 SG_ MDB2_OD_CAN2_DelayedTxMessages m1129 : 16|24@1+ (1,0) [0|16777215] ""  MDB2
 SG_ MDB2_OD_CAN2_ErrorStatus m1128 : 16|8@1+ (1,0) [0|255] ""  MDB2
 SG_ MDB2_OD_CAN2_DiscardedTxMessages m1127 : 16|24@1+ (1,0) [0|16777215] ""  MDB2
 SG_ MDB2_OD_CAN2_Status m1126 : 16|8@1+ (1,0) [0|255] ""  MDB2
 SG_ MDB2_OD_CAN2_Baudrate m1124 : 16|16@1+ (1,0) [125|1000] "kbps"  MDB2
 SG_ MDB2_OD_CAN2_autoErrorReset m1123 : 16|8@1+ (1,0) [0|255] ""  MDB2
 SG_ MDB2_OD_CAN2_lastErrorCode m1122 : 16|32@1+ (1,0) [0|4294967295] ""  MDB2
 SG_ MDB2_OD_CAN2_RxErrCnt m1121 : 16|8@1+ (1,0) [0|255] ""  MDB2
 SG_ MDB2_OD_CAN2_TxErrCnt m1120 : 16|8@1+ (1,0) [0|255] ""  MDB2
 SG_ MDB2_OD_CAN1_DelayedTxMessages m1113 : 16|24@1+ (1,0) [0|16777215] ""  MDB2
 SG_ MDB2_OD_CAN1_ErrorStatus m1112 : 16|8@1+ (1,0) [0|255] ""  MDB2
 SG_ MDB2_OD_CAN1_DiscardedTxMessages m1111 : 16|24@1+ (1,0) [0|16777215] ""  MDB2
 SG_ MDB2_OD_CAN1_Status m1110 : 16|8@1+ (1,0) [0|255] ""  MDB2
 SG_ MDB2_OD_CAN1_Baudrate m1108 : 16|16@1+ (1,0) [125|1000] "kbps"  MDB2
 SG_ MDB2_OD_CAN1_autoErrorReset m1107 : 16|8@1+ (1,0) [0|255] ""  MDB2
 SG_ MDB2_OD_CAN1_lastErrorCode m1106 : 16|32@1+ (1,0) [0|4294967295] ""  MDB2
 SG_ MDB2_OD_CAN1_RxErrCnt m1105 : 16|8@1+ (1,0) [0|255] ""  MDB2
 SG_ MDB2_OD_CAN1_TxErrCnt m1104 : 16|8@1+ (1,0) [0|255] ""  MDB2
 SG_ MDB2_OD_BuildTime m1073 : 16|24@1+ (1,0) [0|16777215] ""  MDB2
 SG_ MDB2_OD_BuildDate m1072 : 16|32@1+ (1,0) [0|4294967295] ""  MDB2
 SG_ MDB2_OD_ChipUID2 m1057 : 16|48@1+ (1,0) [0|281474976710655] ""  MDB2
 SG_ MDB2_OD_ChipUID1 m1056 : 16|48@1+ (1,0) [0|281474976710655] ""  MDB2
 SG_ MDB2_OD_SdcOut m1046 : 16|8@1+ (1,0) [0|255] ""  MDB2
 SG_ MDB2_OD_SdcIn m1045 : 16|8@1+ (1,0) [0|255] ""  MDB2
 SG_ MDB2_OD_runtime m1044 : 16|24@1+ (1,0) [0|16777215] "ms"  MDB2
 SG_ MDB2_OD_InputVoltage m1043 : 16|16@1+ (0.001,0) [0|65.535] "V"  MDB2
 SG_ MDB2_OD_BoardTemp m1042 : 16|16@1+ (0.01,-30) [-30|625.35] "°C"  MDB2
 SG_ MDB2_OD_MemFree m1041 : 16|16@1+ (4,0) [0|262140] "bytes"  MDB2
 SG_ MDB2_OD_CpuUsage m1040 : 16|8@1+ (0.5,0) [0|100] "%"  MDB2
 SG_ MDB2_OD_OdEntrySendInterval m33 : 16|16@1+ (1,0) [0|65535] "ms"  MDB2
 SG_ MDB2_OD_SendOdOnBootup m32 : 16|8@1+ (1,0) [0|255] ""  MDB2
 SG_ MDB2_OD_HeartbeatInterval m16 : 16|16@1+ (1,0) [0|65535] "ms"  MDB2
 SG_ MDB2_OD_DbcVersion m5 : 16|16@1+ (1,0) [0|65535] ""  MDB2
 SG_ MDB2_OD_StackVersion m4 : 16|16@1+ (1,0) [0|65535] ""  MDB2
 SG_ MDB2_OD_ProtocolVersion m3 : 16|16@1+ (1,0) [0|65535] ""  MDB2
 SG_ MDB2_OD_NodeStatus m2 : 16|8@1+ (1,0) [0|255] ""  MDB2
 SG_ MDB2_OD_NodeID m1 : 16|8@1+ (1,0) [0|255] ""  MDB2
 SG_ MDB2_SDO_ID M : 0|12@1+ (1,0) [0|4095] ""  MDB2

BO_ 1571 MDB2_SDO_Req_Down: 2 TelemetryNode
 SG_ MDB2_SDO_ID M : 0|12@1+ (1,0) [0|4095] ""  MDB2

BO_ 1827 MDB2_Heartbeat: 1 MDB2
 SG_ MDB2_NodeState : 0|8@1+ (1,0) [0|0] ""  Master,TelemetryNode

BO_ 1891 MDB2_BTL_TX: 8 MDB2

BO_ 1955 MDB2_BTL_RX: 8 TelemetryNode

BO_ 167 MDB3_EMCY: 4 MDB3
 SG_ MDB3_E0_OtherError : 12|1@1+ (1,0) [0|0] ""  Master,TelemetryNode
 SG_ MDB3_W0_OtherWarning : 0|1@1+ (1,0) [0|0] ""  Master,TelemetryNode

BO_ 423 MDB3_TX_PDO1: 0 MDB3

BO_ 487 MDB3_RX_PDO1: 0 Vector__XXX

BO_ 551 MDB3_TX_PDO2: 0 MDB3

BO_ 615 MDB3_RX_PDO2: 0 Vector__XXX

BO_ 679 MDB3_TX_PDO3: 0 MDB3

BO_ 743 MDB3_RX_PDO3: 0 Vector__XXX

BO_ 807 MDB3_TX_PDO4: 0 MDB3

BO_ 871 MDB3_RX_PDO4: 0 Vector__XXX

BO_ 935 MDB3_TX_PDO5: 0 MDB3

BO_ 999 MDB3_TX_PDO6: 0 MDB3

BO_ 1063 MDB3_TX_PDO7: 0 MDB3

BO_ 1127 MDB3_TX_PDO8: 0 MDB3

BO_ 1191 MDB3_TX_PDO9: 0 MDB3

BO_ 1255 MDB3_TX_PDO10: 0 MDB3

BO_ 1319 MDB3_TX_PDO11: 0 MDB3

BO_ 1383 MDB3_TX_PDO12: 0 MDB3

CM_ BO_ 409 "Transmit PDO 1 of node HVTU with Node-ID 0x19";
CM_ BO_ 473 "Receive PDO 1 of node HVTU with Node-ID 0x19";
CM_ BO_ 537 "Transmit PDO 2 of node HVTU with Node-ID 0x19";
CM_ BO_ 601 "Receive PDO 2 of node HVTU with Node-ID 0x19";
CM_ BO_ 665 "Transmit PDO 3 of node HVTU with Node-ID 0x19";
CM_ BO_ 729 "Receive PDO 3 of node HVTU with Node-ID 0x19";
CM_ BO_ 793 "Transmit PDO 4 of node HVTU with Node-ID 0x19";
CM_ BO_ 857 "Receive PDO 4 of node HVTU with Node-ID 0x19";
CM_ BO_ 921 "Transmit PDO 5 of node HVTU with Node-ID 0x19";
CM_ BO_ 985 "Transmit PDO 6 of node HVTU with Node-ID 0x19";
CM_ BO_ 1049 "Transmit PDO 7 of node HVTU with Node-ID 0x19";
CM_ BO_ 1113 "Transmit PDO 8 of node HVTU with Node-ID 0x19";
CM_ BO_ 1177 "Transmit PDO 9 of node HVTU with Node-ID 0x19";
CM_ BO_ 1241 "Transmit PDO 10 of node HVTU with Node-ID 0x19";
CM_ BO_ 1305 "Transmit PDO 11 of node HVTU with Node-ID 0x19";
CM_ BO_ 1369 "Transmit PDO 12 of node HVTU with Node-ID 0x19";
CM_ BO_ 1433 "DO NOT CHANGE ANYTHING HERE!
SDO Response of node HVTU with Node-ID 0x19";
CM_ SG_ 1433 HVTU_OD_CAN2_DelayedTxMessages "Number of delayed TX messages on CAN2 because no messagebox was free.";
CM_ SG_ 1433 HVTU_OD_CAN2_ErrorStatus "Internal error status (e.g. Error active, Error passive, Bus Off)";
CM_ SG_ 1433 HVTU_OD_CAN2_DiscardedTxMessages "Number of discarded TX messages on CAN2 because all messageboxes were full";
CM_ SG_ 1433 HVTU_OD_CAN2_Status "Status of CAN2.";
CM_ SG_ 1433 HVTU_OD_CAN2_Baudrate "Baudrate of CAN.";
CM_ SG_ 1433 HVTU_OD_CAN2_autoErrorReset "Automatic reset of errors.";
CM_ SG_ 1433 HVTU_OD_CAN2_lastErrorCode "Last error code.";
CM_ SG_ 1433 HVTU_OD_CAN2_RxErrCnt "Receive error count of CAN1.";
CM_ SG_ 1433 HVTU_OD_CAN2_TxErrCnt "Transmit error count of CAN1.";
CM_ SG_ 1433 HVTU_OD_CAN1_DelayedTxMessages "Number of delayed TX messages on CAN1 because no messagebox was free.";
CM_ SG_ 1433 HVTU_OD_CAN1_ErrorStatus "Internal error status (e.g. Error active, Error passive, Bus Off)";
CM_ SG_ 1433 HVTU_OD_CAN1_DiscardedTxMessages "Number of discarded TX messages on CAN1 because all messageboxes were full";
CM_ SG_ 1433 HVTU_OD_CAN1_Status "Status of CAN1.";
CM_ SG_ 1433 HVTU_OD_CAN1_Baudrate "Baudrate of CAN.";
CM_ SG_ 1433 HVTU_OD_CAN1_autoErrorReset "Automatic reset of errors.";
CM_ SG_ 1433 HVTU_OD_CAN1_lastErrorCode "Last error code.";
CM_ SG_ 1433 HVTU_OD_CAN1_RxErrCnt "Receive error count of CAN1.";
CM_ SG_ 1433 HVTU_OD_CAN1_TxErrCnt "Transmit error count of CAN1.";
CM_ SG_ 1433 HVTU_OD_BuildTime "Software build time in the format HHMMSS.";
CM_ SG_ 1433 HVTU_OD_BuildDate "Software build date in the format YYYYMMDD.";
CM_ SG_ 1433 HVTU_OD_ChipUID2 "Seccond part of unique ID of microcontroller.";
CM_ SG_ 1433 HVTU_OD_ChipUID1 "First part of unique ID of microcontroller.";
CM_ SG_ 1433 HVTU_OD_SdcOut "Measurement of Shutdown Circuit Output";
CM_ SG_ 1433 HVTU_OD_SdcIn "Measurement of Shutdown Circuit Input";
CM_ SG_ 1433 HVTU_OD_runtime "Runtime of chip in milliseconds.";
CM_ SG_ 1433 HVTU_OD_InputVoltage "Board supply voltage.";
CM_ SG_ 1433 HVTU_OD_BoardTemp "Temperature of board";
CM_ SG_ 1433 HVTU_OD_MemFree "Free memory in bytes.";
CM_ SG_ 1433 HVTU_OD_CpuUsage "Current CPU usage in %.";
CM_ SG_ 1433 HVTU_OD_OdEntrySendInterval "Interval for sending all readable OD entries. Sending is disabled if less than 5 ms.";
CM_ SG_ 1433 HVTU_OD_SendOdOnBootup "Whether to send all OD entries on bootup.";
CM_ SG_ 1433 HVTU_OD_HeartbeatInterval "Heartbeat Interval in milliseconds.";
CM_ SG_ 1433 HVTU_OD_DbcVersion "CANzero DBC version.";
CM_ SG_ 1433 HVTU_OD_StackVersion "CANzero stack version.";
CM_ SG_ 1433 HVTU_OD_ProtocolVersion "CANzero Protocol Version.";
CM_ SG_ 1433 HVTU_OD_NodeStatus "State of the node.";
CM_ SG_ 1433 HVTU_OD_NodeID "CANzero Node-ID.";
CM_ SG_ 1433 HVTU_SDO_RespCode "Response code of SDO access.";
CM_ SG_ 1433 HVTU_SDO_ID "Specifies SDO-ID of HVTU";
CM_ BO_ 1497 "DO NOT CHANGE ANYTHING HERE!
SDO Request Upload to node HVTU with Node-ID 0x19";
CM_ SG_ 1497 HVTU_OD_CAN2_DelayedTxMessages "Number of delayed TX messages on CAN2 because no messagebox was free.";
CM_ SG_ 1497 HVTU_OD_CAN2_ErrorStatus "Internal error status (e.g. Error active, Error passive, Bus Off)";
CM_ SG_ 1497 HVTU_OD_CAN2_DiscardedTxMessages "Number of discarded TX messages on CAN2 because all messageboxes were full";
CM_ SG_ 1497 HVTU_OD_CAN2_Status "Status of CAN2.";
CM_ SG_ 1497 HVTU_OD_CAN2_Baudrate "Baudrate of CAN.";
CM_ SG_ 1497 HVTU_OD_CAN2_autoErrorReset "Automatic reset of errors.";
CM_ SG_ 1497 HVTU_OD_CAN2_lastErrorCode "Last error code.";
CM_ SG_ 1497 HVTU_OD_CAN2_RxErrCnt "Receive error count of CAN1.";
CM_ SG_ 1497 HVTU_OD_CAN2_TxErrCnt "Transmit error count of CAN1.";
CM_ SG_ 1497 HVTU_OD_CAN1_DelayedTxMessages "Number of delayed TX messages on CAN1 because no messagebox was free.";
CM_ SG_ 1497 HVTU_OD_CAN1_ErrorStatus "Internal error status (e.g. Error active, Error passive, Bus Off)";
CM_ SG_ 1497 HVTU_OD_CAN1_DiscardedTxMessages "Number of discarded TX messages on CAN1 because all messageboxes were full";
CM_ SG_ 1497 HVTU_OD_CAN1_Status "Status of CAN1.";
CM_ SG_ 1497 HVTU_OD_CAN1_Baudrate "Baudrate of CAN.";
CM_ SG_ 1497 HVTU_OD_CAN1_autoErrorReset "Automatic reset of errors.";
CM_ SG_ 1497 HVTU_OD_CAN1_lastErrorCode "Last error code.";
CM_ SG_ 1497 HVTU_OD_CAN1_RxErrCnt "Receive error count of CAN1.";
CM_ SG_ 1497 HVTU_OD_CAN1_TxErrCnt "Transmit error count of CAN1.";
CM_ SG_ 1497 HVTU_OD_BuildTime "Software build time in the format HHMMSS.";
CM_ SG_ 1497 HVTU_OD_BuildDate "Software build date in the format YYYYMMDD.";
CM_ SG_ 1497 HVTU_OD_ChipUID2 "Seccond part of unique ID of microcontroller.";
CM_ SG_ 1497 HVTU_OD_ChipUID1 "First part of unique ID of microcontroller.";
CM_ SG_ 1497 HVTU_OD_SdcOut "Measurement of Shutdown Circuit Output";
CM_ SG_ 1497 HVTU_OD_SdcIn "Measurement of Shutdown Circuit Input";
CM_ SG_ 1497 HVTU_OD_runtime "Runtime of chip in milliseconds.";
CM_ SG_ 1497 HVTU_OD_InputVoltage "Board supply voltage.";
CM_ SG_ 1497 HVTU_OD_BoardTemp "Temperature of board";
CM_ SG_ 1497 HVTU_OD_MemFree "Free memory in bytes.";
CM_ SG_ 1497 HVTU_OD_CpuUsage "Current CPU usage in %.";
CM_ SG_ 1497 HVTU_OD_OdEntrySendInterval "Interval for sending all readable OD entries. Sending is disabled if less than 5 ms.";
CM_ SG_ 1497 HVTU_OD_SendOdOnBootup "Whether to send all OD entries on bootup.";
CM_ SG_ 1497 HVTU_OD_HeartbeatInterval "Heartbeat Interval in milliseconds.";
CM_ SG_ 1497 HVTU_OD_DbcVersion "CANzero DBC version.";
CM_ SG_ 1497 HVTU_OD_StackVersion "CANzero stack version.";
CM_ SG_ 1497 HVTU_OD_ProtocolVersion "CANzero Protocol Version.";
CM_ SG_ 1497 HVTU_OD_NodeStatus "State of the node.";
CM_ SG_ 1497 HVTU_OD_NodeID "CANzero Node-ID.";
CM_ SG_ 1497 HVTU_SDO_ID "Specifies SDO-ID of HVTU";
CM_ BO_ 1561 "DO NOT CHANGE ANYTHING HERE!
SDO Request Download from node HVTU with Node-ID 0x19";
CM_ SG_ 1561 HVTU_SDO_ID "Specifies SDO-ID of HVTU";
CM_ BO_ 1817 "Heartbeat of node HVTU with Node-ID 0x19";
CM_ SG_ 1817 HVTU_NodeState "Heartbeat status of node HVTU";
CM_ BO_ 1881 "Bootloader transmit from node HVTU with Node-ID 0x19";
CM_ BO_ 1945 "Bootloader receive by node HVTU with Node-ID 0x19";
CM_ BO_ 162 "Emergency message of node TelemetryNode with Node-ID 0x22";
CM_ SG_ 162 TelemetryNode_E0_OtherError "Other error.";
CM_ SG_ 162 TelemetryNode_W0_OtherWarning "Other warning.";
CM_ BO_ 418 "Transmit PDO 1 of node TelemetryNode with Node-ID 0x22";
CM_ BO_ 482 "Receive PDO 1 of node TelemetryNode with Node-ID 0x22";
CM_ BO_ 546 "Transmit PDO 2 of node TelemetryNode with Node-ID 0x22";
CM_ BO_ 610 "Receive PDO 2 of node TelemetryNode with Node-ID 0x22";
CM_ BO_ 674 "Transmit PDO 3 of node TelemetryNode with Node-ID 0x22";
CM_ BO_ 738 "Receive PDO 3 of node TelemetryNode with Node-ID 0x22";
CM_ BO_ 802 "Transmit PDO 4 of node TelemetryNode with Node-ID 0x22";
CM_ BO_ 866 "Receive PDO 4 of node TelemetryNode with Node-ID 0x22";
CM_ BO_ 930 "Transmit PDO 5 of node TelemetryNode with Node-ID 0x22";
CM_ BO_ 994 "Transmit PDO 6 of node TelemetryNode with Node-ID 0x22";
CM_ BO_ 1058 "Transmit PDO 7 of node TelemetryNode with Node-ID 0x22";
CM_ BO_ 1122 "Transmit PDO 8 of node TelemetryNode with Node-ID 0x22";
CM_ BO_ 1186 "Transmit PDO 9 of node TelemetryNode with Node-ID 0x22";
CM_ BO_ 1250 "Transmit PDO 10 of node TelemetryNode with Node-ID 0x22";
CM_ BO_ 1314 "Transmit PDO 11 of node TelemetryNode with Node-ID 0x22";
CM_ BO_ 1378 "Transmit PDO 12 of node TelemetryNode with Node-ID 0x22";
CM_ BO_ 1442 "DO NOT CHANGE ANYTHING HERE!
SDO Response of node TelemetryNode with Node-ID 0x22";
CM_ SG_ 1442 TelemetryNode_OD_CanRestart "Restart CAN interfaces.";
CM_ SG_ 1442 TelemetryNode_OD_Reboot "Reboot the Telemetry Node.";
CM_ SG_ 1442 TelemetryNode_OD_Shutdown "Shutdown the Telemetry Node.";
CM_ SG_ 1442 TelemetryNode_OD_CAN2_DelayedTxM "Number of delayed TX messages on CAN2 because no messagebox was free.";
CM_ SG_ 1442 TelemetryNode_OD_CAN2_ErrorStatu "Internal error status (e.g. Error active, Error passive, Bus Off)";
CM_ SG_ 1442 TelemetryNode_OD_CAN2_DiscardedT "Number of discarded TX messages on CAN2 because all messageboxes were full";
CM_ SG_ 1442 TelemetryNode_OD_CAN2_Status "Status of CAN2.";
CM_ SG_ 1442 TelemetryNode_OD_CAN2_Baudrate "Baudrate of CAN.";
CM_ SG_ 1442 TelemetryNode_OD_CAN2_autoErrorR "Automatic reset of errors.";
CM_ SG_ 1442 TelemetryNode_OD_CAN2_lastErrorC "Last error code.";
CM_ SG_ 1442 TelemetryNode_OD_CAN2_RxErrCnt "Receive error count of CAN1.";
CM_ SG_ 1442 TelemetryNode_OD_CAN2_TxErrCnt "Transmit error count of CAN1.";
CM_ SG_ 1442 TelemetryNode_OD_CAN1_DelayedTxM "Number of delayed TX messages on CAN1 because no messagebox was free.";
CM_ SG_ 1442 TelemetryNode_OD_CAN1_ErrorStatu "Internal error status (e.g. Error active, Error passive, Bus Off)";
CM_ SG_ 1442 TelemetryNode_OD_CAN1_DiscardedT "Number of discarded TX messages on CAN1 because all messageboxes were full";
CM_ SG_ 1442 TelemetryNode_OD_CAN1_Status "Status of CAN1.";
CM_ SG_ 1442 TelemetryNode_OD_CAN1_Baudrate "Baudrate of CAN.";
CM_ SG_ 1442 TelemetryNode_OD_CAN1_autoErrorR "Automatic reset of errors.";
CM_ SG_ 1442 TelemetryNode_OD_CAN1_lastErrorC "Last error code.";
CM_ SG_ 1442 TelemetryNode_OD_CAN1_RxErrCnt "Receive error count of CAN1.";
CM_ SG_ 1442 TelemetryNode_OD_CAN1_TxErrCnt "Transmit error count of CAN1.";
CM_ SG_ 1442 TelemetryNode_OD_BuildTime "Software build time in the format HHMMSS.";
CM_ SG_ 1442 TelemetryNode_OD_BuildDate "Software build date in the format YYYYMMDD.";
CM_ SG_ 1442 TelemetryNode_OD_ChipUID2 "Seccond part of unique ID of microcontroller.";
CM_ SG_ 1442 TelemetryNode_OD_ChipUID1 "First part of unique ID of microcontroller.";
CM_ SG_ 1442 TelemetryNode_OD_SdcOut "Measurement of Shutdown Circuit Output";
CM_ SG_ 1442 TelemetryNode_OD_SdcIn "Measurement of Shutdown Circuit Input";
CM_ SG_ 1442 TelemetryNode_OD_runtime "Runtime of chip in milliseconds.";
CM_ SG_ 1442 TelemetryNode_OD_InputVoltage "Board supply voltage.";
CM_ SG_ 1442 TelemetryNode_OD_BoardTemp "Temperature of board";
CM_ SG_ 1442 TelemetryNode_OD_MemFree "Free memory in bytes.";
CM_ SG_ 1442 TelemetryNode_OD_CpuUsage "Current CPU usage in %.";
CM_ SG_ 1442 TelemetryNode_OD_OdEntrySendInte "Interval for sending all readable OD entries. Sending is disabled if less than 5 ms.";
CM_ SG_ 1442 TelemetryNode_OD_SendOdOnBootup "Whether to send all OD entries on bootup.";
CM_ SG_ 1442 TelemetryNode_OD_HeartbeatInterv "Heartbeat Interval in milliseconds.";
CM_ SG_ 1442 TelemetryNode_OD_DbcVersion "CANzero DBC version.";
CM_ SG_ 1442 TelemetryNode_OD_StackVersion "CANzero stack version.";
CM_ SG_ 1442 TelemetryNode_OD_ProtocolVersion "CANzero Protocol Version.";
CM_ SG_ 1442 TelemetryNode_OD_NodeStatus "State of the node.";
CM_ SG_ 1442 TelemetryNode_OD_NodeID "CANzero Node-ID.";
CM_ SG_ 1442 TelemetryNode_SDO_RespCode "Response code of SDO access.";
CM_ SG_ 1442 TelemetryNode_SDO_ID "Specifies SDO-ID of TelemetryNode";
CM_ BO_ 1506 "DO NOT CHANGE ANYTHING HERE!
SDO Request Upload to node TelemetryNode with Node-ID 0x22";
CM_ SG_ 1506 TelemetryNode_OD_CanRestart "Restart CAN interfaces.";
CM_ SG_ 1506 TelemetryNode_OD_Reboot "Reboot the Telemetry Node.";
CM_ SG_ 1506 TelemetryNode_OD_Shutdown "Shutdown the Telemetry Node.";
CM_ SG_ 1506 TelemetryNode_OD_CAN2_Delay_0000 "Number of delayed TX messages on CAN2 because no messagebox was free.";
CM_ SG_ 1506 TelemetryNode_OD_CAN2_Error_0000 "Internal error status (e.g. Error active, Error passive, Bus Off)";
CM_ SG_ 1506 TelemetryNode_OD_CAN2_Disca_0000 "Number of discarded TX messages on CAN2 because all messageboxes were full";
CM_ SG_ 1506 TelemetryNode_OD_CAN2_Status "Status of CAN2.";
CM_ SG_ 1506 TelemetryNode_OD_CAN2_Baudrate "Baudrate of CAN.";
CM_ SG_ 1506 TelemetryNode_OD_CAN2_autoE_0000 "Automatic reset of errors.";
CM_ SG_ 1506 TelemetryNode_OD_CAN2_lastE_0000 "Last error code.";
CM_ SG_ 1506 TelemetryNode_OD_CAN2_RxErrCnt "Receive error count of CAN1.";
CM_ SG_ 1506 TelemetryNode_OD_CAN2_TxErrCnt "Transmit error count of CAN1.";
CM_ SG_ 1506 TelemetryNode_OD_CAN1_Delay_0000 "Number of delayed TX messages on CAN1 because no messagebox was free.";
CM_ SG_ 1506 TelemetryNode_OD_CAN1_Error_0000 "Internal error status (e.g. Error active, Error passive, Bus Off)";
CM_ SG_ 1506 TelemetryNode_OD_CAN1_Disca_0000 "Number of discarded TX messages on CAN1 because all messageboxes were full";
CM_ SG_ 1506 TelemetryNode_OD_CAN1_Status "Status of CAN1.";
CM_ SG_ 1506 TelemetryNode_OD_CAN1_Baudrate "Baudrate of CAN.";
CM_ SG_ 1506 TelemetryNode_OD_CAN1_autoE_0000 "Automatic reset of errors.";
CM_ SG_ 1506 TelemetryNode_OD_CAN1_lastE_0000 "Last error code.";
CM_ SG_ 1506 TelemetryNode_OD_CAN1_RxErrCnt "Receive error count of CAN1.";
CM_ SG_ 1506 TelemetryNode_OD_CAN1_TxErrCnt "Transmit error count of CAN1.";
CM_ SG_ 1506 TelemetryNode_OD_BuildTime "Software build time in the format HHMMSS.";
CM_ SG_ 1506 TelemetryNode_OD_BuildDate "Software build date in the format YYYYMMDD.";
CM_ SG_ 1506 TelemetryNode_OD_ChipUID2 "Seccond part of unique ID of microcontroller.";
CM_ SG_ 1506 TelemetryNode_OD_ChipUID1 "First part of unique ID of microcontroller.";
CM_ SG_ 1506 TelemetryNode_OD_SdcOut "Measurement of Shutdown Circuit Output";
CM_ SG_ 1506 TelemetryNode_OD_SdcIn "Measurement of Shutdown Circuit Input";
CM_ SG_ 1506 TelemetryNode_OD_runtime "Runtime of chip in milliseconds.";
CM_ SG_ 1506 TelemetryNode_OD_InputVoltage "Board supply voltage.";
CM_ SG_ 1506 TelemetryNode_OD_BoardTemp "Temperature of board";
CM_ SG_ 1506 TelemetryNode_OD_MemFree "Free memory in bytes.";
CM_ SG_ 1506 TelemetryNode_OD_CpuUsage "Current CPU usage in %.";
CM_ SG_ 1506 TelemetryNode_OD_OdEntrySen_0000 "Interval for sending all readable OD entries. Sending is disabled if less than 5 ms.";
CM_ SG_ 1506 TelemetryNode_OD_SendOdOnBootup "Whether to send all OD entries on bootup.";
CM_ SG_ 1506 TelemetryNode_OD_HeartbeatI_0000 "Heartbeat Interval in milliseconds.";
CM_ SG_ 1506 TelemetryNode_OD_DbcVersion "CANzero DBC version.";
CM_ SG_ 1506 TelemetryNode_OD_StackVersion "CANzero stack version.";
CM_ SG_ 1506 TelemetryNode_OD_ProtocolVersion "CANzero Protocol Version.";
CM_ SG_ 1506 TelemetryNode_OD_NodeStatus "State of the node.";
CM_ SG_ 1506 TelemetryNode_OD_NodeID "CANzero Node-ID.";
CM_ SG_ 1506 TelemetryNode_SDO_ID "Specifies SDO-ID of TelemetryNode";
CM_ BO_ 1570 "DO NOT CHANGE ANYTHING HERE!
SDO Request Download from node TelemetryNode with Node-ID 0x22";
CM_ SG_ 1570 TelemetryNode_SDO_ID "Specifies SDO-ID of TelemetryNode";
CM_ BO_ 1826 "Heartbeat of node TelemetryNode with Node-ID 0x22";
CM_ SG_ 1826 TelemetryNode_NodeState "Heartbeat status of node TelemetryNode";
CM_ BO_ 1890 "Bootloader transmit from node TelemetryNode with Node-ID 0x22";
CM_ BO_ 1954 "Bootloader receive by node TelemetryNode with Node-ID 0x22";
CM_ BO_ 161 "Emergency message of node MDB1 with Node-ID 0x21";
CM_ SG_ 161 MDB1_E0_OtherError "Other error.";
CM_ SG_ 161 MDB1_W0_OtherWarning "Other warning.";
CM_ BO_ 417 "Transmit PDO 1 of node MDB1 with Node-ID 0x21";
CM_ BO_ 481 "Receive PDO 1 of node MDB1 with Node-ID 0x21";
CM_ BO_ 545 "Transmit PDO 2 of node MDB1 with Node-ID 0x21";
CM_ BO_ 609 "Receive PDO 2 of node MDB1 with Node-ID 0x21";
CM_ BO_ 673 "Transmit PDO 3 of node MDB1 with Node-ID 0x21";
CM_ BO_ 737 "Receive PDO 3 of node MDB1 with Node-ID 0x21";
CM_ BO_ 801 "Transmit PDO 4 of node MDB1 with Node-ID 0x21";
CM_ BO_ 865 "Receive PDO 4 of node MDB1 with Node-ID 0x21";
CM_ BO_ 929 "Transmit PDO 5 of node MDB1 with Node-ID 0x21";
CM_ BO_ 993 "Transmit PDO 6 of node MDB1 with Node-ID 0x21";
CM_ BO_ 1057 "Transmit PDO 7 of node MDB1 with Node-ID 0x21";
CM_ BO_ 1121 "Transmit PDO 8 of node MDB1 with Node-ID 0x21";
CM_ BO_ 1185 "Transmit PDO 9 of node MDB1 with Node-ID 0x21";
CM_ BO_ 1249 "Transmit PDO 10 of node MDB1 with Node-ID 0x21";
CM_ BO_ 1313 "Transmit PDO 11 of node MDB1 with Node-ID 0x21";
CM_ BO_ 1377 "Transmit PDO 12 of node MDB1 with Node-ID 0x21";
CM_ BO_ 1441 "DO NOT CHANGE ANYTHING HERE!
SDO Response of node MDB1 with Node-ID 0x21";
CM_ SG_ 1441 MDB1_OD_CAN2_DelayedTxMessages "Number of delayed TX messages on CAN2 because no messagebox was free.";
CM_ SG_ 1441 MDB1_OD_CAN2_ErrorStatus "Internal error status (e.g. Error active, Error passive, Bus Off)";
CM_ SG_ 1441 MDB1_OD_CAN2_DiscardedTxMessages "Number of discarded TX messages on CAN2 because all messageboxes were full";
CM_ SG_ 1441 MDB1_OD_CAN2_Status "Status of CAN2.";
CM_ SG_ 1441 MDB1_OD_CAN2_Baudrate "Baudrate of CAN.";
CM_ SG_ 1441 MDB1_OD_CAN2_autoErrorReset "Automatic reset of errors.";
CM_ SG_ 1441 MDB1_OD_CAN2_lastErrorCode "Last error code.";
CM_ SG_ 1441 MDB1_OD_CAN2_RxErrCnt "Receive error count of CAN1.";
CM_ SG_ 1441 MDB1_OD_CAN2_TxErrCnt "Transmit error count of CAN1.";
CM_ SG_ 1441 MDB1_OD_CAN1_DelayedTxMessages "Number of delayed TX messages on CAN1 because no messagebox was free.";
CM_ SG_ 1441 MDB1_OD_CAN1_ErrorStatus "Internal error status (e.g. Error active, Error passive, Bus Off)";
CM_ SG_ 1441 MDB1_OD_CAN1_DiscardedTxMessages "Number of discarded TX messages on CAN1 because all messageboxes were full";
CM_ SG_ 1441 MDB1_OD_CAN1_Status "Status of CAN1.";
CM_ SG_ 1441 MDB1_OD_CAN1_Baudrate "Baudrate of CAN.";
CM_ SG_ 1441 MDB1_OD_CAN1_autoErrorReset "Automatic reset of errors.";
CM_ SG_ 1441 MDB1_OD_CAN1_lastErrorCode "Last error code.";
CM_ SG_ 1441 MDB1_OD_CAN1_RxErrCnt "Receive error count of CAN1.";
CM_ SG_ 1441 MDB1_OD_CAN1_TxErrCnt "Transmit error count of CAN1.";
CM_ SG_ 1441 MDB1_OD_BuildTime "Software build time in the format HHMMSS.";
CM_ SG_ 1441 MDB1_OD_BuildDate "Software build date in the format YYYYMMDD.";
CM_ SG_ 1441 MDB1_OD_ChipUID2 "Seccond part of unique ID of microcontroller.";
CM_ SG_ 1441 MDB1_OD_ChipUID1 "First part of unique ID of microcontroller.";
CM_ SG_ 1441 MDB1_OD_SdcOut "Measurement of Shutdown Circuit Output";
CM_ SG_ 1441 MDB1_OD_SdcIn "Measurement of Shutdown Circuit Input";
CM_ SG_ 1441 MDB1_OD_runtime "Runtime of chip in milliseconds.";
CM_ SG_ 1441 MDB1_OD_InputVoltage "Board supply voltage.";
CM_ SG_ 1441 MDB1_OD_BoardTemp "Temperature of board";
CM_ SG_ 1441 MDB1_OD_MemFree "Free memory in bytes.";
CM_ SG_ 1441 MDB1_OD_CpuUsage "Current CPU usage in %.";
CM_ SG_ 1441 MDB1_OD_OdEntrySendInterval "Interval for sending all readable OD entries. Sending is disabled if less than 5 ms.";
CM_ SG_ 1441 MDB1_OD_SendOdOnBootup "Whether to send all OD entries on bootup.";
CM_ SG_ 1441 MDB1_OD_HeartbeatInterval "Heartbeat Interval in milliseconds.";
CM_ SG_ 1441 MDB1_OD_DbcVersion "CANzero DBC version.";
CM_ SG_ 1441 MDB1_OD_StackVersion "CANzero stack version.";
CM_ SG_ 1441 MDB1_OD_ProtocolVersion "CANzero Protocol Version.";
CM_ SG_ 1441 MDB1_OD_NodeStatus "State of the node.";
CM_ SG_ 1441 MDB1_OD_NodeID "CANzero Node-ID.";
CM_ SG_ 1441 MDB1_SDO_RespCode "Response code of SDO access.";
CM_ SG_ 1441 MDB1_SDO_ID "Specifies SDO-ID of MDB1";
CM_ BO_ 1505 "DO NOT CHANGE ANYTHING HERE!
SDO Request Upload to node MDB1 with Node-ID 0x21";
CM_ SG_ 1505 MDB1_OD_CAN2_DelayedTxMessages "Number of delayed TX messages on CAN2 because no messagebox was free.";
CM_ SG_ 1505 MDB1_OD_CAN2_ErrorStatus "Internal error status (e.g. Error active, Error passive, Bus Off)";
CM_ SG_ 1505 MDB1_OD_CAN2_DiscardedTxMessages "Number of discarded TX messages on CAN2 because all messageboxes were full";
CM_ SG_ 1505 MDB1_OD_CAN2_Status "Status of CAN2.";
CM_ SG_ 1505 MDB1_OD_CAN2_Baudrate "Baudrate of CAN.";
CM_ SG_ 1505 MDB1_OD_CAN2_autoErrorReset "Automatic reset of errors.";
CM_ SG_ 1505 MDB1_OD_CAN2_lastErrorCode "Last error code.";
CM_ SG_ 1505 MDB1_OD_CAN2_RxErrCnt "Receive error count of CAN1.";
CM_ SG_ 1505 MDB1_OD_CAN2_TxErrCnt "Transmit error count of CAN1.";
CM_ SG_ 1505 MDB1_OD_CAN1_DelayedTxMessages "Number of delayed TX messages on CAN1 because no messagebox was free.";
CM_ SG_ 1505 MDB1_OD_CAN1_ErrorStatus "Internal error status (e.g. Error active, Error passive, Bus Off)";
CM_ SG_ 1505 MDB1_OD_CAN1_DiscardedTxMessages "Number of discarded TX messages on CAN1 because all messageboxes were full";
CM_ SG_ 1505 MDB1_OD_CAN1_Status "Status of CAN1.";
CM_ SG_ 1505 MDB1_OD_CAN1_Baudrate "Baudrate of CAN.";
CM_ SG_ 1505 MDB1_OD_CAN1_autoErrorReset "Automatic reset of errors.";
CM_ SG_ 1505 MDB1_OD_CAN1_lastErrorCode "Last error code.";
CM_ SG_ 1505 MDB1_OD_CAN1_RxErrCnt "Receive error count of CAN1.";
CM_ SG_ 1505 MDB1_OD_CAN1_TxErrCnt "Transmit error count of CAN1.";
CM_ SG_ 1505 MDB1_OD_BuildTime "Software build time in the format HHMMSS.";
CM_ SG_ 1505 MDB1_OD_BuildDate "Software build date in the format YYYYMMDD.";
CM_ SG_ 1505 MDB1_OD_ChipUID2 "Seccond part of unique ID of microcontroller.";
CM_ SG_ 1505 MDB1_OD_ChipUID1 "First part of unique ID of microcontroller.";
CM_ SG_ 1505 MDB1_OD_SdcOut "Measurement of Shutdown Circuit Output";
CM_ SG_ 1505 MDB1_OD_SdcIn "Measurement of Shutdown Circuit Input";
CM_ SG_ 1505 MDB1_OD_runtime "Runtime of chip in milliseconds.";
CM_ SG_ 1505 MDB1_OD_InputVoltage "Board supply voltage.";
CM_ SG_ 1505 MDB1_OD_BoardTemp "Temperature of board";
CM_ SG_ 1505 MDB1_OD_MemFree "Free memory in bytes.";
CM_ SG_ 1505 MDB1_OD_CpuUsage "Current CPU usage in %.";
CM_ SG_ 1505 MDB1_OD_OdEntrySendInterval "Interval for sending all readable OD entries. Sending is disabled if less than 5 ms.";
CM_ SG_ 1505 MDB1_OD_SendOdOnBootup "Whether to send all OD entries on bootup.";
CM_ SG_ 1505 MDB1_OD_HeartbeatInterval "Heartbeat Interval in milliseconds.";
CM_ SG_ 1505 MDB1_OD_DbcVersion "CANzero DBC version.";
CM_ SG_ 1505 MDB1_OD_StackVersion "CANzero stack version.";
CM_ SG_ 1505 MDB1_OD_ProtocolVersion "CANzero Protocol Version.";
CM_ SG_ 1505 MDB1_OD_NodeStatus "State of the node.";
CM_ SG_ 1505 MDB1_OD_NodeID "CANzero Node-ID.";
CM_ SG_ 1505 MDB1_SDO_ID "Specifies SDO-ID of MDB1";
CM_ BO_ 1569 "DO NOT CHANGE ANYTHING HERE!
SDO Request Download from node MDB1 with Node-ID 0x21";
CM_ SG_ 1569 MDB1_SDO_ID "Specifies SDO-ID of MDB1";
CM_ BO_ 1825 "Heartbeat of node MDB1 with Node-ID 0x21";
CM_ SG_ 1825 MDB1_NodeState "Heartbeat status of node MDB1";
CM_ BO_ 1889 "Bootloader transmit from node MDB1 with Node-ID 0x21";
CM_ BO_ 1953 "Bootloader receive by node MDB1 with Node-ID 0x21";
CM_ BO_ 163 "Emergency message of node MDB2 with Node-ID 0x23";
CM_ SG_ 163 MDB2_E0_OtherError "Other error.";
CM_ SG_ 163 MDB2_W0_OtherWarning "Other warning.";
CM_ BO_ 419 "Transmit PDO 1 of node MDB2 with Node-ID 0x23";
CM_ BO_ 483 "Receive PDO 1 of node MDB2 with Node-ID 0x23";
CM_ BO_ 547 "Transmit PDO 2 of node MDB2 with Node-ID 0x23";
CM_ BO_ 611 "Receive PDO 2 of node MDB2 with Node-ID 0x23";
CM_ BO_ 675 "Transmit PDO 3 of node MDB2 with Node-ID 0x23";
CM_ BO_ 739 "Receive PDO 3 of node MDB2 with Node-ID 0x23";
CM_ BO_ 803 "Transmit PDO 4 of node MDB2 with Node-ID 0x23";
CM_ BO_ 867 "Receive PDO 4 of node MDB2 with Node-ID 0x23";
CM_ BO_ 931 "Transmit PDO 5 of node MDB2 with Node-ID 0x23";
CM_ BO_ 995 "Transmit PDO 6 of node MDB2 with Node-ID 0x23";
CM_ BO_ 1059 "Transmit PDO 7 of node MDB2 with Node-ID 0x23";
CM_ BO_ 1123 "Transmit PDO 8 of node MDB2 with Node-ID 0x23";
CM_ BO_ 1187 "Transmit PDO 9 of node MDB2 with Node-ID 0x23";
CM_ BO_ 1251 "Transmit PDO 10 of node MDB2 with Node-ID 0x23";
CM_ BO_ 1315 "Transmit PDO 11 of node MDB2 with Node-ID 0x23";
CM_ BO_ 1379 "Transmit PDO 12 of node MDB2 with Node-ID 0x23";
CM_ BO_ 1443 "DO NOT CHANGE ANYTHING HERE!
SDO Response of node MDB2 with Node-ID 0x23";
CM_ SG_ 1443 MDB2_OD_CAN2_DelayedTxMessages "Number of delayed TX messages on CAN2 because no messagebox was free.";
CM_ SG_ 1443 MDB2_OD_CAN2_ErrorStatus "Internal error status (e.g. Error active, Error passive, Bus Off)";
CM_ SG_ 1443 MDB2_OD_CAN2_DiscardedTxMessages "Number of discarded TX messages on CAN2 because all messageboxes were full";
CM_ SG_ 1443 MDB2_OD_CAN2_Status "Status of CAN2.";
CM_ SG_ 1443 MDB2_OD_CAN2_Baudrate "Baudrate of CAN.";
CM_ SG_ 1443 MDB2_OD_CAN2_autoErrorReset "Automatic reset of errors.";
CM_ SG_ 1443 MDB2_OD_CAN2_lastErrorCode "Last error code.";
CM_ SG_ 1443 MDB2_OD_CAN2_RxErrCnt "Receive error count of CAN1.";
CM_ SG_ 1443 MDB2_OD_CAN2_TxErrCnt "Transmit error count of CAN1.";
CM_ SG_ 1443 MDB2_OD_CAN1_DelayedTxMessages "Number of delayed TX messages on CAN1 because no messagebox was free.";
CM_ SG_ 1443 MDB2_OD_CAN1_ErrorStatus "Internal error status (e.g. Error active, Error passive, Bus Off)";
CM_ SG_ 1443 MDB2_OD_CAN1_DiscardedTxMessages "Number of discarded TX messages on CAN1 because all messageboxes were full";
CM_ SG_ 1443 MDB2_OD_CAN1_Status "Status of CAN1.";
CM_ SG_ 1443 MDB2_OD_CAN1_Baudrate "Baudrate of CAN.";
CM_ SG_ 1443 MDB2_OD_CAN1_autoErrorReset "Automatic reset of errors.";
CM_ SG_ 1443 MDB2_OD_CAN1_lastErrorCode "Last error code.";
CM_ SG_ 1443 MDB2_OD_CAN1_RxErrCnt "Receive error count of CAN1.";
CM_ SG_ 1443 MDB2_OD_CAN1_TxErrCnt "Transmit error count of CAN1.";
CM_ SG_ 1443 MDB2_OD_BuildTime "Software build time in the format HHMMSS.";
CM_ SG_ 1443 MDB2_OD_BuildDate "Software build date in the format YYYYMMDD.";
CM_ SG_ 1443 MDB2_OD_ChipUID2 "Seccond part of unique ID of microcontroller.";
CM_ SG_ 1443 MDB2_OD_ChipUID1 "First part of unique ID of microcontroller.";
CM_ SG_ 1443 MDB2_OD_SdcOut "Measurement of Shutdown Circuit Output";
CM_ SG_ 1443 MDB2_OD_SdcIn "Measurement of Shutdown Circuit Input";
CM_ SG_ 1443 MDB2_OD_runtime "Runtime of chip in milliseconds.";
CM_ SG_ 1443 MDB2_OD_InputVoltage "Board supply voltage.";
CM_ SG_ 1443 MDB2_OD_BoardTemp "Temperature of board";
CM_ SG_ 1443 MDB2_OD_MemFree "Free memory in bytes.";
CM_ SG_ 1443 MDB2_OD_CpuUsage "Current CPU usage in %.";
CM_ SG_ 1443 MDB2_OD_OdEntrySendInterval "Interval for sending all readable OD entries. Sending is disabled if less than 5 ms.";
CM_ SG_ 1443 MDB2_OD_SendOdOnBootup "Whether to send all OD entries on bootup.";
CM_ SG_ 1443 MDB2_OD_HeartbeatInterval "Heartbeat Interval in milliseconds.";
CM_ SG_ 1443 MDB2_OD_DbcVersion "CANzero DBC version.";
CM_ SG_ 1443 MDB2_OD_StackVersion "CANzero stack version.";
CM_ SG_ 1443 MDB2_OD_ProtocolVersion "CANzero Protocol Version.";
CM_ SG_ 1443 MDB2_OD_NodeStatus "State of the node.";
CM_ SG_ 1443 MDB2_OD_NodeID "CANzero Node-ID.";
CM_ SG_ 1443 MDB2_SDO_RespCode "Response code of SDO access.";
CM_ SG_ 1443 MDB2_SDO_ID "Specifies SDO-ID of MDB2";
CM_ BO_ 1507 "DO NOT CHANGE ANYTHING HERE!
SDO Request Upload to node MDB2 with Node-ID 0x23";
CM_ SG_ 1507 MDB2_OD_CAN2_DelayedTxMessages "Number of delayed TX messages on CAN2 because no messagebox was free.";
CM_ SG_ 1507 MDB2_OD_CAN2_ErrorStatus "Internal error status (e.g. Error active, Error passive, Bus Off)";
CM_ SG_ 1507 MDB2_OD_CAN2_DiscardedTxMessages "Number of discarded TX messages on CAN2 because all messageboxes were full";
CM_ SG_ 1507 MDB2_OD_CAN2_Status "Status of CAN2.";
CM_ SG_ 1507 MDB2_OD_CAN2_Baudrate "Baudrate of CAN.";
CM_ SG_ 1507 MDB2_OD_CAN2_autoErrorReset "Automatic reset of errors.";
CM_ SG_ 1507 MDB2_OD_CAN2_lastErrorCode "Last error code.";
CM_ SG_ 1507 MDB2_OD_CAN2_RxErrCnt "Receive error count of CAN1.";
CM_ SG_ 1507 MDB2_OD_CAN2_TxErrCnt "Transmit error count of CAN1.";
CM_ SG_ 1507 MDB2_OD_CAN1_DelayedTxMessages "Number of delayed TX messages on CAN1 because no messagebox was free.";
CM_ SG_ 1507 MDB2_OD_CAN1_ErrorStatus "Internal error status (e.g. Error active, Error passive, Bus Off)";
CM_ SG_ 1507 MDB2_OD_CAN1_DiscardedTxMessages "Number of discarded TX messages on CAN1 because all messageboxes were full";
CM_ SG_ 1507 MDB2_OD_CAN1_Status "Status of CAN1.";
CM_ SG_ 1507 MDB2_OD_CAN1_Baudrate "Baudrate of CAN.";
CM_ SG_ 1507 MDB2_OD_CAN1_autoErrorReset "Automatic reset of errors.";
CM_ SG_ 1507 MDB2_OD_CAN1_lastErrorCode "Last error code.";
CM_ SG_ 1507 MDB2_OD_CAN1_RxErrCnt "Receive error count of CAN1.";
CM_ SG_ 1507 MDB2_OD_CAN1_TxErrCnt "Transmit error count of CAN1.";
CM_ SG_ 1507 MDB2_OD_BuildTime "Software build time in the format HHMMSS.";
CM_ SG_ 1507 MDB2_OD_BuildDate "Software build date in the format YYYYMMDD.";
CM_ SG_ 1507 MDB2_OD_ChipUID2 "Seccond part of unique ID of microcontroller.";
CM_ SG_ 1507 MDB2_OD_ChipUID1 "First part of unique ID of microcontroller.";
CM_ SG_ 1507 MDB2_OD_SdcOut "Measurement of Shutdown Circuit Output";
CM_ SG_ 1507 MDB2_OD_SdcIn "Measurement of Shutdown Circuit Input";
CM_ SG_ 1507 MDB2_OD_runtime "Runtime of chip in milliseconds.";
CM_ SG_ 1507 MDB2_OD_InputVoltage "Board supply voltage.";
CM_ SG_ 1507 MDB2_OD_BoardTemp "Temperature of board";
CM_ SG_ 1507 MDB2_OD_MemFree "Free memory in bytes.";
CM_ SG_ 1507 MDB2_OD_CpuUsage "Current CPU usage in %.";
CM_ SG_ 1507 MDB2_OD_OdEntrySendInterval "Interval for sending all readable OD entries. Sending is disabled if less than 5 ms.";
CM_ SG_ 1507 MDB2_OD_SendOdOnBootup "Whether to send all OD entries on bootup.";
CM_ SG_ 1507 MDB2_OD_HeartbeatInterval "Heartbeat Interval in milliseconds.";
CM_ SG_ 1507 MDB2_OD_DbcVersion "CANzero DBC version.";
CM_ SG_ 1507 MDB2_OD_StackVersion "CANzero stack version.";
CM_ SG_ 1507 MDB2_OD_ProtocolVersion "CANzero Protocol Version.";
CM_ SG_ 1507 MDB2_OD_NodeStatus "State of the node.";
CM_ SG_ 1507 MDB2_OD_NodeID "CANzero Node-ID.";
CM_ SG_ 1507 MDB2_SDO_ID "Specifies SDO-ID of MDB2";
CM_ BO_ 1571 "DO NOT CHANGE ANYTHING HERE!
SDO Request Download from node MDB2 with Node-ID 0x23";
CM_ SG_ 1571 MDB2_SDO_ID "Specifies SDO-ID of MDB2";
CM_ BO_ 1827 "Heartbeat of node MDB2 with Node-ID 0x23";
CM_ SG_ 1827 MDB2_NodeState "Heartbeat status of node MDB2";
CM_ BO_ 1891 "Bootloader transmit from node MDB2 with Node-ID 0x23";
CM_ BO_ 1955 "Bootloader receive by node MDB2 with Node-ID 0x23";
CM_ BO_ 167 "Emergency message of node MDB3 with Node-ID 0x27";
CM_ SG_ 167 MDB3_E0_OtherError "Other error.";
CM_ SG_ 167 MDB3_W0_OtherWarning "Other warning.";
CM_ BO_ 423 "Transmit PDO 1 of node MDB3 with Node-ID 0x27";
CM_ BO_ 487 "Receive PDO 1 of node MDB3 with Node-ID 0x27";
CM_ BO_ 551 "Transmit PDO 2 of node MDB3 with Node-ID 0x27";
CM_ BO_ 615 "Receive PDO 2 of node MDB3 with Node-ID 0x27";
CM_ BO_ 679 "Transmit PDO 3 of node MDB3 with Node-ID 0x27";
CM_ BO_ 743 "Receive PDO 3 of node MDB3 with Node-ID 0x27";
CM_ BO_ 807 "Transmit PDO 4 of node MDB3 with Node-ID 0x27";
CM_ BO_ 871 "Receive PDO 4 of node MDB3 with Node-ID 0x27";
CM_ BO_ 935 "Transmit PDO 5 of node MDB3 with Node-ID 0x27";
CM_ BO_ 999 "Transmit PDO 6 of node MDB3 with Node-ID 0x27";
CM_ BO_ 1063 "Transmit PDO 7 of node MDB3 with Node-ID 0x27";
CM_ BO_ 1127 "Transmit PDO 8 of node MDB3 with Node-ID 0x27";
CM_ BO_ 1191 "Transmit PDO 9 of node MDB3 with Node-ID 0x27";
CM_ BO_ 1255 "Transmit PDO 10 of node MDB3 with Node-ID 0x27";
CM_ BO_ 1319 "Transmit PDO 11 of node MDB3 with Node-ID 0x27";
CM_ BO_ 1383 "Transmit PDO 12 of node MDB3 with Node-ID 0x27";
BA_DEF_ SG_  "GenSigSendType" ENUM  "Cyclic","OnWrite","OnWriteWithRepetition","OnChange","OnChangeWithRepetition","IfActive","IfActiveWithRepetition","NoSigSendType";
BA_DEF_ BO_  "GenMsgSendType" ENUM  "Cyclic","not_used","not_used","not_used","not_used","Cyclic","not_used","IfActive","NoMsgSendType";
BA_DEF_ BO_  "GenMsgCycleTime" INT 2 50000;
BA_DEF_ BO_  "GenMsgDelayTime" INT 1 1000;
BA_DEF_ BO_  "GenMsgNrOfRepetitions" INT 1 999999;
BA_DEF_ SG_  "GenSigStartValue" FLOAT 0 100000000000;
BA_DEF_ SG_  "CANzero_SDO_Group" STRING ;
BA_DEF_ SG_  "CANzero_SDO_AccessIfOperational" ENUM  "No","Yes";
BA_DEF_ SG_  "CANzero_SDO_AccessType" ENUM  "Read Write","Read Only","Write Only";
BA_DEF_ SG_  "CANzero_SDO_Default" FLOAT 0 0;
BA_DEF_ SG_  "SystemSignalLongSymbol" STRING ;
BA_DEF_DEF_  "GenSigSendType" "Cyclic";
BA_DEF_DEF_  "GenMsgSendType" "NoMsgSendType";
BA_DEF_DEF_  "GenMsgCycleTime" 100;
BA_DEF_DEF_  "GenMsgDelayTime" 1;
BA_DEF_DEF_  "GenMsgNrOfRepetitions" 1;
BA_DEF_DEF_  "GenSigStartValue" 0;
BA_DEF_DEF_  "CANzero_SDO_Group" "";
BA_DEF_DEF_  "CANzero_SDO_AccessIfOperational" "No";
BA_DEF_DEF_  "CANzero_SDO_AccessType" "Read Write";
BA_DEF_DEF_  "CANzero_SDO_Default" 0;
BA_DEF_DEF_  "SystemSignalLongSymbol" "";
BA_ "CANzero_SDO_Group" SG_ 1433 HVTU_OD_CAN2_DelayedTxMessages "CAN";
BA_ "CANzero_SDO_AccessType" SG_ 1433 HVTU_OD_CAN2_DelayedTxMessages 1;
BA_ "CANzero_SDO_AccessIfOperational" SG_ 1433 HVTU_OD_CAN2_DelayedTxMessages 1;
BA_ "CANzero_SDO_Group" SG_ 1433 HVTU_OD_CAN2_ErrorStatus "CAN";
BA_ "CANzero_SDO_AccessType" SG_ 1433 HVTU_OD_CAN2_ErrorStatus 1;
BA_ "CANzero_SDO_AccessIfOperational" SG_ 1433 HVTU_OD_CAN2_ErrorStatus 1;
BA_ "CANzero_SDO_Group" SG_ 1433 HVTU_OD_CAN2_DiscardedTxMessages "CAN";
BA_ "CANzero_SDO_AccessType" SG_ 1433 HVTU_OD_CAN2_DiscardedTxMessages 1;
BA_ "CANzero_SDO_AccessIfOperational" SG_ 1433 HVTU_OD_CAN2_DiscardedTxMessages 1;
BA_ "CANzero_SDO_Group" SG_ 1433 HVTU_OD_CAN2_Status "CAN";
BA_ "CANzero_SDO_AccessType" SG_ 1433 HVTU_OD_CAN2_Status 1;
BA_ "CANzero_SDO_AccessIfOperational" SG_ 1433 HVTU_OD_CAN2_Status 1;
BA_ "CANzero_SDO_Group" SG_ 1433 HVTU_OD_CAN2_Baudrate "CAN";
BA_ "CANzero_SDO_AccessIfOperational" SG_ 1433 HVTU_OD_CAN2_Baudrate 1;
BA_ "GenSigStartValue" SG_ 1433 HVTU_OD_CAN2_Baudrate 1000.0;
BA_ "CANzero_SDO_Default" SG_ 1433 HVTU_OD_CAN2_Baudrate 1000;
BA_ "CANzero_SDO_Group" SG_ 1433 HVTU_OD_CAN2_autoErrorReset "CAN";
BA_ "CANzero_SDO_AccessIfOperational" SG_ 1433 HVTU_OD_CAN2_autoErrorReset 1;
BA_ "GenSigStartValue" SG_ 1433 HVTU_OD_CAN2_autoErrorReset 1.0;
BA_ "CANzero_SDO_Default" SG_ 1433 HVTU_OD_CAN2_autoErrorReset 1;
BA_ "CANzero_SDO_Group" SG_ 1433 HVTU_OD_CAN2_lastErrorCode "CAN";
BA_ "CANzero_SDO_AccessType" SG_ 1433 HVTU_OD_CAN2_lastErrorCode 1;
BA_ "CANzero_SDO_AccessIfOperational" SG_ 1433 HVTU_OD_CAN2_lastErrorCode 1;
BA_ "CANzero_SDO_Group" SG_ 1433 HVTU_OD_CAN2_RxErrCnt "CAN";
BA_ "CANzero_SDO_AccessType" SG_ 1433 HVTU_OD_CAN2_RxErrCnt 1;
BA_ "CANzero_SDO_AccessIfOperational" SG_ 1433 HVTU_OD_CAN2_RxErrCnt 1;
BA_ "CANzero_SDO_Group" SG_ 1433 HVTU_OD_CAN2_TxErrCnt "CAN";
BA_ "CANzero_SDO_AccessType" SG_ 1433 HVTU_OD_CAN2_TxErrCnt 1;
BA_ "CANzero_SDO_AccessIfOperational" SG_ 1433 HVTU_OD_CAN2_TxErrCnt 1;
BA_ "CANzero_SDO_Group" SG_ 1433 HVTU_OD_CAN1_DelayedTxMessages "CAN";
BA_ "CANzero_SDO_AccessType" SG_ 1433 HVTU_OD_CAN1_DelayedTxMessages 1;
BA_ "CANzero_SDO_AccessIfOperational" SG_ 1433 HVTU_OD_CAN1_DelayedTxMessages 1;
BA_ "CANzero_SDO_Group" SG_ 1433 HVTU_OD_CAN1_ErrorStatus "CAN";
BA_ "CANzero_SDO_AccessType" SG_ 1433 HVTU_OD_CAN1_ErrorStatus 1;
BA_ "CANzero_SDO_AccessIfOperational" SG_ 1433 HVTU_OD_CAN1_ErrorStatus 1;
BA_ "CANzero_SDO_Group" SG_ 1433 HVTU_OD_CAN1_DiscardedTxMessages "CAN";
BA_ "CANzero_SDO_AccessType" SG_ 1433 HVTU_OD_CAN1_DiscardedTxMessages 1;
BA_ "CANzero_SDO_AccessIfOperational" SG_ 1433 HVTU_OD_CAN1_DiscardedTxMessages 1;
BA_ "CANzero_SDO_Group" SG_ 1433 HVTU_OD_CAN1_Status "CAN";
BA_ "CANzero_SDO_AccessType" SG_ 1433 HVTU_OD_CAN1_Status 1;
BA_ "CANzero_SDO_AccessIfOperational" SG_ 1433 HVTU_OD_CAN1_Status 1;
BA_ "CANzero_SDO_Group" SG_ 1433 HVTU_OD_CAN1_Baudrate "CAN";
BA_ "CANzero_SDO_AccessIfOperational" SG_ 1433 HVTU_OD_CAN1_Baudrate 1;
BA_ "GenSigStartValue" SG_ 1433 HVTU_OD_CAN1_Baudrate 1000.0;
BA_ "CANzero_SDO_Default" SG_ 1433 HVTU_OD_CAN1_Baudrate 1000;
BA_ "CANzero_SDO_Group" SG_ 1433 HVTU_OD_CAN1_autoErrorReset "CAN";
BA_ "CANzero_SDO_AccessIfOperational" SG_ 1433 HVTU_OD_CAN1_autoErrorReset 1;
BA_ "GenSigStartValue" SG_ 1433 HVTU_OD_CAN1_autoErrorReset 1.0;
BA_ "CANzero_SDO_Default" SG_ 1433 HVTU_OD_CAN1_autoErrorReset 1;
BA_ "CANzero_SDO_Group" SG_ 1433 HVTU_OD_CAN1_lastErrorCode "CAN";
BA_ "CANzero_SDO_AccessType" SG_ 1433 HVTU_OD_CAN1_lastErrorCode 1;
BA_ "CANzero_SDO_AccessIfOperational" SG_ 1433 HVTU_OD_CAN1_lastErrorCode 1;
BA_ "CANzero_SDO_Group" SG_ 1433 HVTU_OD_CAN1_RxErrCnt "CAN";
BA_ "CANzero_SDO_AccessType" SG_ 1433 HVTU_OD_CAN1_RxErrCnt 1;
BA_ "CANzero_SDO_AccessIfOperational" SG_ 1433 HVTU_OD_CAN1_RxErrCnt 1;
BA_ "CANzero_SDO_Group" SG_ 1433 HVTU_OD_CAN1_TxErrCnt "CAN";
BA_ "CANzero_SDO_AccessType" SG_ 1433 HVTU_OD_CAN1_TxErrCnt 1;
BA_ "CANzero_SDO_AccessIfOperational" SG_ 1433 HVTU_OD_CAN1_TxErrCnt 1;
BA_ "CANzero_SDO_AccessType" SG_ 1433 HVTU_OD_BuildTime 1;
BA_ "CANzero_SDO_AccessIfOperational" SG_ 1433 HVTU_OD_BuildTime 1;
BA_ "CANzero_SDO_AccessType" SG_ 1433 HVTU_OD_BuildDate 1;
BA_ "CANzero_SDO_AccessIfOperational" SG_ 1433 HVTU_OD_BuildDate 1;
BA_ "CANzero_SDO_AccessType" SG_ 1433 HVTU_OD_ChipUID2 1;
BA_ "CANzero_SDO_AccessIfOperational" SG_ 1433 HVTU_OD_ChipUID2 1;
BA_ "CANzero_SDO_AccessType" SG_ 1433 HVTU_OD_ChipUID1 1;
BA_ "CANzero_SDO_AccessIfOperational" SG_ 1433 HVTU_OD_ChipUID1 1;
BA_ "CANzero_SDO_AccessType" SG_ 1433 HVTU_OD_SdcOut 1;
BA_ "CANzero_SDO_AccessIfOperational" SG_ 1433 HVTU_OD_SdcOut 1;
BA_ "CANzero_SDO_AccessType" SG_ 1433 HVTU_OD_SdcIn 1;
BA_ "CANzero_SDO_AccessIfOperational" SG_ 1433 HVTU_OD_SdcIn 1;
BA_ "CANzero_SDO_AccessType" SG_ 1433 HVTU_OD_runtime 1;
BA_ "CANzero_SDO_AccessIfOperational" SG_ 1433 HVTU_OD_runtime 1;
BA_ "CANzero_SDO_AccessType" SG_ 1433 HVTU_OD_InputVoltage 1;
BA_ "CANzero_SDO_AccessIfOperational" SG_ 1433 HVTU_OD_InputVoltage 1;
BA_ "CANzero_SDO_AccessType" SG_ 1433 HVTU_OD_BoardTemp 1;
BA_ "CANzero_SDO_AccessIfOperational" SG_ 1433 HVTU_OD_BoardTemp 1;
BA_ "GenSigStartValue" SG_ 1433 HVTU_OD_BoardTemp 3000.0;
BA_ "CANzero_SDO_AccessType" SG_ 1433 HVTU_OD_MemFree 1;
BA_ "CANzero_SDO_AccessIfOperational" SG_ 1433 HVTU_OD_MemFree 1;
BA_ "CANzero_SDO_AccessType" SG_ 1433 HVTU_OD_CpuUsage 1;
BA_ "CANzero_SDO_AccessIfOperational" SG_ 1433 HVTU_OD_CpuUsage 1;
BA_ "CANzero_SDO_AccessIfOperational" SG_ 1433 HVTU_OD_OdEntrySendInterval 1;
BA_ "GenSigStartValue" SG_ 1433 HVTU_OD_OdEntrySendInterval 50.0;
BA_ "CANzero_SDO_Default" SG_ 1433 HVTU_OD_OdEntrySendInterval 50;
BA_ "CANzero_SDO_AccessIfOperational" SG_ 1433 HVTU_OD_SendOdOnBootup 1;
BA_ "CANzero_SDO_AccessIfOperational" SG_ 1433 HVTU_OD_HeartbeatInterval 1;
BA_ "GenSigStartValue" SG_ 1433 HVTU_OD_HeartbeatInterval 250.0;
BA_ "CANzero_SDO_Default" SG_ 1433 HVTU_OD_HeartbeatInterval 250;
BA_ "CANzero_SDO_AccessType" SG_ 1433 HVTU_OD_DbcVersion 1;
BA_ "CANzero_SDO_AccessIfOperational" SG_ 1433 HVTU_OD_DbcVersion 1;
BA_ "CANzero_SDO_AccessType" SG_ 1433 HVTU_OD_StackVersion 1;
BA_ "CANzero_SDO_AccessIfOperational" SG_ 1433 HVTU_OD_StackVersion 1;
BA_ "CANzero_SDO_AccessType" SG_ 1433 HVTU_OD_ProtocolVersion 1;
BA_ "CANzero_SDO_AccessIfOperational" SG_ 1433 HVTU_OD_ProtocolVersion 1;
BA_ "GenSigStartValue" SG_ 1433 HVTU_OD_ProtocolVersion 1.0;
BA_ "CANzero_SDO_Default" SG_ 1433 HVTU_OD_ProtocolVersion 1;
BA_ "CANzero_SDO_AccessType" SG_ 1433 HVTU_OD_NodeStatus 1;
BA_ "CANzero_SDO_AccessIfOperational" SG_ 1433 HVTU_OD_NodeStatus 1;
BA_ "CANzero_SDO_AccessType" SG_ 1433 HVTU_OD_NodeID 1;
BA_ "CANzero_SDO_AccessIfOperational" SG_ 1433 HVTU_OD_NodeID 1;
BA_ "CANzero_SDO_Group" SG_ 1497 HVTU_OD_CAN2_DelayedTxMessages "CAN";
BA_ "CANzero_SDO_AccessType" SG_ 1497 HVTU_OD_CAN2_DelayedTxMessages 1;
BA_ "CANzero_SDO_AccessIfOperational" SG_ 1497 HVTU_OD_CAN2_DelayedTxMessages 1;
BA_ "CANzero_SDO_Group" SG_ 1497 HVTU_OD_CAN2_ErrorStatus "CAN";
BA_ "CANzero_SDO_AccessType" SG_ 1497 HVTU_OD_CAN2_ErrorStatus 1;
BA_ "CANzero_SDO_AccessIfOperational" SG_ 1497 HVTU_OD_CAN2_ErrorStatus 1;
BA_ "CANzero_SDO_Group" SG_ 1497 HVTU_OD_CAN2_DiscardedTxMessages "CAN";
BA_ "CANzero_SDO_AccessType" SG_ 1497 HVTU_OD_CAN2_DiscardedTxMessages 1;
BA_ "CANzero_SDO_AccessIfOperational" SG_ 1497 HVTU_OD_CAN2_DiscardedTxMessages 1;
BA_ "CANzero_SDO_Group" SG_ 1497 HVTU_OD_CAN2_Status "CAN";
BA_ "CANzero_SDO_AccessType" SG_ 1497 HVTU_OD_CAN2_Status 1;
BA_ "CANzero_SDO_AccessIfOperational" SG_ 1497 HVTU_OD_CAN2_Status 1;
BA_ "CANzero_SDO_Group" SG_ 1497 HVTU_OD_CAN2_Baudrate "CAN";
BA_ "CANzero_SDO_AccessIfOperational" SG_ 1497 HVTU_OD_CAN2_Baudrate 1;
BA_ "GenSigStartValue" SG_ 1497 HVTU_OD_CAN2_Baudrate 1000.0;
BA_ "CANzero_SDO_Default" SG_ 1497 HVTU_OD_CAN2_Baudrate 1000;
BA_ "CANzero_SDO_Group" SG_ 1497 HVTU_OD_CAN2_autoErrorReset "CAN";
BA_ "CANzero_SDO_AccessIfOperational" SG_ 1497 HVTU_OD_CAN2_autoErrorReset 1;
BA_ "GenSigStartValue" SG_ 1497 HVTU_OD_CAN2_autoErrorReset 1.0;
BA_ "CANzero_SDO_Default" SG_ 1497 HVTU_OD_CAN2_autoErrorReset 1;
BA_ "CANzero_SDO_Group" SG_ 1497 HVTU_OD_CAN2_lastErrorCode "CAN";
BA_ "CANzero_SDO_AccessType" SG_ 1497 HVTU_OD_CAN2_lastErrorCode 1;
BA_ "CANzero_SDO_AccessIfOperational" SG_ 1497 HVTU_OD_CAN2_lastErrorCode 1;
BA_ "CANzero_SDO_Group" SG_ 1497 HVTU_OD_CAN2_RxErrCnt "CAN";
BA_ "CANzero_SDO_AccessType" SG_ 1497 HVTU_OD_CAN2_RxErrCnt 1;
BA_ "CANzero_SDO_AccessIfOperational" SG_ 1497 HVTU_OD_CAN2_RxErrCnt 1;
BA_ "CANzero_SDO_Group" SG_ 1497 HVTU_OD_CAN2_TxErrCnt "CAN";
BA_ "CANzero_SDO_AccessType" SG_ 1497 HVTU_OD_CAN2_TxErrCnt 1;
BA_ "CANzero_SDO_AccessIfOperational" SG_ 1497 HVTU_OD_CAN2_TxErrCnt 1;
BA_ "CANzero_SDO_Group" SG_ 1497 HVTU_OD_CAN1_DelayedTxMessages "CAN";
BA_ "CANzero_SDO_AccessType" SG_ 1497 HVTU_OD_CAN1_DelayedTxMessages 1;
BA_ "CANzero_SDO_AccessIfOperational" SG_ 1497 HVTU_OD_CAN1_DelayedTxMessages 1;
BA_ "CANzero_SDO_Group" SG_ 1497 HVTU_OD_CAN1_ErrorStatus "CAN";
BA_ "CANzero_SDO_AccessType" SG_ 1497 HVTU_OD_CAN1_ErrorStatus 1;
BA_ "CANzero_SDO_AccessIfOperational" SG_ 1497 HVTU_OD_CAN1_ErrorStatus 1;
BA_ "CANzero_SDO_Group" SG_ 1497 HVTU_OD_CAN1_DiscardedTxMessages "CAN";
BA_ "CANzero_SDO_AccessType" SG_ 1497 HVTU_OD_CAN1_DiscardedTxMessages 1;
BA_ "CANzero_SDO_AccessIfOperational" SG_ 1497 HVTU_OD_CAN1_DiscardedTxMessages 1;
BA_ "CANzero_SDO_Group" SG_ 1497 HVTU_OD_CAN1_Status "CAN";
BA_ "CANzero_SDO_AccessType" SG_ 1497 HVTU_OD_CAN1_Status 1;
BA_ "CANzero_SDO_AccessIfOperational" SG_ 1497 HVTU_OD_CAN1_Status 1;
BA_ "CANzero_SDO_Group" SG_ 1497 HVTU_OD_CAN1_Baudrate "CAN";
BA_ "CANzero_SDO_AccessIfOperational" SG_ 1497 HVTU_OD_CAN1_Baudrate 1;
BA_ "GenSigStartValue" SG_ 1497 HVTU_OD_CAN1_Baudrate 1000.0;
BA_ "CANzero_SDO_Default" SG_ 1497 HVTU_OD_CAN1_Baudrate 1000;
BA_ "CANzero_SDO_Group" SG_ 1497 HVTU_OD_CAN1_autoErrorReset "CAN";
BA_ "CANzero_SDO_AccessIfOperational" SG_ 1497 HVTU_OD_CAN1_autoErrorReset 1;
BA_ "GenSigStartValue" SG_ 1497 HVTU_OD_CAN1_autoErrorReset 1.0;
BA_ "CANzero_SDO_Default" SG_ 1497 HVTU_OD_CAN1_autoErrorReset 1;
BA_ "CANzero_SDO_Group" SG_ 1497 HVTU_OD_CAN1_lastErrorCode "CAN";
BA_ "CANzero_SDO_AccessType" SG_ 1497 HVTU_OD_CAN1_lastErrorCode 1;
BA_ "CANzero_SDO_AccessIfOperational" SG_ 1497 HVTU_OD_CAN1_lastErrorCode 1;
BA_ "CANzero_SDO_Group" SG_ 1497 HVTU_OD_CAN1_RxErrCnt "CAN";
BA_ "CANzero_SDO_AccessType" SG_ 1497 HVTU_OD_CAN1_RxErrCnt 1;
BA_ "CANzero_SDO_AccessIfOperational" SG_ 1497 HVTU_OD_CAN1_RxErrCnt 1;
BA_ "CANzero_SDO_Group" SG_ 1497 HVTU_OD_CAN1_TxErrCnt "CAN";
BA_ "CANzero_SDO_AccessType" SG_ 1497 HVTU_OD_CAN1_TxErrCnt 1;
BA_ "CANzero_SDO_AccessIfOperational" SG_ 1497 HVTU_OD_CAN1_TxErrCnt 1;
BA_ "CANzero_SDO_AccessType" SG_ 1497 HVTU_OD_BuildTime 1;
BA_ "CANzero_SDO_AccessIfOperational" SG_ 1497 HVTU_OD_BuildTime 1;
BA_ "CANzero_SDO_AccessType" SG_ 1497 HVTU_OD_BuildDate 1;
BA_ "CANzero_SDO_AccessIfOperational" SG_ 1497 HVTU_OD_BuildDate 1;
BA_ "CANzero_SDO_AccessType" SG_ 1497 HVTU_OD_ChipUID2 1;
BA_ "CANzero_SDO_AccessIfOperational" SG_ 1497 HVTU_OD_ChipUID2 1;
BA_ "CANzero_SDO_AccessType" SG_ 1497 HVTU_OD_ChipUID1 1;
BA_ "CANzero_SDO_AccessIfOperational" SG_ 1497 HVTU_OD_ChipUID1 1;
BA_ "CANzero_SDO_AccessType" SG_ 1497 HVTU_OD_SdcOut 1;
BA_ "CANzero_SDO_AccessIfOperational" SG_ 1497 HVTU_OD_SdcOut 1;
BA_ "CANzero_SDO_AccessType" SG_ 1497 HVTU_OD_SdcIn 1;
BA_ "CANzero_SDO_AccessIfOperational" SG_ 1497 HVTU_OD_SdcIn 1;
BA_ "CANzero_SDO_AccessType" SG_ 1497 HVTU_OD_runtime 1;
BA_ "CANzero_SDO_AccessIfOperational" SG_ 1497 HVTU_OD_runtime 1;
BA_ "CANzero_SDO_AccessType" SG_ 1497 HVTU_OD_InputVoltage 1;
BA_ "CANzero_SDO_AccessIfOperational" SG_ 1497 HVTU_OD_InputVoltage 1;
BA_ "CANzero_SDO_AccessType" SG_ 1497 HVTU_OD_BoardTemp 1;
BA_ "CANzero_SDO_AccessIfOperational" SG_ 1497 HVTU_OD_BoardTemp 1;
BA_ "GenSigStartValue" SG_ 1497 HVTU_OD_BoardTemp 3000.0;
BA_ "CANzero_SDO_AccessType" SG_ 1497 HVTU_OD_MemFree 1;
BA_ "CANzero_SDO_AccessIfOperational" SG_ 1497 HVTU_OD_MemFree 1;
BA_ "CANzero_SDO_AccessType" SG_ 1497 HVTU_OD_CpuUsage 1;
BA_ "CANzero_SDO_AccessIfOperational" SG_ 1497 HVTU_OD_CpuUsage 1;
BA_ "CANzero_SDO_AccessIfOperational" SG_ 1497 HVTU_OD_OdEntrySendInterval 1;
BA_ "GenSigStartValue" SG_ 1497 HVTU_OD_OdEntrySendInterval 50.0;
BA_ "CANzero_SDO_Default" SG_ 1497 HVTU_OD_OdEntrySendInterval 50;
BA_ "CANzero_SDO_AccessIfOperational" SG_ 1497 HVTU_OD_SendOdOnBootup 1;
BA_ "CANzero_SDO_AccessIfOperational" SG_ 1497 HVTU_OD_HeartbeatInterval 1;
BA_ "GenSigStartValue" SG_ 1497 HVTU_OD_HeartbeatInterval 250.0;
BA_ "CANzero_SDO_Default" SG_ 1497 HVTU_OD_HeartbeatInterval 250;
BA_ "CANzero_SDO_AccessType" SG_ 1497 HVTU_OD_DbcVersion 1;
BA_ "CANzero_SDO_AccessIfOperational" SG_ 1497 HVTU_OD_DbcVersion 1;
BA_ "CANzero_SDO_AccessType" SG_ 1497 HVTU_OD_StackVersion 1;
BA_ "CANzero_SDO_AccessIfOperational" SG_ 1497 HVTU_OD_StackVersion 1;
BA_ "CANzero_SDO_AccessType" SG_ 1497 HVTU_OD_ProtocolVersion 1;
BA_ "CANzero_SDO_AccessIfOperational" SG_ 1497 HVTU_OD_ProtocolVersion 1;
BA_ "GenSigStartValue" SG_ 1497 HVTU_OD_ProtocolVersion 1.0;
BA_ "CANzero_SDO_Default" SG_ 1497 HVTU_OD_ProtocolVersion 1;
BA_ "CANzero_SDO_AccessType" SG_ 1497 HVTU_OD_NodeStatus 1;
BA_ "CANzero_SDO_AccessIfOperational" SG_ 1497 HVTU_OD_NodeStatus 1;
BA_ "CANzero_SDO_AccessType" SG_ 1497 HVTU_OD_NodeID 1;
BA_ "CANzero_SDO_AccessIfOperational" SG_ 1497 HVTU_OD_NodeID 1;
BA_ "CANzero_SDO_AccessType" SG_ 1442 TelemetryNode_OD_CanRestart 2;
BA_ "CANzero_SDO_AccessIfOperational" SG_ 1442 TelemetryNode_OD_CanRestart 1;
BA_ "CANzero_SDO_AccessType" SG_ 1442 TelemetryNode_OD_Reboot 2;
BA_ "CANzero_SDO_AccessIfOperational" SG_ 1442 TelemetryNode_OD_Reboot 1;
BA_ "CANzero_SDO_AccessType" SG_ 1442 TelemetryNode_OD_Shutdown 2;
BA_ "CANzero_SDO_AccessIfOperational" SG_ 1442 TelemetryNode_OD_Shutdown 1;
BA_ "CANzero_SDO_Group" SG_ 1442 TelemetryNode_OD_CAN2_DelayedTxM "CAN";
BA_ "CANzero_SDO_AccessType" SG_ 1442 TelemetryNode_OD_CAN2_DelayedTxM 1;
BA_ "CANzero_SDO_AccessIfOperational" SG_ 1442 TelemetryNode_OD_CAN2_DelayedTxM 1;
BA_ "SystemSignalLongSymbol" SG_ 1442 TelemetryNode_OD_CAN2_DelayedTxM "TelemetryNode_OD_CAN2_DelayedTxMessages";
BA_ "CANzero_SDO_Group" SG_ 1442 TelemetryNode_OD_CAN2_ErrorStatu "CAN";
BA_ "CANzero_SDO_AccessType" SG_ 1442 TelemetryNode_OD_CAN2_ErrorStatu 1;
BA_ "CANzero_SDO_AccessIfOperational" SG_ 1442 TelemetryNode_OD_CAN2_ErrorStatu 1;
BA_ "SystemSignalLongSymbol" SG_ 1442 TelemetryNode_OD_CAN2_ErrorStatu "TelemetryNode_OD_CAN2_ErrorStatus";
BA_ "CANzero_SDO_Group" SG_ 1442 TelemetryNode_OD_CAN2_DiscardedT "CAN";
BA_ "CANzero_SDO_AccessType" SG_ 1442 TelemetryNode_OD_CAN2_DiscardedT 1;
BA_ "CANzero_SDO_AccessIfOperational" SG_ 1442 TelemetryNode_OD_CAN2_DiscardedT 1;
BA_ "SystemSignalLongSymbol" SG_ 1442 TelemetryNode_OD_CAN2_DiscardedT "TelemetryNode_OD_CAN2_DiscardedTxMessages";
BA_ "CANzero_SDO_Group" SG_ 1442 TelemetryNode_OD_CAN2_Status "CAN";
BA_ "CANzero_SDO_AccessType" SG_ 1442 TelemetryNode_OD_CAN2_Status 1;
BA_ "CANzero_SDO_AccessIfOperational" SG_ 1442 TelemetryNode_OD_CAN2_Status 1;
BA_ "CANzero_SDO_Group" SG_ 1442 TelemetryNode_OD_CAN2_Baudrate "CAN";
BA_ "CANzero_SDO_AccessIfOperational" SG_ 1442 TelemetryNode_OD_CAN2_Baudrate 1;
BA_ "GenSigStartValue" SG_ 1442 TelemetryNode_OD_CAN2_Baudrate 1000.0;
BA_ "CANzero_SDO_Default" SG_ 1442 TelemetryNode_OD_CAN2_Baudrate 1000;
BA_ "CANzero_SDO_Group" SG_ 1442 TelemetryNode_OD_CAN2_autoErrorR "CAN";
BA_ "CANzero_SDO_AccessIfOperational" SG_ 1442 TelemetryNode_OD_CAN2_autoErrorR 1;
BA_ "GenSigStartValue" SG_ 1442 TelemetryNode_OD_CAN2_autoErrorR 1.0;
BA_ "CANzero_SDO_Default" SG_ 1442 TelemetryNode_OD_CAN2_autoErrorR 1;
BA_ "SystemSignalLongSymbol" SG_ 1442 TelemetryNode_OD_CAN2_autoErrorR "TelemetryNode_OD_CAN2_autoErrorReset";
BA_ "CANzero_SDO_Group" SG_ 1442 TelemetryNode_OD_CAN2_lastErrorC "CAN";
BA_ "CANzero_SDO_AccessType" SG_ 1442 TelemetryNode_OD_CAN2_lastErrorC 1;
BA_ "CANzero_SDO_AccessIfOperational" SG_ 1442 TelemetryNode_OD_CAN2_lastErrorC 1;
BA_ "SystemSignalLongSymbol" SG_ 1442 TelemetryNode_OD_CAN2_lastErrorC "TelemetryNode_OD_CAN2_lastErrorCode";
BA_ "CANzero_SDO_Group" SG_ 1442 TelemetryNode_OD_CAN2_RxErrCnt "CAN";
BA_ "CANzero_SDO_AccessType" SG_ 1442 TelemetryNode_OD_CAN2_RxErrCnt 1;
BA_ "CANzero_SDO_AccessIfOperational" SG_ 1442 TelemetryNode_OD_CAN2_RxErrCnt 1;
BA_ "CANzero_SDO_Group" SG_ 1442 TelemetryNode_OD_CAN2_TxErrCnt "CAN";
BA_ "CANzero_SDO_AccessType" SG_ 1442 TelemetryNode_OD_CAN2_TxErrCnt 1;
BA_ "CANzero_SDO_AccessIfOperational" SG_ 1442 TelemetryNode_OD_CAN2_TxErrCnt 1;
BA_ "CANzero_SDO_Group" SG_ 1442 TelemetryNode_OD_CAN1_DelayedTxM "CAN";
BA_ "CANzero_SDO_AccessType" SG_ 1442 TelemetryNode_OD_CAN1_DelayedTxM 1;
BA_ "CANzero_SDO_AccessIfOperational" SG_ 1442 TelemetryNode_OD_CAN1_DelayedTxM 1;
BA_ "SystemSignalLongSymbol" SG_ 1442 TelemetryNode_OD_CAN1_DelayedTxM "TelemetryNode_OD_CAN1_DelayedTxMessages";
BA_ "CANzero_SDO_Group" SG_ 1442 TelemetryNode_OD_CAN1_ErrorStatu "CAN";
BA_ "CANzero_SDO_AccessType" SG_ 1442 TelemetryNode_OD_CAN1_ErrorStatu 1;
BA_ "CANzero_SDO_AccessIfOperational" SG_ 1442 TelemetryNode_OD_CAN1_ErrorStatu 1;
BA_ "SystemSignalLongSymbol" SG_ 1442 TelemetryNode_OD_CAN1_ErrorStatu "TelemetryNode_OD_CAN1_ErrorStatus";
BA_ "CANzero_SDO_Group" SG_ 1442 TelemetryNode_OD_CAN1_DiscardedT "CAN";
BA_ "CANzero_SDO_AccessType" SG_ 1442 TelemetryNode_OD_CAN1_DiscardedT 1;
BA_ "CANzero_SDO_AccessIfOperational" SG_ 1442 TelemetryNode_OD_CAN1_DiscardedT 1;
BA_ "SystemSignalLongSymbol" SG_ 1442 TelemetryNode_OD_CAN1_DiscardedT "TelemetryNode_OD_CAN1_DiscardedTxMessages";
BA_ "CANzero_SDO_Group" SG_ 1442 TelemetryNode_OD_CAN1_Status "CAN";
BA_ "CANzero_SDO_AccessType" SG_ 1442 TelemetryNode_OD_CAN1_Status 1;
BA_ "CANzero_SDO_AccessIfOperational" SG_ 1442 TelemetryNode_OD_CAN1_Status 1;
BA_ "CANzero_SDO_Group" SG_ 1442 TelemetryNode_OD_CAN1_Baudrate "CAN";
BA_ "CANzero_SDO_AccessIfOperational" SG_ 1442 TelemetryNode_OD_CAN1_Baudrate 1;
BA_ "GenSigStartValue" SG_ 1442 TelemetryNode_OD_CAN1_Baudrate 1000.0;
BA_ "CANzero_SDO_Default" SG_ 1442 TelemetryNode_OD_CAN1_Baudrate 1000;
BA_ "CANzero_SDO_Group" SG_ 1442 TelemetryNode_OD_CAN1_autoErrorR "CAN";
BA_ "CANzero_SDO_AccessIfOperational" SG_ 1442 TelemetryNode_OD_CAN1_autoErrorR 1;
BA_ "GenSigStartValue" SG_ 1442 TelemetryNode_OD_CAN1_autoErrorR 1.0;
BA_ "CANzero_SDO_Default" SG_ 1442 TelemetryNode_OD_CAN1_autoErrorR 1;
BA_ "SystemSignalLongSymbol" SG_ 1442 TelemetryNode_OD_CAN1_autoErrorR "TelemetryNode_OD_CAN1_autoErrorReset";
BA_ "CANzero_SDO_Group" SG_ 1442 TelemetryNode_OD_CAN1_lastErrorC "CAN";
BA_ "CANzero_SDO_AccessType" SG_ 1442 TelemetryNode_OD_CAN1_lastErrorC 1;
BA_ "CANzero_SDO_AccessIfOperational" SG_ 1442 TelemetryNode_OD_CAN1_lastErrorC 1;
BA_ "SystemSignalLongSymbol" SG_ 1442 TelemetryNode_OD_CAN1_lastErrorC "TelemetryNode_OD_CAN1_lastErrorCode";
BA_ "CANzero_SDO_Group" SG_ 1442 TelemetryNode_OD_CAN1_RxErrCnt "CAN";
BA_ "CANzero_SDO_AccessType" SG_ 1442 TelemetryNode_OD_CAN1_RxErrCnt 1;
BA_ "CANzero_SDO_AccessIfOperational" SG_ 1442 TelemetryNode_OD_CAN1_RxErrCnt 1;
BA_ "CANzero_SDO_Group" SG_ 1442 TelemetryNode_OD_CAN1_TxErrCnt "CAN";
BA_ "CANzero_SDO_AccessType" SG_ 1442 TelemetryNode_OD_CAN1_TxErrCnt 1;
BA_ "CANzero_SDO_AccessIfOperational" SG_ 1442 TelemetryNode_OD_CAN1_TxErrCnt 1;
BA_ "CANzero_SDO_AccessType" SG_ 1442 TelemetryNode_OD_BuildTime 1;
BA_ "CANzero_SDO_AccessIfOperational" SG_ 1442 TelemetryNode_OD_BuildTime 1;
BA_ "CANzero_SDO_AccessType" SG_ 1442 TelemetryNode_OD_BuildDate 1;
BA_ "CANzero_SDO_AccessIfOperational" SG_ 1442 TelemetryNode_OD_BuildDate 1;
BA_ "CANzero_SDO_AccessType" SG_ 1442 TelemetryNode_OD_ChipUID2 1;
BA_ "CANzero_SDO_AccessIfOperational" SG_ 1442 TelemetryNode_OD_ChipUID2 1;
BA_ "CANzero_SDO_AccessType" SG_ 1442 TelemetryNode_OD_ChipUID1 1;
BA_ "CANzero_SDO_AccessIfOperational" SG_ 1442 TelemetryNode_OD_ChipUID1 1;
BA_ "CANzero_SDO_AccessType" SG_ 1442 TelemetryNode_OD_SdcOut 1;
BA_ "CANzero_SDO_AccessIfOperational" SG_ 1442 TelemetryNode_OD_SdcOut 1;
BA_ "CANzero_SDO_AccessType" SG_ 1442 TelemetryNode_OD_SdcIn 1;
BA_ "CANzero_SDO_AccessIfOperational" SG_ 1442 TelemetryNode_OD_SdcIn 1;
BA_ "CANzero_SDO_AccessType" SG_ 1442 TelemetryNode_OD_runtime 1;
BA_ "CANzero_SDO_AccessIfOperational" SG_ 1442 TelemetryNode_OD_runtime 1;
BA_ "CANzero_SDO_AccessType" SG_ 1442 TelemetryNode_OD_InputVoltage 1;
BA_ "CANzero_SDO_AccessIfOperational" SG_ 1442 TelemetryNode_OD_InputVoltage 1;
BA_ "CANzero_SDO_AccessType" SG_ 1442 TelemetryNode_OD_BoardTemp 1;
BA_ "CANzero_SDO_AccessIfOperational" SG_ 1442 TelemetryNode_OD_BoardTemp 1;
BA_ "GenSigStartValue" SG_ 1442 TelemetryNode_OD_BoardTemp 3000.0;
BA_ "CANzero_SDO_AccessType" SG_ 1442 TelemetryNode_OD_MemFree 1;
BA_ "CANzero_SDO_AccessIfOperational" SG_ 1442 TelemetryNode_OD_MemFree 1;
BA_ "CANzero_SDO_AccessType" SG_ 1442 TelemetryNode_OD_CpuUsage 1;
BA_ "CANzero_SDO_AccessIfOperational" SG_ 1442 TelemetryNode_OD_CpuUsage 1;
BA_ "CANzero_SDO_AccessIfOperational" SG_ 1442 TelemetryNode_OD_OdEntrySendInte 1;
BA_ "GenSigStartValue" SG_ 1442 TelemetryNode_OD_OdEntrySendInte 50.0;
BA_ "CANzero_SDO_Default" SG_ 1442 TelemetryNode_OD_OdEntrySendInte 50;
BA_ "SystemSignalLongSymbol" SG_ 1442 TelemetryNode_OD_OdEntrySendInte "TelemetryNode_OD_OdEntrySendInterval";
BA_ "CANzero_SDO_AccessIfOperational" SG_ 1442 TelemetryNode_OD_SendOdOnBootup 1;
BA_ "CANzero_SDO_AccessIfOperational" SG_ 1442 TelemetryNode_OD_HeartbeatInterv 1;
BA_ "GenSigStartValue" SG_ 1442 TelemetryNode_OD_HeartbeatInterv 250.0;
BA_ "CANzero_SDO_Default" SG_ 1442 TelemetryNode_OD_HeartbeatInterv 250;
BA_ "SystemSignalLongSymbol" SG_ 1442 TelemetryNode_OD_HeartbeatInterv "TelemetryNode_OD_HeartbeatInterval";
BA_ "CANzero_SDO_AccessType" SG_ 1442 TelemetryNode_OD_DbcVersion 1;
BA_ "CANzero_SDO_AccessIfOperational" SG_ 1442 TelemetryNode_OD_DbcVersion 1;
BA_ "CANzero_SDO_AccessType" SG_ 1442 TelemetryNode_OD_StackVersion 1;
BA_ "CANzero_SDO_AccessIfOperational" SG_ 1442 TelemetryNode_OD_StackVersion 1;
BA_ "CANzero_SDO_AccessType" SG_ 1442 TelemetryNode_OD_ProtocolVersion 1;
BA_ "CANzero_SDO_AccessIfOperational" SG_ 1442 TelemetryNode_OD_ProtocolVersion 1;
BA_ "GenSigStartValue" SG_ 1442 TelemetryNode_OD_ProtocolVersion 1.0;
BA_ "CANzero_SDO_Default" SG_ 1442 TelemetryNode_OD_ProtocolVersion 1;
BA_ "CANzero_SDO_AccessType" SG_ 1442 TelemetryNode_OD_NodeStatus 1;
BA_ "CANzero_SDO_AccessIfOperational" SG_ 1442 TelemetryNode_OD_NodeStatus 1;
BA_ "CANzero_SDO_AccessType" SG_ 1442 TelemetryNode_OD_NodeID 1;
BA_ "CANzero_SDO_AccessIfOperational" SG_ 1442 TelemetryNode_OD_NodeID 1;
BA_ "CANzero_SDO_AccessType" SG_ 1506 TelemetryNode_OD_CanRestart 2;
BA_ "CANzero_SDO_AccessIfOperational" SG_ 1506 TelemetryNode_OD_CanRestart 1;
BA_ "CANzero_SDO_AccessType" SG_ 1506 TelemetryNode_OD_Reboot 2;
BA_ "CANzero_SDO_AccessIfOperational" SG_ 1506 TelemetryNode_OD_Reboot 1;
BA_ "CANzero_SDO_AccessType" SG_ 1506 TelemetryNode_OD_Shutdown 2;
BA_ "CANzero_SDO_AccessIfOperational" SG_ 1506 TelemetryNode_OD_Shutdown 1;
BA_ "CANzero_SDO_Group" SG_ 1506 TelemetryNode_OD_CAN2_Delay_0000 "CAN";
BA_ "CANzero_SDO_AccessType" SG_ 1506 TelemetryNode_OD_CAN2_Delay_0000 1;
BA_ "CANzero_SDO_AccessIfOperational" SG_ 1506 TelemetryNode_OD_CAN2_Delay_0000 1;
BA_ "SystemSignalLongSymbol" SG_ 1506 TelemetryNode_OD_CAN2_Delay_0000 "TelemetryNode_OD_CAN2_DelayedTxMessages";
BA_ "CANzero_SDO_Group" SG_ 1506 TelemetryNode_OD_CAN2_Error_0000 "CAN";
BA_ "CANzero_SDO_AccessType" SG_ 1506 TelemetryNode_OD_CAN2_Error_0000 1;
BA_ "CANzero_SDO_AccessIfOperational" SG_ 1506 TelemetryNode_OD_CAN2_Error_0000 1;
BA_ "SystemSignalLongSymbol" SG_ 1506 TelemetryNode_OD_CAN2_Error_0000 "TelemetryNode_OD_CAN2_ErrorStatus";
BA_ "CANzero_SDO_Group" SG_ 1506 TelemetryNode_OD_CAN2_Disca_0000 "CAN";
BA_ "CANzero_SDO_AccessType" SG_ 1506 TelemetryNode_OD_CAN2_Disca_0000 1;
BA_ "CANzero_SDO_AccessIfOperational" SG_ 1506 TelemetryNode_OD_CAN2_Disca_0000 1;
BA_ "SystemSignalLongSymbol" SG_ 1506 TelemetryNode_OD_CAN2_Disca_0000 "TelemetryNode_OD_CAN2_DiscardedTxMessages";
BA_ "CANzero_SDO_Group" SG_ 1506 TelemetryNode_OD_CAN2_Status "CAN";
BA_ "CANzero_SDO_AccessType" SG_ 1506 TelemetryNode_OD_CAN2_Status 1;
BA_ "CANzero_SDO_AccessIfOperational" SG_ 1506 TelemetryNode_OD_CAN2_Status 1;
BA_ "CANzero_SDO_Group" SG_ 1506 TelemetryNode_OD_CAN2_Baudrate "CAN";
BA_ "CANzero_SDO_AccessIfOperational" SG_ 1506 TelemetryNode_OD_CAN2_Baudrate 1;
BA_ "GenSigStartValue" SG_ 1506 TelemetryNode_OD_CAN2_Baudrate 1000.0;
BA_ "CANzero_SDO_Default" SG_ 1506 TelemetryNode_OD_CAN2_Baudrate 1000;
BA_ "CANzero_SDO_Group" SG_ 1506 TelemetryNode_OD_CAN2_autoE_0000 "CAN";
BA_ "CANzero_SDO_AccessIfOperational" SG_ 1506 TelemetryNode_OD_CAN2_autoE_0000 1;
BA_ "GenSigStartValue" SG_ 1506 TelemetryNode_OD_CAN2_autoE_0000 1.0;
BA_ "CANzero_SDO_Default" SG_ 1506 TelemetryNode_OD_CAN2_autoE_0000 1;
BA_ "SystemSignalLongSymbol" SG_ 1506 TelemetryNode_OD_CAN2_autoE_0000 "TelemetryNode_OD_CAN2_autoErrorReset";
BA_ "CANzero_SDO_Group" SG_ 1506 TelemetryNode_OD_CAN2_lastE_0000 "CAN";
BA_ "CANzero_SDO_AccessType" SG_ 1506 TelemetryNode_OD_CAN2_lastE_0000 1;
BA_ "CANzero_SDO_AccessIfOperational" SG_ 1506 TelemetryNode_OD_CAN2_lastE_0000 1;
BA_ "SystemSignalLongSymbol" SG_ 1506 TelemetryNode_OD_CAN2_lastE_0000 "TelemetryNode_OD_CAN2_lastErrorCode";
BA_ "CANzero_SDO_Group" SG_ 1506 TelemetryNode_OD_CAN2_RxErrCnt "CAN";
BA_ "CANzero_SDO_AccessType" SG_ 1506 TelemetryNode_OD_CAN2_RxErrCnt 1;
BA_ "CANzero_SDO_AccessIfOperational" SG_ 1506 TelemetryNode_OD_CAN2_RxErrCnt 1;
BA_ "CANzero_SDO_Group" SG_ 1506 TelemetryNode_OD_CAN2_TxErrCnt "CAN";
BA_ "CANzero_SDO_AccessType" SG_ 1506 TelemetryNode_OD_CAN2_TxErrCnt 1;
BA_ "CANzero_SDO_AccessIfOperational" SG_ 1506 TelemetryNode_OD_CAN2_TxErrCnt 1;
BA_ "CANzero_SDO_Group" SG_ 1506 TelemetryNode_OD_CAN1_Delay_0000 "CAN";
BA_ "CANzero_SDO_AccessType" SG_ 1506 TelemetryNode_OD_CAN1_Delay_0000 1;
BA_ "CANzero_SDO_AccessIfOperational" SG_ 1506 TelemetryNode_OD_CAN1_Delay_0000 1;
BA_ "SystemSignalLongSymbol" SG_ 1506 TelemetryNode_OD_CAN1_Delay_0000 "TelemetryNode_OD_CAN1_DelayedTxMessages";
BA_ "CANzero_SDO_Group" SG_ 1506 TelemetryNode_OD_CAN1_Error_0000 "CAN";
BA_ "CANzero_SDO_AccessType" SG_ 1506 TelemetryNode_OD_CAN1_Error_0000 1;
BA_ "CANzero_SDO_AccessIfOperational" SG_ 1506 TelemetryNode_OD_CAN1_Error_0000 1;
BA_ "SystemSignalLongSymbol" SG_ 1506 TelemetryNode_OD_CAN1_Error_0000 "TelemetryNode_OD_CAN1_ErrorStatus";
BA_ "CANzero_SDO_Group" SG_ 1506 TelemetryNode_OD_CAN1_Disca_0000 "CAN";
BA_ "CANzero_SDO_AccessType" SG_ 1506 TelemetryNode_OD_CAN1_Disca_0000 1;
BA_ "CANzero_SDO_AccessIfOperational" SG_ 1506 TelemetryNode_OD_CAN1_Disca_0000 1;
BA_ "SystemSignalLongSymbol" SG_ 1506 TelemetryNode_OD_CAN1_Disca_0000 "TelemetryNode_OD_CAN1_DiscardedTxMessages";
BA_ "CANzero_SDO_Group" SG_ 1506 TelemetryNode_OD_CAN1_Status "CAN";
BA_ "CANzero_SDO_AccessType" SG_ 1506 TelemetryNode_OD_CAN1_Status 1;
BA_ "CANzero_SDO_AccessIfOperational" SG_ 1506 TelemetryNode_OD_CAN1_Status 1;
BA_ "CANzero_SDO_Group" SG_ 1506 TelemetryNode_OD_CAN1_Baudrate "CAN";
BA_ "CANzero_SDO_AccessIfOperational" SG_ 1506 TelemetryNode_OD_CAN1_Baudrate 1;
BA_ "GenSigStartValue" SG_ 1506 TelemetryNode_OD_CAN1_Baudrate 1000.0;
BA_ "CANzero_SDO_Default" SG_ 1506 TelemetryNode_OD_CAN1_Baudrate 1000;
BA_ "CANzero_SDO_Group" SG_ 1506 TelemetryNode_OD_CAN1_autoE_0000 "CAN";
BA_ "CANzero_SDO_AccessIfOperational" SG_ 1506 TelemetryNode_OD_CAN1_autoE_0000 1;
BA_ "GenSigStartValue" SG_ 1506 TelemetryNode_OD_CAN1_autoE_0000 1.0;
BA_ "CANzero_SDO_Default" SG_ 1506 TelemetryNode_OD_CAN1_autoE_0000 1;
BA_ "SystemSignalLongSymbol" SG_ 1506 TelemetryNode_OD_CAN1_autoE_0000 "TelemetryNode_OD_CAN1_autoErrorReset";
BA_ "CANzero_SDO_Group" SG_ 1506 TelemetryNode_OD_CAN1_lastE_0000 "CAN";
BA_ "CANzero_SDO_AccessType" SG_ 1506 TelemetryNode_OD_CAN1_lastE_0000 1;
BA_ "CANzero_SDO_AccessIfOperational" SG_ 1506 TelemetryNode_OD_CAN1_lastE_0000 1;
BA_ "SystemSignalLongSymbol" SG_ 1506 TelemetryNode_OD_CAN1_lastE_0000 "TelemetryNode_OD_CAN1_lastErrorCode";
BA_ "CANzero_SDO_Group" SG_ 1506 TelemetryNode_OD_CAN1_RxErrCnt "CAN";
BA_ "CANzero_SDO_AccessType" SG_ 1506 TelemetryNode_OD_CAN1_RxErrCnt 1;
BA_ "CANzero_SDO_AccessIfOperational" SG_ 1506 TelemetryNode_OD_CAN1_RxErrCnt 1;
BA_ "CANzero_SDO_Group" SG_ 1506 TelemetryNode_OD_CAN1_TxErrCnt "CAN";
BA_ "CANzero_SDO_AccessType" SG_ 1506 TelemetryNode_OD_CAN1_TxErrCnt 1;
BA_ "CANzero_SDO_AccessIfOperational" SG_ 1506 TelemetryNode_OD_CAN1_TxErrCnt 1;
BA_ "CANzero_SDO_AccessType" SG_ 1506 TelemetryNode_OD_BuildTime 1;
BA_ "CANzero_SDO_AccessIfOperational" SG_ 1506 TelemetryNode_OD_BuildTime 1;
BA_ "CANzero_SDO_AccessType" SG_ 1506 TelemetryNode_OD_BuildDate 1;
BA_ "CANzero_SDO_AccessIfOperational" SG_ 1506 TelemetryNode_OD_BuildDate 1;
BA_ "CANzero_SDO_AccessType" SG_ 1506 TelemetryNode_OD_ChipUID2 1;
BA_ "CANzero_SDO_AccessIfOperational" SG_ 1506 TelemetryNode_OD_ChipUID2 1;
BA_ "CANzero_SDO_AccessType" SG_ 1506 TelemetryNode_OD_ChipUID1 1;
BA_ "CANzero_SDO_AccessIfOperational" SG_ 1506 TelemetryNode_OD_ChipUID1 1;
BA_ "CANzero_SDO_AccessType" SG_ 1506 TelemetryNode_OD_SdcOut 1;
BA_ "CANzero_SDO_AccessIfOperational" SG_ 1506 TelemetryNode_OD_SdcOut 1;
BA_ "CANzero_SDO_AccessType" SG_ 1506 TelemetryNode_OD_SdcIn 1;
BA_ "CANzero_SDO_AccessIfOperational" SG_ 1506 TelemetryNode_OD_SdcIn 1;
BA_ "CANzero_SDO_AccessType" SG_ 1506 TelemetryNode_OD_runtime 1;
BA_ "CANzero_SDO_AccessIfOperational" SG_ 1506 TelemetryNode_OD_runtime 1;
BA_ "CANzero_SDO_AccessType" SG_ 1506 TelemetryNode_OD_InputVoltage 1;
BA_ "CANzero_SDO_AccessIfOperational" SG_ 1506 TelemetryNode_OD_InputVoltage 1;
BA_ "CANzero_SDO_AccessType" SG_ 1506 TelemetryNode_OD_BoardTemp 1;
BA_ "CANzero_SDO_AccessIfOperational" SG_ 1506 TelemetryNode_OD_BoardTemp 1;
BA_ "GenSigStartValue" SG_ 1506 TelemetryNode_OD_BoardTemp 3000.0;
BA_ "CANzero_SDO_AccessType" SG_ 1506 TelemetryNode_OD_MemFree 1;
BA_ "CANzero_SDO_AccessIfOperational" SG_ 1506 TelemetryNode_OD_MemFree 1;
BA_ "CANzero_SDO_AccessType" SG_ 1506 TelemetryNode_OD_CpuUsage 1;
BA_ "CANzero_SDO_AccessIfOperational" SG_ 1506 TelemetryNode_OD_CpuUsage 1;
BA_ "CANzero_SDO_AccessIfOperational" SG_ 1506 TelemetryNode_OD_OdEntrySen_0000 1;
BA_ "GenSigStartValue" SG_ 1506 TelemetryNode_OD_OdEntrySen_0000 50.0;
BA_ "CANzero_SDO_Default" SG_ 1506 TelemetryNode_OD_OdEntrySen_0000 50;
BA_ "SystemSignalLongSymbol" SG_ 1506 TelemetryNode_OD_OdEntrySen_0000 "TelemetryNode_OD_OdEntrySendInterval";
BA_ "CANzero_SDO_AccessIfOperational" SG_ 1506 TelemetryNode_OD_SendOdOnBootup 1;
BA_ "CANzero_SDO_AccessIfOperational" SG_ 1506 TelemetryNode_OD_HeartbeatI_0000 1;
BA_ "GenSigStartValue" SG_ 1506 TelemetryNode_OD_HeartbeatI_0000 250.0;
BA_ "CANzero_SDO_Default" SG_ 1506 TelemetryNode_OD_HeartbeatI_0000 250;
BA_ "SystemSignalLongSymbol" SG_ 1506 TelemetryNode_OD_HeartbeatI_0000 "TelemetryNode_OD_HeartbeatInterval";
BA_ "CANzero_SDO_AccessType" SG_ 1506 TelemetryNode_OD_DbcVersion 1;
BA_ "CANzero_SDO_AccessIfOperational" SG_ 1506 TelemetryNode_OD_DbcVersion 1;
BA_ "CANzero_SDO_AccessType" SG_ 1506 TelemetryNode_OD_StackVersion 1;
BA_ "CANzero_SDO_AccessIfOperational" SG_ 1506 TelemetryNode_OD_StackVersion 1;
BA_ "CANzero_SDO_AccessType" SG_ 1506 TelemetryNode_OD_ProtocolVersion 1;
BA_ "CANzero_SDO_AccessIfOperational" SG_ 1506 TelemetryNode_OD_ProtocolVersion 1;
BA_ "GenSigStartValue" SG_ 1506 TelemetryNode_OD_ProtocolVersion 1.0;
BA_ "CANzero_SDO_Default" SG_ 1506 TelemetryNode_OD_ProtocolVersion 1;
BA_ "CANzero_SDO_AccessType" SG_ 1506 TelemetryNode_OD_NodeStatus 1;
BA_ "CANzero_SDO_AccessIfOperational" SG_ 1506 TelemetryNode_OD_NodeStatus 1;
BA_ "CANzero_SDO_AccessType" SG_ 1506 TelemetryNode_OD_NodeID 1;
BA_ "CANzero_SDO_AccessIfOperational" SG_ 1506 TelemetryNode_OD_NodeID 1;
BA_ "CANzero_SDO_Group" SG_ 1441 MDB1_OD_CAN2_DelayedTxMessages "CAN";
BA_ "CANzero_SDO_AccessType" SG_ 1441 MDB1_OD_CAN2_DelayedTxMessages 1;
BA_ "CANzero_SDO_AccessIfOperational" SG_ 1441 MDB1_OD_CAN2_DelayedTxMessages 1;
BA_ "CANzero_SDO_Group" SG_ 1441 MDB1_OD_CAN2_ErrorStatus "CAN";
BA_ "CANzero_SDO_AccessType" SG_ 1441 MDB1_OD_CAN2_ErrorStatus 1;
BA_ "CANzero_SDO_AccessIfOperational" SG_ 1441 MDB1_OD_CAN2_ErrorStatus 1;
BA_ "CANzero_SDO_Group" SG_ 1441 MDB1_OD_CAN2_DiscardedTxMessages "CAN";
BA_ "CANzero_SDO_AccessType" SG_ 1441 MDB1_OD_CAN2_DiscardedTxMessages 1;
BA_ "CANzero_SDO_AccessIfOperational" SG_ 1441 MDB1_OD_CAN2_DiscardedTxMessages 1;
BA_ "CANzero_SDO_Group" SG_ 1441 MDB1_OD_CAN2_Status "CAN";
BA_ "CANzero_SDO_AccessType" SG_ 1441 MDB1_OD_CAN2_Status 1;
BA_ "CANzero_SDO_AccessIfOperational" SG_ 1441 MDB1_OD_CAN2_Status 1;
BA_ "CANzero_SDO_Group" SG_ 1441 MDB1_OD_CAN2_Baudrate "CAN";
BA_ "CANzero_SDO_AccessIfOperational" SG_ 1441 MDB1_OD_CAN2_Baudrate 1;
BA_ "GenSigStartValue" SG_ 1441 MDB1_OD_CAN2_Baudrate 1000.0;
BA_ "CANzero_SDO_Default" SG_ 1441 MDB1_OD_CAN2_Baudrate 1000;
BA_ "CANzero_SDO_Group" SG_ 1441 MDB1_OD_CAN2_autoErrorReset "CAN";
BA_ "CANzero_SDO_AccessIfOperational" SG_ 1441 MDB1_OD_CAN2_autoErrorReset 1;
BA_ "GenSigStartValue" SG_ 1441 MDB1_OD_CAN2_autoErrorReset 1.0;
BA_ "CANzero_SDO_Default" SG_ 1441 MDB1_OD_CAN2_autoErrorReset 1;
BA_ "CANzero_SDO_Group" SG_ 1441 MDB1_OD_CAN2_lastErrorCode "CAN";
BA_ "CANzero_SDO_AccessType" SG_ 1441 MDB1_OD_CAN2_lastErrorCode 1;
BA_ "CANzero_SDO_AccessIfOperational" SG_ 1441 MDB1_OD_CAN2_lastErrorCode 1;
BA_ "CANzero_SDO_Group" SG_ 1441 MDB1_OD_CAN2_RxErrCnt "CAN";
BA_ "CANzero_SDO_AccessType" SG_ 1441 MDB1_OD_CAN2_RxErrCnt 1;
BA_ "CANzero_SDO_AccessIfOperational" SG_ 1441 MDB1_OD_CAN2_RxErrCnt 1;
BA_ "CANzero_SDO_Group" SG_ 1441 MDB1_OD_CAN2_TxErrCnt "CAN";
BA_ "CANzero_SDO_AccessType" SG_ 1441 MDB1_OD_CAN2_TxErrCnt 1;
BA_ "CANzero_SDO_AccessIfOperational" SG_ 1441 MDB1_OD_CAN2_TxErrCnt 1;
BA_ "CANzero_SDO_Group" SG_ 1441 MDB1_OD_CAN1_DelayedTxMessages "CAN";
BA_ "CANzero_SDO_AccessType" SG_ 1441 MDB1_OD_CAN1_DelayedTxMessages 1;
BA_ "CANzero_SDO_AccessIfOperational" SG_ 1441 MDB1_OD_CAN1_DelayedTxMessages 1;
BA_ "CANzero_SDO_Group" SG_ 1441 MDB1_OD_CAN1_ErrorStatus "CAN";
BA_ "CANzero_SDO_AccessType" SG_ 1441 MDB1_OD_CAN1_ErrorStatus 1;
BA_ "CANzero_SDO_AccessIfOperational" SG_ 1441 MDB1_OD_CAN1_ErrorStatus 1;
BA_ "CANzero_SDO_Group" SG_ 1441 MDB1_OD_CAN1_DiscardedTxMessages "CAN";
BA_ "CANzero_SDO_AccessType" SG_ 1441 MDB1_OD_CAN1_DiscardedTxMessages 1;
BA_ "CANzero_SDO_AccessIfOperational" SG_ 1441 MDB1_OD_CAN1_DiscardedTxMessages 1;
BA_ "CANzero_SDO_Group" SG_ 1441 MDB1_OD_CAN1_Status "CAN";
BA_ "CANzero_SDO_AccessType" SG_ 1441 MDB1_OD_CAN1_Status 1;
BA_ "CANzero_SDO_AccessIfOperational" SG_ 1441 MDB1_OD_CAN1_Status 1;
BA_ "CANzero_SDO_Group" SG_ 1441 MDB1_OD_CAN1_Baudrate "CAN";
BA_ "CANzero_SDO_AccessIfOperational" SG_ 1441 MDB1_OD_CAN1_Baudrate 1;
BA_ "GenSigStartValue" SG_ 1441 MDB1_OD_CAN1_Baudrate 1000.0;
BA_ "CANzero_SDO_Default" SG_ 1441 MDB1_OD_CAN1_Baudrate 1000;
BA_ "CANzero_SDO_Group" SG_ 1441 MDB1_OD_CAN1_autoErrorReset "CAN";
BA_ "CANzero_SDO_AccessIfOperational" SG_ 1441 MDB1_OD_CAN1_autoErrorReset 1;
BA_ "GenSigStartValue" SG_ 1441 MDB1_OD_CAN1_autoErrorReset 1.0;
BA_ "CANzero_SDO_Default" SG_ 1441 MDB1_OD_CAN1_autoErrorReset 1;
BA_ "CANzero_SDO_Group" SG_ 1441 MDB1_OD_CAN1_lastErrorCode "CAN";
BA_ "CANzero_SDO_AccessType" SG_ 1441 MDB1_OD_CAN1_lastErrorCode 1;
BA_ "CANzero_SDO_AccessIfOperational" SG_ 1441 MDB1_OD_CAN1_lastErrorCode 1;
BA_ "CANzero_SDO_Group" SG_ 1441 MDB1_OD_CAN1_RxErrCnt "CAN";
BA_ "CANzero_SDO_AccessType" SG_ 1441 MDB1_OD_CAN1_RxErrCnt 1;
BA_ "CANzero_SDO_AccessIfOperational" SG_ 1441 MDB1_OD_CAN1_RxErrCnt 1;
BA_ "CANzero_SDO_Group" SG_ 1441 MDB1_OD_CAN1_TxErrCnt "CAN";
BA_ "CANzero_SDO_AccessType" SG_ 1441 MDB1_OD_CAN1_TxErrCnt 1;
BA_ "CANzero_SDO_AccessIfOperational" SG_ 1441 MDB1_OD_CAN1_TxErrCnt 1;
BA_ "CANzero_SDO_AccessType" SG_ 1441 MDB1_OD_BuildTime 1;
BA_ "CANzero_SDO_AccessIfOperational" SG_ 1441 MDB1_OD_BuildTime 1;
BA_ "CANzero_SDO_AccessType" SG_ 1441 MDB1_OD_BuildDate 1;
BA_ "CANzero_SDO_AccessIfOperational" SG_ 1441 MDB1_OD_BuildDate 1;
BA_ "CANzero_SDO_AccessType" SG_ 1441 MDB1_OD_ChipUID2 1;
BA_ "CANzero_SDO_AccessIfOperational" SG_ 1441 MDB1_OD_ChipUID2 1;
BA_ "CANzero_SDO_AccessType" SG_ 1441 MDB1_OD_ChipUID1 1;
BA_ "CANzero_SDO_AccessIfOperational" SG_ 1441 MDB1_OD_ChipUID1 1;
BA_ "CANzero_SDO_AccessType" SG_ 1441 MDB1_OD_SdcOut 1;
BA_ "CANzero_SDO_AccessIfOperational" SG_ 1441 MDB1_OD_SdcOut 1;
BA_ "CANzero_SDO_AccessType" SG_ 1441 MDB1_OD_SdcIn 1;
BA_ "CANzero_SDO_AccessIfOperational" SG_ 1441 MDB1_OD_SdcIn 1;
BA_ "CANzero_SDO_AccessType" SG_ 1441 MDB1_OD_runtime 1;
BA_ "CANzero_SDO_AccessIfOperational" SG_ 1441 MDB1_OD_runtime 1;
BA_ "CANzero_SDO_AccessType" SG_ 1441 MDB1_OD_InputVoltage 1;
BA_ "CANzero_SDO_AccessIfOperational" SG_ 1441 MDB1_OD_InputVoltage 1;
BA_ "CANzero_SDO_AccessType" SG_ 1441 MDB1_OD_BoardTemp 1;
BA_ "CANzero_SDO_AccessIfOperational" SG_ 1441 MDB1_OD_BoardTemp 1;
BA_ "GenSigStartValue" SG_ 1441 MDB1_OD_BoardTemp 3000.0;
BA_ "CANzero_SDO_AccessType" SG_ 1441 MDB1_OD_MemFree 1;
BA_ "CANzero_SDO_AccessIfOperational" SG_ 1441 MDB1_OD_MemFree 1;
BA_ "CANzero_SDO_AccessType" SG_ 1441 MDB1_OD_CpuUsage 1;
BA_ "CANzero_SDO_AccessIfOperational" SG_ 1441 MDB1_OD_CpuUsage 1;
BA_ "CANzero_SDO_AccessIfOperational" SG_ 1441 MDB1_OD_OdEntrySendInterval 1;
BA_ "GenSigStartValue" SG_ 1441 MDB1_OD_OdEntrySendInterval 50.0;
BA_ "CANzero_SDO_Default" SG_ 1441 MDB1_OD_OdEntrySendInterval 50;
BA_ "CANzero_SDO_AccessIfOperational" SG_ 1441 MDB1_OD_SendOdOnBootup 1;
BA_ "CANzero_SDO_AccessIfOperational" SG_ 1441 MDB1_OD_HeartbeatInterval 1;
BA_ "GenSigStartValue" SG_ 1441 MDB1_OD_HeartbeatInterval 250.0;
BA_ "CANzero_SDO_Default" SG_ 1441 MDB1_OD_HeartbeatInterval 250;
BA_ "CANzero_SDO_AccessType" SG_ 1441 MDB1_OD_DbcVersion 1;
BA_ "CANzero_SDO_AccessIfOperational" SG_ 1441 MDB1_OD_DbcVersion 1;
BA_ "CANzero_SDO_AccessType" SG_ 1441 MDB1_OD_StackVersion 1;
BA_ "CANzero_SDO_AccessIfOperational" SG_ 1441 MDB1_OD_StackVersion 1;
BA_ "CANzero_SDO_AccessType" SG_ 1441 MDB1_OD_ProtocolVersion 1;
BA_ "CANzero_SDO_AccessIfOperational" SG_ 1441 MDB1_OD_ProtocolVersion 1;
BA_ "GenSigStartValue" SG_ 1441 MDB1_OD_ProtocolVersion 1.0;
BA_ "CANzero_SDO_Default" SG_ 1441 MDB1_OD_ProtocolVersion 1;
BA_ "CANzero_SDO_AccessType" SG_ 1441 MDB1_OD_NodeStatus 1;
BA_ "CANzero_SDO_AccessIfOperational" SG_ 1441 MDB1_OD_NodeStatus 1;
BA_ "CANzero_SDO_AccessType" SG_ 1441 MDB1_OD_NodeID 1;
BA_ "CANzero_SDO_AccessIfOperational" SG_ 1441 MDB1_OD_NodeID 1;
BA_ "CANzero_SDO_Group" SG_ 1505 MDB1_OD_CAN2_DelayedTxMessages "CAN";
BA_ "CANzero_SDO_AccessType" SG_ 1505 MDB1_OD_CAN2_DelayedTxMessages 1;
BA_ "CANzero_SDO_AccessIfOperational" SG_ 1505 MDB1_OD_CAN2_DelayedTxMessages 1;
BA_ "CANzero_SDO_Group" SG_ 1505 MDB1_OD_CAN2_ErrorStatus "CAN";
BA_ "CANzero_SDO_AccessType" SG_ 1505 MDB1_OD_CAN2_ErrorStatus 1;
BA_ "CANzero_SDO_AccessIfOperational" SG_ 1505 MDB1_OD_CAN2_ErrorStatus 1;
BA_ "CANzero_SDO_Group" SG_ 1505 MDB1_OD_CAN2_DiscardedTxMessages "CAN";
BA_ "CANzero_SDO_AccessType" SG_ 1505 MDB1_OD_CAN2_DiscardedTxMessages 1;
BA_ "CANzero_SDO_AccessIfOperational" SG_ 1505 MDB1_OD_CAN2_DiscardedTxMessages 1;
BA_ "CANzero_SDO_Group" SG_ 1505 MDB1_OD_CAN2_Status "CAN";
BA_ "CANzero_SDO_AccessType" SG_ 1505 MDB1_OD_CAN2_Status 1;
BA_ "CANzero_SDO_AccessIfOperational" SG_ 1505 MDB1_OD_CAN2_Status 1;
BA_ "CANzero_SDO_Group" SG_ 1505 MDB1_OD_CAN2_Baudrate "CAN";
BA_ "CANzero_SDO_AccessIfOperational" SG_ 1505 MDB1_OD_CAN2_Baudrate 1;
BA_ "GenSigStartValue" SG_ 1505 MDB1_OD_CAN2_Baudrate 1000.0;
BA_ "CANzero_SDO_Default" SG_ 1505 MDB1_OD_CAN2_Baudrate 1000;
BA_ "CANzero_SDO_Group" SG_ 1505 MDB1_OD_CAN2_autoErrorReset "CAN";
BA_ "CANzero_SDO_AccessIfOperational" SG_ 1505 MDB1_OD_CAN2_autoErrorReset 1;
BA_ "GenSigStartValue" SG_ 1505 MDB1_OD_CAN2_autoErrorReset 1.0;
BA_ "CANzero_SDO_Default" SG_ 1505 MDB1_OD_CAN2_autoErrorReset 1;
BA_ "CANzero_SDO_Group" SG_ 1505 MDB1_OD_CAN2_lastErrorCode "CAN";
BA_ "CANzero_SDO_AccessType" SG_ 1505 MDB1_OD_CAN2_lastErrorCode 1;
BA_ "CANzero_SDO_AccessIfOperational" SG_ 1505 MDB1_OD_CAN2_lastErrorCode 1;
BA_ "CANzero_SDO_Group" SG_ 1505 MDB1_OD_CAN2_RxErrCnt "CAN";
BA_ "CANzero_SDO_AccessType" SG_ 1505 MDB1_OD_CAN2_RxErrCnt 1;
BA_ "CANzero_SDO_AccessIfOperational" SG_ 1505 MDB1_OD_CAN2_RxErrCnt 1;
BA_ "CANzero_SDO_Group" SG_ 1505 MDB1_OD_CAN2_TxErrCnt "CAN";
BA_ "CANzero_SDO_AccessType" SG_ 1505 MDB1_OD_CAN2_TxErrCnt 1;
BA_ "CANzero_SDO_AccessIfOperational" SG_ 1505 MDB1_OD_CAN2_TxErrCnt 1;
BA_ "CANzero_SDO_Group" SG_ 1505 MDB1_OD_CAN1_DelayedTxMessages "CAN";
BA_ "CANzero_SDO_AccessType" SG_ 1505 MDB1_OD_CAN1_DelayedTxMessages 1;
BA_ "CANzero_SDO_AccessIfOperational" SG_ 1505 MDB1_OD_CAN1_DelayedTxMessages 1;
BA_ "CANzero_SDO_Group" SG_ 1505 MDB1_OD_CAN1_ErrorStatus "CAN";
BA_ "CANzero_SDO_AccessType" SG_ 1505 MDB1_OD_CAN1_ErrorStatus 1;
BA_ "CANzero_SDO_AccessIfOperational" SG_ 1505 MDB1_OD_CAN1_ErrorStatus 1;
BA_ "CANzero_SDO_Group" SG_ 1505 MDB1_OD_CAN1_DiscardedTxMessages "CAN";
BA_ "CANzero_SDO_AccessType" SG_ 1505 MDB1_OD_CAN1_DiscardedTxMessages 1;
BA_ "CANzero_SDO_AccessIfOperational" SG_ 1505 MDB1_OD_CAN1_DiscardedTxMessages 1;
BA_ "CANzero_SDO_Group" SG_ 1505 MDB1_OD_CAN1_Status "CAN";
BA_ "CANzero_SDO_AccessType" SG_ 1505 MDB1_OD_CAN1_Status 1;
BA_ "CANzero_SDO_AccessIfOperational" SG_ 1505 MDB1_OD_CAN1_Status 1;
BA_ "CANzero_SDO_Group" SG_ 1505 MDB1_OD_CAN1_Baudrate "CAN";
BA_ "CANzero_SDO_AccessIfOperational" SG_ 1505 MDB1_OD_CAN1_Baudrate 1;
BA_ "GenSigStartValue" SG_ 1505 MDB1_OD_CAN1_Baudrate 1000.0;
BA_ "CANzero_SDO_Default" SG_ 1505 MDB1_OD_CAN1_Baudrate 1000;
BA_ "CANzero_SDO_Group" SG_ 1505 MDB1_OD_CAN1_autoErrorReset "CAN";
BA_ "CANzero_SDO_AccessIfOperational" SG_ 1505 MDB1_OD_CAN1_autoErrorReset 1;
BA_ "GenSigStartValue" SG_ 1505 MDB1_OD_CAN1_autoErrorReset 1.0;
BA_ "CANzero_SDO_Default" SG_ 1505 MDB1_OD_CAN1_autoErrorReset 1;
BA_ "CANzero_SDO_Group" SG_ 1505 MDB1_OD_CAN1_lastErrorCode "CAN";
BA_ "CANzero_SDO_AccessType" SG_ 1505 MDB1_OD_CAN1_lastErrorCode 1;
BA_ "CANzero_SDO_AccessIfOperational" SG_ 1505 MDB1_OD_CAN1_lastErrorCode 1;
BA_ "CANzero_SDO_Group" SG_ 1505 MDB1_OD_CAN1_RxErrCnt "CAN";
BA_ "CANzero_SDO_AccessType" SG_ 1505 MDB1_OD_CAN1_RxErrCnt 1;
BA_ "CANzero_SDO_AccessIfOperational" SG_ 1505 MDB1_OD_CAN1_RxErrCnt 1;
BA_ "CANzero_SDO_Group" SG_ 1505 MDB1_OD_CAN1_TxErrCnt "CAN";
BA_ "CANzero_SDO_AccessType" SG_ 1505 MDB1_OD_CAN1_TxErrCnt 1;
BA_ "CANzero_SDO_AccessIfOperational" SG_ 1505 MDB1_OD_CAN1_TxErrCnt 1;
BA_ "CANzero_SDO_AccessType" SG_ 1505 MDB1_OD_BuildTime 1;
BA_ "CANzero_SDO_AccessIfOperational" SG_ 1505 MDB1_OD_BuildTime 1;
BA_ "CANzero_SDO_AccessType" SG_ 1505 MDB1_OD_BuildDate 1;
BA_ "CANzero_SDO_AccessIfOperational" SG_ 1505 MDB1_OD_BuildDate 1;
BA_ "CANzero_SDO_AccessType" SG_ 1505 MDB1_OD_ChipUID2 1;
BA_ "CANzero_SDO_AccessIfOperational" SG_ 1505 MDB1_OD_ChipUID2 1;
BA_ "CANzero_SDO_AccessType" SG_ 1505 MDB1_OD_ChipUID1 1;
BA_ "CANzero_SDO_AccessIfOperational" SG_ 1505 MDB1_OD_ChipUID1 1;
BA_ "CANzero_SDO_AccessType" SG_ 1505 MDB1_OD_SdcOut 1;
BA_ "CANzero_SDO_AccessIfOperational" SG_ 1505 MDB1_OD_SdcOut 1;
BA_ "CANzero_SDO_AccessType" SG_ 1505 MDB1_OD_SdcIn 1;
BA_ "CANzero_SDO_AccessIfOperational" SG_ 1505 MDB1_OD_SdcIn 1;
BA_ "CANzero_SDO_AccessType" SG_ 1505 MDB1_OD_runtime 1;
BA_ "CANzero_SDO_AccessIfOperational" SG_ 1505 MDB1_OD_runtime 1;
BA_ "CANzero_SDO_AccessType" SG_ 1505 MDB1_OD_InputVoltage 1;
BA_ "CANzero_SDO_AccessIfOperational" SG_ 1505 MDB1_OD_InputVoltage 1;
BA_ "CANzero_SDO_AccessType" SG_ 1505 MDB1_OD_BoardTemp 1;
BA_ "CANzero_SDO_AccessIfOperational" SG_ 1505 MDB1_OD_BoardTemp 1;
BA_ "GenSigStartValue" SG_ 1505 MDB1_OD_BoardTemp 3000.0;
BA_ "CANzero_SDO_AccessType" SG_ 1505 MDB1_OD_MemFree 1;
BA_ "CANzero_SDO_AccessIfOperational" SG_ 1505 MDB1_OD_MemFree 1;
BA_ "CANzero_SDO_AccessType" SG_ 1505 MDB1_OD_CpuUsage 1;
BA_ "CANzero_SDO_AccessIfOperational" SG_ 1505 MDB1_OD_CpuUsage 1;
BA_ "CANzero_SDO_AccessIfOperational" SG_ 1505 MDB1_OD_OdEntrySendInterval 1;
BA_ "GenSigStartValue" SG_ 1505 MDB1_OD_OdEntrySendInterval 50.0;
BA_ "CANzero_SDO_Default" SG_ 1505 MDB1_OD_OdEntrySendInterval 50;
BA_ "CANzero_SDO_AccessIfOperational" SG_ 1505 MDB1_OD_SendOdOnBootup 1;
BA_ "CANzero_SDO_AccessIfOperational" SG_ 1505 MDB1_OD_HeartbeatInterval 1;
BA_ "GenSigStartValue" SG_ 1505 MDB1_OD_HeartbeatInterval 250.0;
BA_ "CANzero_SDO_Default" SG_ 1505 MDB1_OD_HeartbeatInterval 250;
BA_ "CANzero_SDO_AccessType" SG_ 1505 MDB1_OD_DbcVersion 1;
BA_ "CANzero_SDO_AccessIfOperational" SG_ 1505 MDB1_OD_DbcVersion 1;
BA_ "CANzero_SDO_AccessType" SG_ 1505 MDB1_OD_StackVersion 1;
BA_ "CANzero_SDO_AccessIfOperational" SG_ 1505 MDB1_OD_StackVersion 1;
BA_ "CANzero_SDO_AccessType" SG_ 1505 MDB1_OD_ProtocolVersion 1;
BA_ "CANzero_SDO_AccessIfOperational" SG_ 1505 MDB1_OD_ProtocolVersion 1;
BA_ "GenSigStartValue" SG_ 1505 MDB1_OD_ProtocolVersion 1.0;
BA_ "CANzero_SDO_Default" SG_ 1505 MDB1_OD_ProtocolVersion 1;
BA_ "CANzero_SDO_AccessType" SG_ 1505 MDB1_OD_NodeStatus 1;
BA_ "CANzero_SDO_AccessIfOperational" SG_ 1505 MDB1_OD_NodeStatus 1;
BA_ "CANzero_SDO_AccessType" SG_ 1505 MDB1_OD_NodeID 1;
BA_ "CANzero_SDO_AccessIfOperational" SG_ 1505 MDB1_OD_NodeID 1;
BA_ "CANzero_SDO_Group" SG_ 1443 MDB2_OD_CAN2_DelayedTxMessages "CAN";
BA_ "CANzero_SDO_AccessType" SG_ 1443 MDB2_OD_CAN2_DelayedTxMessages 1;
BA_ "CANzero_SDO_AccessIfOperational" SG_ 1443 MDB2_OD_CAN2_DelayedTxMessages 1;
BA_ "CANzero_SDO_Group" SG_ 1443 MDB2_OD_CAN2_ErrorStatus "CAN";
BA_ "CANzero_SDO_AccessType" SG_ 1443 MDB2_OD_CAN2_ErrorStatus 1;
BA_ "CANzero_SDO_AccessIfOperational" SG_ 1443 MDB2_OD_CAN2_ErrorStatus 1;
BA_ "CANzero_SDO_Group" SG_ 1443 MDB2_OD_CAN2_DiscardedTxMessages "CAN";
BA_ "CANzero_SDO_AccessType" SG_ 1443 MDB2_OD_CAN2_DiscardedTxMessages 1;
BA_ "CANzero_SDO_AccessIfOperational" SG_ 1443 MDB2_OD_CAN2_DiscardedTxMessages 1;
BA_ "CANzero_SDO_Group" SG_ 1443 MDB2_OD_CAN2_Status "CAN";
BA_ "CANzero_SDO_AccessType" SG_ 1443 MDB2_OD_CAN2_Status 1;
BA_ "CANzero_SDO_AccessIfOperational" SG_ 1443 MDB2_OD_CAN2_Status 1;
BA_ "CANzero_SDO_Group" SG_ 1443 MDB2_OD_CAN2_Baudrate "CAN";
BA_ "CANzero_SDO_AccessIfOperational" SG_ 1443 MDB2_OD_CAN2_Baudrate 1;
BA_ "GenSigStartValue" SG_ 1443 MDB2_OD_CAN2_Baudrate 1000.0;
BA_ "CANzero_SDO_Default" SG_ 1443 MDB2_OD_CAN2_Baudrate 1000;
BA_ "CANzero_SDO_Group" SG_ 1443 MDB2_OD_CAN2_autoErrorReset "CAN";
BA_ "CANzero_SDO_AccessIfOperational" SG_ 1443 MDB2_OD_CAN2_autoErrorReset 1;
BA_ "GenSigStartValue" SG_ 1443 MDB2_OD_CAN2_autoErrorReset 1.0;
BA_ "CANzero_SDO_Default" SG_ 1443 MDB2_OD_CAN2_autoErrorReset 1;
BA_ "CANzero_SDO_Group" SG_ 1443 MDB2_OD_CAN2_lastErrorCode "CAN";
BA_ "CANzero_SDO_AccessType" SG_ 1443 MDB2_OD_CAN2_lastErrorCode 1;
BA_ "CANzero_SDO_AccessIfOperational" SG_ 1443 MDB2_OD_CAN2_lastErrorCode 1;
BA_ "CANzero_SDO_Group" SG_ 1443 MDB2_OD_CAN2_RxErrCnt "CAN";
BA_ "CANzero_SDO_AccessType" SG_ 1443 MDB2_OD_CAN2_RxErrCnt 1;
BA_ "CANzero_SDO_AccessIfOperational" SG_ 1443 MDB2_OD_CAN2_RxErrCnt 1;
BA_ "CANzero_SDO_Group" SG_ 1443 MDB2_OD_CAN2_TxErrCnt "CAN";
BA_ "CANzero_SDO_AccessType" SG_ 1443 MDB2_OD_CAN2_TxErrCnt 1;
BA_ "CANzero_SDO_AccessIfOperational" SG_ 1443 MDB2_OD_CAN2_TxErrCnt 1;
BA_ "CANzero_SDO_Group" SG_ 1443 MDB2_OD_CAN1_DelayedTxMessages "CAN";
BA_ "CANzero_SDO_AccessType" SG_ 1443 MDB2_OD_CAN1_DelayedTxMessages 1;
BA_ "CANzero_SDO_AccessIfOperational" SG_ 1443 MDB2_OD_CAN1_DelayedTxMessages 1;
BA_ "CANzero_SDO_Group" SG_ 1443 MDB2_OD_CAN1_ErrorStatus "CAN";
BA_ "CANzero_SDO_AccessType" SG_ 1443 MDB2_OD_CAN1_ErrorStatus 1;
BA_ "CANzero_SDO_AccessIfOperational" SG_ 1443 MDB2_OD_CAN1_ErrorStatus 1;
BA_ "CANzero_SDO_Group" SG_ 1443 MDB2_OD_CAN1_DiscardedTxMessages "CAN";
BA_ "CANzero_SDO_AccessType" SG_ 1443 MDB2_OD_CAN1_DiscardedTxMessages 1;
BA_ "CANzero_SDO_AccessIfOperational" SG_ 1443 MDB2_OD_CAN1_DiscardedTxMessages 1;
BA_ "CANzero_SDO_Group" SG_ 1443 MDB2_OD_CAN1_Status "CAN";
BA_ "CANzero_SDO_AccessType" SG_ 1443 MDB2_OD_CAN1_Status 1;
BA_ "CANzero_SDO_AccessIfOperational" SG_ 1443 MDB2_OD_CAN1_Status 1;
BA_ "CANzero_SDO_Group" SG_ 1443 MDB2_OD_CAN1_Baudrate "CAN";
BA_ "CANzero_SDO_AccessIfOperational" SG_ 1443 MDB2_OD_CAN1_Baudrate 1;
BA_ "GenSigStartValue" SG_ 1443 MDB2_OD_CAN1_Baudrate 1000.0;
BA_ "CANzero_SDO_Default" SG_ 1443 MDB2_OD_CAN1_Baudrate 1000;
BA_ "CANzero_SDO_Group" SG_ 1443 MDB2_OD_CAN1_autoErrorReset "CAN";
BA_ "CANzero_SDO_AccessIfOperational" SG_ 1443 MDB2_OD_CAN1_autoErrorReset 1;
BA_ "GenSigStartValue" SG_ 1443 MDB2_OD_CAN1_autoErrorReset 1.0;
BA_ "CANzero_SDO_Default" SG_ 1443 MDB2_OD_CAN1_autoErrorReset 1;
BA_ "CANzero_SDO_Group" SG_ 1443 MDB2_OD_CAN1_lastErrorCode "CAN";
BA_ "CANzero_SDO_AccessType" SG_ 1443 MDB2_OD_CAN1_lastErrorCode 1;
BA_ "CANzero_SDO_AccessIfOperational" SG_ 1443 MDB2_OD_CAN1_lastErrorCode 1;
BA_ "CANzero_SDO_Group" SG_ 1443 MDB2_OD_CAN1_RxErrCnt "CAN";
BA_ "CANzero_SDO_AccessType" SG_ 1443 MDB2_OD_CAN1_RxErrCnt 1;
BA_ "CANzero_SDO_AccessIfOperational" SG_ 1443 MDB2_OD_CAN1_RxErrCnt 1;
BA_ "CANzero_SDO_Group" SG_ 1443 MDB2_OD_CAN1_TxErrCnt "CAN";
BA_ "CANzero_SDO_AccessType" SG_ 1443 MDB2_OD_CAN1_TxErrCnt 1;
BA_ "CANzero_SDO_AccessIfOperational" SG_ 1443 MDB2_OD_CAN1_TxErrCnt 1;
BA_ "CANzero_SDO_AccessType" SG_ 1443 MDB2_OD_BuildTime 1;
BA_ "CANzero_SDO_AccessIfOperational" SG_ 1443 MDB2_OD_BuildTime 1;
BA_ "CANzero_SDO_AccessType" SG_ 1443 MDB2_OD_BuildDate 1;
BA_ "CANzero_SDO_AccessIfOperational" SG_ 1443 MDB2_OD_BuildDate 1;
BA_ "CANzero_SDO_AccessType" SG_ 1443 MDB2_OD_ChipUID2 1;
BA_ "CANzero_SDO_AccessIfOperational" SG_ 1443 MDB2_OD_ChipUID2 1;
BA_ "CANzero_SDO_AccessType" SG_ 1443 MDB2_OD_ChipUID1 1;
BA_ "CANzero_SDO_AccessIfOperational" SG_ 1443 MDB2_OD_ChipUID1 1;
BA_ "CANzero_SDO_AccessType" SG_ 1443 MDB2_OD_SdcOut 1;
BA_ "CANzero_SDO_AccessIfOperational" SG_ 1443 MDB2_OD_SdcOut 1;
BA_ "CANzero_SDO_AccessType" SG_ 1443 MDB2_OD_SdcIn 1;
BA_ "CANzero_SDO_AccessIfOperational" SG_ 1443 MDB2_OD_SdcIn 1;
BA_ "CANzero_SDO_AccessType" SG_ 1443 MDB2_OD_runtime 1;
BA_ "CANzero_SDO_AccessIfOperational" SG_ 1443 MDB2_OD_runtime 1;
BA_ "CANzero_SDO_AccessType" SG_ 1443 MDB2_OD_InputVoltage 1;
BA_ "CANzero_SDO_AccessIfOperational" SG_ 1443 MDB2_OD_InputVoltage 1;
BA_ "CANzero_SDO_AccessType" SG_ 1443 MDB2_OD_BoardTemp 1;
BA_ "CANzero_SDO_AccessIfOperational" SG_ 1443 MDB2_OD_BoardTemp 1;
BA_ "GenSigStartValue" SG_ 1443 MDB2_OD_BoardTemp 3000.0;
BA_ "CANzero_SDO_AccessType" SG_ 1443 MDB2_OD_MemFree 1;
BA_ "CANzero_SDO_AccessIfOperational" SG_ 1443 MDB2_OD_MemFree 1;
BA_ "CANzero_SDO_AccessType" SG_ 1443 MDB2_OD_CpuUsage 1;
BA_ "CANzero_SDO_AccessIfOperational" SG_ 1443 MDB2_OD_CpuUsage 1;
BA_ "CANzero_SDO_AccessIfOperational" SG_ 1443 MDB2_OD_OdEntrySendInterval 1;
BA_ "GenSigStartValue" SG_ 1443 MDB2_OD_OdEntrySendInterval 50.0;
BA_ "CANzero_SDO_Default" SG_ 1443 MDB2_OD_OdEntrySendInterval 50;
BA_ "CANzero_SDO_AccessIfOperational" SG_ 1443 MDB2_OD_SendOdOnBootup 1;
BA_ "CANzero_SDO_AccessIfOperational" SG_ 1443 MDB2_OD_HeartbeatInterval 1;
BA_ "GenSigStartValue" SG_ 1443 MDB2_OD_HeartbeatInterval 250.0;
BA_ "CANzero_SDO_Default" SG_ 1443 MDB2_OD_HeartbeatInterval 250;
BA_ "CANzero_SDO_AccessType" SG_ 1443 MDB2_OD_DbcVersion 1;
BA_ "CANzero_SDO_AccessIfOperational" SG_ 1443 MDB2_OD_DbcVersion 1;
BA_ "CANzero_SDO_AccessType" SG_ 1443 MDB2_OD_StackVersion 1;
BA_ "CANzero_SDO_AccessIfOperational" SG_ 1443 MDB2_OD_StackVersion 1;
BA_ "CANzero_SDO_AccessType" SG_ 1443 MDB2_OD_ProtocolVersion 1;
BA_ "CANzero_SDO_AccessIfOperational" SG_ 1443 MDB2_OD_ProtocolVersion 1;
BA_ "GenSigStartValue" SG_ 1443 MDB2_OD_ProtocolVersion 1.0;
BA_ "CANzero_SDO_Default" SG_ 1443 MDB2_OD_ProtocolVersion 1;
BA_ "CANzero_SDO_AccessType" SG_ 1443 MDB2_OD_NodeStatus 1;
BA_ "CANzero_SDO_AccessIfOperational" SG_ 1443 MDB2_OD_NodeStatus 1;
BA_ "CANzero_SDO_AccessType" SG_ 1443 MDB2_OD_NodeID 1;
BA_ "CANzero_SDO_AccessIfOperational" SG_ 1443 MDB2_OD_NodeID 1;
BA_ "CANzero_SDO_Group" SG_ 1507 MDB2_OD_CAN2_DelayedTxMessages "CAN";
BA_ "CANzero_SDO_AccessType" SG_ 1507 MDB2_OD_CAN2_DelayedTxMessages 1;
BA_ "CANzero_SDO_AccessIfOperational" SG_ 1507 MDB2_OD_CAN2_DelayedTxMessages 1;
BA_ "CANzero_SDO_Group" SG_ 1507 MDB2_OD_CAN2_ErrorStatus "CAN";
BA_ "CANzero_SDO_AccessType" SG_ 1507 MDB2_OD_CAN2_ErrorStatus 1;
BA_ "CANzero_SDO_AccessIfOperational" SG_ 1507 MDB2_OD_CAN2_ErrorStatus 1;
BA_ "CANzero_SDO_Group" SG_ 1507 MDB2_OD_CAN2_DiscardedTxMessages "CAN";
BA_ "CANzero_SDO_AccessType" SG_ 1507 MDB2_OD_CAN2_DiscardedTxMessages 1;
BA_ "CANzero_SDO_AccessIfOperational" SG_ 1507 MDB2_OD_CAN2_DiscardedTxMessages 1;
BA_ "CANzero_SDO_Group" SG_ 1507 MDB2_OD_CAN2_Status "CAN";
BA_ "CANzero_SDO_AccessType" SG_ 1507 MDB2_OD_CAN2_Status 1;
BA_ "CANzero_SDO_AccessIfOperational" SG_ 1507 MDB2_OD_CAN2_Status 1;
BA_ "CANzero_SDO_Group" SG_ 1507 MDB2_OD_CAN2_Baudrate "CAN";
BA_ "CANzero_SDO_AccessIfOperational" SG_ 1507 MDB2_OD_CAN2_Baudrate 1;
BA_ "GenSigStartValue" SG_ 1507 MDB2_OD_CAN2_Baudrate 1000.0;
BA_ "CANzero_SDO_Default" SG_ 1507 MDB2_OD_CAN2_Baudrate 1000;
BA_ "CANzero_SDO_Group" SG_ 1507 MDB2_OD_CAN2_autoErrorReset "CAN";
BA_ "CANzero_SDO_AccessIfOperational" SG_ 1507 MDB2_OD_CAN2_autoErrorReset 1;
BA_ "GenSigStartValue" SG_ 1507 MDB2_OD_CAN2_autoErrorReset 1.0;
BA_ "CANzero_SDO_Default" SG_ 1507 MDB2_OD_CAN2_autoErrorReset 1;
BA_ "CANzero_SDO_Group" SG_ 1507 MDB2_OD_CAN2_lastErrorCode "CAN";
BA_ "CANzero_SDO_AccessType" SG_ 1507 MDB2_OD_CAN2_lastErrorCode 1;
BA_ "CANzero_SDO_AccessIfOperational" SG_ 1507 MDB2_OD_CAN2_lastErrorCode 1;
BA_ "CANzero_SDO_Group" SG_ 1507 MDB2_OD_CAN2_RxErrCnt "CAN";
BA_ "CANzero_SDO_AccessType" SG_ 1507 MDB2_OD_CAN2_RxErrCnt 1;
BA_ "CANzero_SDO_AccessIfOperational" SG_ 1507 MDB2_OD_CAN2_RxErrCnt 1;
BA_ "CANzero_SDO_Group" SG_ 1507 MDB2_OD_CAN2_TxErrCnt "CAN";
BA_ "CANzero_SDO_AccessType" SG_ 1507 MDB2_OD_CAN2_TxErrCnt 1;
BA_ "CANzero_SDO_AccessIfOperational" SG_ 1507 MDB2_OD_CAN2_TxErrCnt 1;
BA_ "CANzero_SDO_Group" SG_ 1507 MDB2_OD_CAN1_DelayedTxMessages "CAN";
BA_ "CANzero_SDO_AccessType" SG_ 1507 MDB2_OD_CAN1_DelayedTxMessages 1;
BA_ "CANzero_SDO_AccessIfOperational" SG_ 1507 MDB2_OD_CAN1_DelayedTxMessages 1;
BA_ "CANzero_SDO_Group" SG_ 1507 MDB2_OD_CAN1_ErrorStatus "CAN";
BA_ "CANzero_SDO_AccessType" SG_ 1507 MDB2_OD_CAN1_ErrorStatus 1;
BA_ "CANzero_SDO_AccessIfOperational" SG_ 1507 MDB2_OD_CAN1_ErrorStatus 1;
BA_ "CANzero_SDO_Group" SG_ 1507 MDB2_OD_CAN1_DiscardedTxMessages "CAN";
BA_ "CANzero_SDO_AccessType" SG_ 1507 MDB2_OD_CAN1_DiscardedTxMessages 1;
BA_ "CANzero_SDO_AccessIfOperational" SG_ 1507 MDB2_OD_CAN1_DiscardedTxMessages 1;
BA_ "CANzero_SDO_Group" SG_ 1507 MDB2_OD_CAN1_Status "CAN";
BA_ "CANzero_SDO_AccessType" SG_ 1507 MDB2_OD_CAN1_Status 1;
BA_ "CANzero_SDO_AccessIfOperational" SG_ 1507 MDB2_OD_CAN1_Status 1;
BA_ "CANzero_SDO_Group" SG_ 1507 MDB2_OD_CAN1_Baudrate "CAN";
BA_ "CANzero_SDO_AccessIfOperational" SG_ 1507 MDB2_OD_CAN1_Baudrate 1;
BA_ "GenSigStartValue" SG_ 1507 MDB2_OD_CAN1_Baudrate 1000.0;
BA_ "CANzero_SDO_Default" SG_ 1507 MDB2_OD_CAN1_Baudrate 1000;
BA_ "CANzero_SDO_Group" SG_ 1507 MDB2_OD_CAN1_autoErrorReset "CAN";
BA_ "CANzero_SDO_AccessIfOperational" SG_ 1507 MDB2_OD_CAN1_autoErrorReset 1;
BA_ "GenSigStartValue" SG_ 1507 MDB2_OD_CAN1_autoErrorReset 1.0;
BA_ "CANzero_SDO_Default" SG_ 1507 MDB2_OD_CAN1_autoErrorReset 1;
BA_ "CANzero_SDO_Group" SG_ 1507 MDB2_OD_CAN1_lastErrorCode "CAN";
BA_ "CANzero_SDO_AccessType" SG_ 1507 MDB2_OD_CAN1_lastErrorCode 1;
BA_ "CANzero_SDO_AccessIfOperational" SG_ 1507 MDB2_OD_CAN1_lastErrorCode 1;
BA_ "CANzero_SDO_Group" SG_ 1507 MDB2_OD_CAN1_RxErrCnt "CAN";
BA_ "CANzero_SDO_AccessType" SG_ 1507 MDB2_OD_CAN1_RxErrCnt 1;
BA_ "CANzero_SDO_AccessIfOperational" SG_ 1507 MDB2_OD_CAN1_RxErrCnt 1;
BA_ "CANzero_SDO_Group" SG_ 1507 MDB2_OD_CAN1_TxErrCnt "CAN";
BA_ "CANzero_SDO_AccessType" SG_ 1507 MDB2_OD_CAN1_TxErrCnt 1;
BA_ "CANzero_SDO_AccessIfOperational" SG_ 1507 MDB2_OD_CAN1_TxErrCnt 1;
BA_ "CANzero_SDO_AccessType" SG_ 1507 MDB2_OD_BuildTime 1;
BA_ "CANzero_SDO_AccessIfOperational" SG_ 1507 MDB2_OD_BuildTime 1;
BA_ "CANzero_SDO_AccessType" SG_ 1507 MDB2_OD_BuildDate 1;
BA_ "CANzero_SDO_AccessIfOperational" SG_ 1507 MDB2_OD_BuildDate 1;
BA_ "CANzero_SDO_AccessType" SG_ 1507 MDB2_OD_ChipUID2 1;
BA_ "CANzero_SDO_AccessIfOperational" SG_ 1507 MDB2_OD_ChipUID2 1;
BA_ "CANzero_SDO_AccessType" SG_ 1507 MDB2_OD_ChipUID1 1;
BA_ "CANzero_SDO_AccessIfOperational" SG_ 1507 MDB2_OD_ChipUID1 1;
BA_ "CANzero_SDO_AccessType" SG_ 1507 MDB2_OD_SdcOut 1;
BA_ "CANzero_SDO_AccessIfOperational" SG_ 1507 MDB2_OD_SdcOut 1;
BA_ "CANzero_SDO_AccessType" SG_ 1507 MDB2_OD_SdcIn 1;
BA_ "CANzero_SDO_AccessIfOperational" SG_ 1507 MDB2_OD_SdcIn 1;
BA_ "CANzero_SDO_AccessType" SG_ 1507 MDB2_OD_runtime 1;
BA_ "CANzero_SDO_AccessIfOperational" SG_ 1507 MDB2_OD_runtime 1;
BA_ "CANzero_SDO_AccessType" SG_ 1507 MDB2_OD_InputVoltage 1;
BA_ "CANzero_SDO_AccessIfOperational" SG_ 1507 MDB2_OD_InputVoltage 1;
BA_ "CANzero_SDO_AccessType" SG_ 1507 MDB2_OD_BoardTemp 1;
BA_ "CANzero_SDO_AccessIfOperational" SG_ 1507 MDB2_OD_BoardTemp 1;
BA_ "GenSigStartValue" SG_ 1507 MDB2_OD_BoardTemp 3000.0;
BA_ "CANzero_SDO_AccessType" SG_ 1507 MDB2_OD_MemFree 1;
BA_ "CANzero_SDO_AccessIfOperational" SG_ 1507 MDB2_OD_MemFree 1;
BA_ "CANzero_SDO_AccessType" SG_ 1507 MDB2_OD_CpuUsage 1;
BA_ "CANzero_SDO_AccessIfOperational" SG_ 1507 MDB2_OD_CpuUsage 1;
BA_ "CANzero_SDO_AccessIfOperational" SG_ 1507 MDB2_OD_OdEntrySendInterval 1;
BA_ "GenSigStartValue" SG_ 1507 MDB2_OD_OdEntrySendInterval 50.0;
BA_ "CANzero_SDO_Default" SG_ 1507 MDB2_OD_OdEntrySendInterval 50;
BA_ "CANzero_SDO_AccessIfOperational" SG_ 1507 MDB2_OD_SendOdOnBootup 1;
BA_ "CANzero_SDO_AccessIfOperational" SG_ 1507 MDB2_OD_HeartbeatInterval 1;
BA_ "GenSigStartValue" SG_ 1507 MDB2_OD_HeartbeatInterval 250.0;
BA_ "CANzero_SDO_Default" SG_ 1507 MDB2_OD_HeartbeatInterval 250;
BA_ "CANzero_SDO_AccessType" SG_ 1507 MDB2_OD_DbcVersion 1;
BA_ "CANzero_SDO_AccessIfOperational" SG_ 1507 MDB2_OD_DbcVersion 1;
BA_ "CANzero_SDO_AccessType" SG_ 1507 MDB2_OD_StackVersion 1;
BA_ "CANzero_SDO_AccessIfOperational" SG_ 1507 MDB2_OD_StackVersion 1;
BA_ "CANzero_SDO_AccessType" SG_ 1507 MDB2_OD_ProtocolVersion 1;
BA_ "CANzero_SDO_AccessIfOperational" SG_ 1507 MDB2_OD_ProtocolVersion 1;
BA_ "GenSigStartValue" SG_ 1507 MDB2_OD_ProtocolVersion 1.0;
BA_ "CANzero_SDO_Default" SG_ 1507 MDB2_OD_ProtocolVersion 1;
BA_ "CANzero_SDO_AccessType" SG_ 1507 MDB2_OD_NodeStatus 1;
BA_ "CANzero_SDO_AccessIfOperational" SG_ 1507 MDB2_OD_NodeStatus 1;
BA_ "CANzero_SDO_AccessType" SG_ 1507 MDB2_OD_NodeID 1;
BA_ "CANzero_SDO_AccessIfOperational" SG_ 1507 MDB2_OD_NodeID 1;
VAL_ 1433 HVTU_OD_CAN2_ErrorStatus 0 "Ok" 1 "Warn" 2 "Error Passive" 3 "Bus Off" ;
VAL_ 1433 HVTU_OD_CAN2_Status 0 "Reset" 1 "Ready" 2 "Listening" 3 "Sleep_Pending" 4 "Sleep_Active" 5 "ERROR" ;
VAL_ 1433 HVTU_OD_CAN2_autoErrorReset 0 "Disabled" 1 "Enabled" ;
VAL_ 1433 HVTU_OD_CAN2_lastErrorCode 0 "No Error" 1 "Stuff Error" 2 "Form Error" 3 "Ack Error" 4 "Bit recessive Error" 5 "Bit dominant Error" 6 "CRC Error" ;
VAL_ 1433 HVTU_OD_CAN1_ErrorStatus 0 "Ok" 1 "Warn" 2 "Error Passive" 3 "Bus Off" ;
VAL_ 1433 HVTU_OD_CAN1_Status 0 "Reset" 1 "Ready" 2 "Listening" 3 "Sleep_Pending" 4 "Sleep_Active" 5 "ERROR" ;
VAL_ 1433 HVTU_OD_CAN1_autoErrorReset 0 "Disabled" 1 "Enabled" ;
VAL_ 1433 HVTU_OD_CAN1_lastErrorCode 0 "No Error" 1 "Stuff Error" 2 "Form Error" 3 "Ack Error" 4 "Bit recessive Error" 5 "Bit dominant Error" 6 "CRC Error" ;
VAL_ 1433 HVTU_OD_SendOdOnBootup 0 "Disabled" 1 "Enabled" ;
VAL_ 1433 HVTU_OD_NodeStatus 0 "Bootup" 4 "Stopped" 5 "Operational" 127 "Pre-Operational" 128 "Reset" ;
VAL_ 1433 HVTU_SDO_RespCode 5 "ERR: Out of range" 4 "ERR: No access in this state" 3 "ERR: Read only object" 2 "ERR: Write only object" 1 "ERR: Non existing object" 0 "OK" ;
VAL_ 1433 HVTU_SDO_ID 0 "Reserved" 1 "NodeID" 2 "NodeStatus" 3 "ProtocolVersion" 4 "StackVersion" 5 "DbcVersion" 16 "HeartbeatInterval" 32 "SendOdOnBootup" 33 "OdEntrySendInterval" 1040 "CpuUsage" 1041 "MemFree" 1042 "BoardTemp" 1043 "InputVoltage" 1044 "runtime" 1045 "SdcIn" 1046 "SdcOut" 1056 "ChipUID1" 1057 "ChipUID2" 1072 "BuildDate" 1073 "BuildTime" 1104 "CAN1_TxErrCnt" 1105 "CAN1_RxErrCnt" 1106 "CAN1_lastErrorCode" 1107 "CAN1_autoErrorReset" 1108 "CAN1_Baudrate" 1110 "CAN1_Status" 1111 "CAN1_DiscardedTxMessages" 1112 "CAN1_ErrorStatus" 1113 "CAN1_DelayedTxMessages" 1120 "CAN2_TxErrCnt" 1121 "CAN2_RxErrCnt" 1122 "CAN2_lastErrorCode" 1123 "CAN2_autoErrorReset" 1124 "CAN2_Baudrate" 1126 "CAN2_Status" 1127 "CAN2_DiscardedTxMessages" 1128 "CAN2_ErrorStatus" 1129 "CAN2_DelayedTxMessages" ;
VAL_ 1497 HVTU_OD_CAN2_ErrorStatus 0 "Ok" 1 "Warn" 2 "Error Passive" 3 "Bus Off" ;
VAL_ 1497 HVTU_OD_CAN2_Status 0 "Reset" 1 "Ready" 2 "Listening" 3 "Sleep_Pending" 4 "Sleep_Active" 5 "ERROR" ;
VAL_ 1497 HVTU_OD_CAN2_autoErrorReset 0 "Disabled" 1 "Enabled" ;
VAL_ 1497 HVTU_OD_CAN2_lastErrorCode 0 "No Error" 1 "Stuff Error" 2 "Form Error" 3 "Ack Error" 4 "Bit recessive Error" 5 "Bit dominant Error" 6 "CRC Error" ;
VAL_ 1497 HVTU_OD_CAN1_ErrorStatus 0 "Ok" 1 "Warn" 2 "Error Passive" 3 "Bus Off" ;
VAL_ 1497 HVTU_OD_CAN1_Status 0 "Reset" 1 "Ready" 2 "Listening" 3 "Sleep_Pending" 4 "Sleep_Active" 5 "ERROR" ;
VAL_ 1497 HVTU_OD_CAN1_autoErrorReset 0 "Disabled" 1 "Enabled" ;
VAL_ 1497 HVTU_OD_CAN1_lastErrorCode 0 "No Error" 1 "Stuff Error" 2 "Form Error" 3 "Ack Error" 4 "Bit recessive Error" 5 "Bit dominant Error" 6 "CRC Error" ;
VAL_ 1497 HVTU_OD_SendOdOnBootup 0 "Disabled" 1 "Enabled" ;
VAL_ 1497 HVTU_OD_NodeStatus 0 "Bootup" 4 "Stopped" 5 "Operational" 127 "Pre-Operational" 128 "Reset" ;
VAL_ 1497 HVTU_SDO_ID 0 "Reserved" 1 "NodeID" 2 "NodeStatus" 3 "ProtocolVersion" 4 "StackVersion" 5 "DbcVersion" 16 "HeartbeatInterval" 32 "SendOdOnBootup" 33 "OdEntrySendInterval" 1040 "CpuUsage" 1041 "MemFree" 1042 "BoardTemp" 1043 "InputVoltage" 1044 "runtime" 1045 "SdcIn" 1046 "SdcOut" 1056 "ChipUID1" 1057 "ChipUID2" 1072 "BuildDate" 1073 "BuildTime" 1104 "CAN1_TxErrCnt" 1105 "CAN1_RxErrCnt" 1106 "CAN1_lastErrorCode" 1107 "CAN1_autoErrorReset" 1108 "CAN1_Baudrate" 1110 "CAN1_Status" 1111 "CAN1_DiscardedTxMessages" 1112 "CAN1_ErrorStatus" 1113 "CAN1_DelayedTxMessages" 1120 "CAN2_TxErrCnt" 1121 "CAN2_RxErrCnt" 1122 "CAN2_lastErrorCode" 1123 "CAN2_autoErrorReset" 1124 "CAN2_Baudrate" 1126 "CAN2_Status" 1127 "CAN2_DiscardedTxMessages" 1128 "CAN2_ErrorStatus" 1129 "CAN2_DelayedTxMessages" ;
VAL_ 1561 HVTU_SDO_ID 0 "Reserved" 1 "NodeID" 2 "NodeStatus" 3 "ProtocolVersion" 4 "StackVersion" 5 "DbcVersion" 16 "HeartbeatInterval" 32 "SendOdOnBootup" 33 "OdEntrySendInterval" 1040 "CpuUsage" 1041 "MemFree" 1042 "BoardTemp" 1043 "InputVoltage" 1044 "runtime" 1045 "SdcIn" 1046 "SdcOut" 1056 "ChipUID1" 1057 "ChipUID2" 1072 "BuildDate" 1073 "BuildTime" 1104 "CAN1_TxErrCnt" 1105 "CAN1_RxErrCnt" 1106 "CAN1_lastErrorCode" 1107 "CAN1_autoErrorReset" 1108 "CAN1_Baudrate" 1110 "CAN1_Status" 1111 "CAN1_DiscardedTxMessages" 1112 "CAN1_ErrorStatus" 1113 "CAN1_DelayedTxMessages" 1120 "CAN2_TxErrCnt" 1121 "CAN2_RxErrCnt" 1122 "CAN2_lastErrorCode" 1123 "CAN2_autoErrorReset" 1124 "CAN2_Baudrate" 1126 "CAN2_Status" 1127 "CAN2_DiscardedTxMessages" 1128 "CAN2_ErrorStatus" 1129 "CAN2_DelayedTxMessages" ;
VAL_ 1817 HVTU_NodeState 0 "Bootup" 4 "Stopped" 5 "Operational" 127 "Pre-Operational" ;
VAL_ 162 TelemetryNode_E0_OtherError 0 "Ok" 1 "ERR" ;
VAL_ 162 TelemetryNode_W0_OtherWarning 0 "Ok" 1 "WARN" ;
VAL_ 482 TelemetryNode_RX_Shutdown 2 "Reboot" 1 "Shutdown" 0 "None" ;
VAL_ 1442 TelemetryNode_OD_CanRestart 0 "None" 1 "Restart CAN" ;
VAL_ 1442 TelemetryNode_OD_Reboot 0 "None" 1 "Reboot" ;
VAL_ 1442 TelemetryNode_OD_Shutdown 0 "None" 1 "Shutdown" ;
VAL_ 1442 TelemetryNode_OD_CAN2_ErrorStatu 0 "Ok" 1 "Warn" 2 "Error Passive" 3 "Bus Off" ;
VAL_ 1442 TelemetryNode_OD_CAN2_Status 0 "Reset" 1 "Ready" 2 "Listening" 3 "Sleep_Pending" 4 "Sleep_Active" 5 "ERROR" ;
VAL_ 1442 TelemetryNode_OD_CAN2_autoErrorR 0 "Disabled" 1 "Enabled" ;
VAL_ 1442 TelemetryNode_OD_CAN2_lastErrorC 0 "No Error" 1 "Stuff Error" 2 "Form Error" 3 "Ack Error" 4 "Bit recessive Error" 5 "Bit dominant Error" 6 "CRC Error" ;
VAL_ 1442 TelemetryNode_OD_CAN1_ErrorStatu 0 "Ok" 1 "Warn" 2 "Error Passive" 3 "Bus Off" ;
VAL_ 1442 TelemetryNode_OD_CAN1_Status 0 "Reset" 1 "Ready" 2 "Listening" 3 "Sleep_Pending" 4 "Sleep_Active" 5 "ERROR" ;
VAL_ 1442 TelemetryNode_OD_CAN1_autoErrorR 0 "Disabled" 1 "Enabled" ;
VAL_ 1442 TelemetryNode_OD_CAN1_lastErrorC 0 "No Error" 1 "Stuff Error" 2 "Form Error" 3 "Ack Error" 4 "Bit recessive Error" 5 "Bit dominant Error" 6 "CRC Error" ;
VAL_ 1442 TelemetryNode_OD_SendOdOnBootup 0 "Disabled" 1 "Enabled" ;
VAL_ 1442 TelemetryNode_OD_NodeStatus 0 "Bootup" 4 "Stopped" 5 "Operational" 127 "Pre-Operational" 128 "Reset" ;
VAL_ 1442 TelemetryNode_SDO_RespCode 5 "ERR: Out of range" 4 "ERR: No access in this state" 3 "ERR: Read only object" 2 "ERR: Write only object" 1 "ERR: Non existing object" 0 "OK" ;
VAL_ 1442 TelemetryNode_SDO_ID 0 "Reserved" 1 "NodeID" 2 "NodeStatus" 3 "ProtocolVersion" 4 "StackVersion" 5 "DbcVersion" 16 "HeartbeatInterval" 32 "SendOdOnBootup" 33 "OdEntrySendInterval" 1040 "CpuUsage" 1041 "MemFree" 1042 "BoardTemp" 1043 "InputVoltage" 1044 "runtime" 1045 "SdcIn" 1046 "SdcOut" 1056 "ChipUID1" 1057 "ChipUID2" 1072 "BuildDate" 1073 "BuildTime" 1104 "CAN1_TxErrCnt" 1105 "CAN1_RxErrCnt" 1106 "CAN1_lastErrorCode" 1107 "CAN1_autoErrorReset" 1108 "CAN1_Baudrate" 1110 "CAN1_Status" 1111 "CAN1_DiscardedTxMessages" 1112 "CAN1_ErrorStatus" 1113 "CAN1_DelayedTxMessages" 1120 "CAN2_TxErrCnt" 1121 "CAN2_RxErrCnt" 1122 "CAN2_lastErrorCode" 1123 "CAN2_autoErrorReset" 1124 "CAN2_Baudrate" 1126 "CAN2_Status" 1127 "CAN2_DiscardedTxMessages" 1128 "CAN2_ErrorStatus" 1129 "CAN2_DelayedTxMessages" 2048 "Shutdown" 2049 "Reboot" 2050 "CanRestart" ;
VAL_ 1506 TelemetryNode_OD_CanRestart 0 "None" 1 "Restart CAN" ;
VAL_ 1506 TelemetryNode_OD_Reboot 0 "None" 1 "Reboot" ;
VAL_ 1506 TelemetryNode_OD_Shutdown 0 "None" 1 "Shutdown" ;
VAL_ 1506 TelemetryNode_OD_CAN2_Error_0000 0 "Ok" 1 "Warn" 2 "Error Passive" 3 "Bus Off" ;
VAL_ 1506 TelemetryNode_OD_CAN2_Status 0 "Reset" 1 "Ready" 2 "Listening" 3 "Sleep_Pending" 4 "Sleep_Active" 5 "ERROR" ;
VAL_ 1506 TelemetryNode_OD_CAN2_autoE_0000 0 "Disabled" 1 "Enabled" ;
VAL_ 1506 TelemetryNode_OD_CAN2_lastE_0000 0 "No Error" 1 "Stuff Error" 2 "Form Error" 3 "Ack Error" 4 "Bit recessive Error" 5 "Bit dominant Error" 6 "CRC Error" ;
VAL_ 1506 TelemetryNode_OD_CAN1_Error_0000 0 "Ok" 1 "Warn" 2 "Error Passive" 3 "Bus Off" ;
VAL_ 1506 TelemetryNode_OD_CAN1_Status 0 "Reset" 1 "Ready" 2 "Listening" 3 "Sleep_Pending" 4 "Sleep_Active" 5 "ERROR" ;
VAL_ 1506 TelemetryNode_OD_CAN1_autoE_0000 0 "Disabled" 1 "Enabled" ;
VAL_ 1506 TelemetryNode_OD_CAN1_lastE_0000 0 "No Error" 1 "Stuff Error" 2 "Form Error" 3 "Ack Error" 4 "Bit recessive Error" 5 "Bit dominant Error" 6 "CRC Error" ;
VAL_ 1506 TelemetryNode_OD_SendOdOnBootup 0 "Disabled" 1 "Enabled" ;
VAL_ 1506 TelemetryNode_OD_NodeStatus 0 "Bootup" 4 "Stopped" 5 "Operational" 127 "Pre-Operational" 128 "Reset" ;
VAL_ 1506 TelemetryNode_SDO_ID 0 "Reserved" 1 "NodeID" 2 "NodeStatus" 3 "ProtocolVersion" 4 "StackVersion" 5 "DbcVersion" 16 "HeartbeatInterval" 32 "SendOdOnBootup" 33 "OdEntrySendInterval" 1040 "CpuUsage" 1041 "MemFree" 1042 "BoardTemp" 1043 "InputVoltage" 1044 "runtime" 1045 "SdcIn" 1046 "SdcOut" 1056 "ChipUID1" 1057 "ChipUID2" 1072 "BuildDate" 1073 "BuildTime" 1104 "CAN1_TxErrCnt" 1105 "CAN1_RxErrCnt" 1106 "CAN1_lastErrorCode" 1107 "CAN1_autoErrorReset" 1108 "CAN1_Baudrate" 1110 "CAN1_Status" 1111 "CAN1_DiscardedTxMessages" 1112 "CAN1_ErrorStatus" 1113 "CAN1_DelayedTxMessages" 1120 "CAN2_TxErrCnt" 1121 "CAN2_RxErrCnt" 1122 "CAN2_lastErrorCode" 1123 "CAN2_autoErrorReset" 1124 "CAN2_Baudrate" 1126 "CAN2_Status" 1127 "CAN2_DiscardedTxMessages" 1128 "CAN2_ErrorStatus" 1129 "CAN2_DelayedTxMessages" 2048 "Shutdown" 2049 "Reboot" 2050 "CanRestart" ;
VAL_ 1570 TelemetryNode_SDO_ID 0 "Reserved" 1 "NodeID" 2 "NodeStatus" 3 "ProtocolVersion" 4 "StackVersion" 5 "DbcVersion" 16 "HeartbeatInterval" 32 "SendOdOnBootup" 33 "OdEntrySendInterval" 1040 "CpuUsage" 1041 "MemFree" 1042 "BoardTemp" 1043 "InputVoltage" 1044 "runtime" 1045 "SdcIn" 1046 "SdcOut" 1056 "ChipUID1" 1057 "ChipUID2" 1072 "BuildDate" 1073 "BuildTime" 1104 "CAN1_TxErrCnt" 1105 "CAN1_RxErrCnt" 1106 "CAN1_lastErrorCode" 1107 "CAN1_autoErrorReset" 1108 "CAN1_Baudrate" 1110 "CAN1_Status" 1111 "CAN1_DiscardedTxMessages" 1112 "CAN1_ErrorStatus" 1113 "CAN1_DelayedTxMessages" 1120 "CAN2_TxErrCnt" 1121 "CAN2_RxErrCnt" 1122 "CAN2_lastErrorCode" 1123 "CAN2_autoErrorReset" 1124 "CAN2_Baudrate" 1126 "CAN2_Status" 1127 "CAN2_DiscardedTxMessages" 1128 "CAN2_ErrorStatus" 1129 "CAN2_DelayedTxMessages" 2048 "Shutdown" 2049 "Reboot" 2050 "CanRestart" ;
VAL_ 1826 TelemetryNode_NodeState 0 "Bootup" 4 "Stopped" 5 "Operational" 127 "Pre-Operational" ;
VAL_ 161 MDB1_E0_OtherError 0 "Ok" 1 "ERR" ;
VAL_ 161 MDB1_W0_OtherWarning 0 "Ok" 1 "WARN" ;
VAL_ 1441 MDB1_OD_CAN2_ErrorStatus 0 "Ok" 1 "Warn" 2 "Error Passive" 3 "Bus Off" ;
VAL_ 1441 MDB1_OD_CAN2_Status 0 "Reset" 1 "Ready" 2 "Listening" 3 "Sleep_Pending" 4 "Sleep_Active" 5 "ERROR" ;
VAL_ 1441 MDB1_OD_CAN2_autoErrorReset 0 "Disabled" 1 "Enabled" ;
VAL_ 1441 MDB1_OD_CAN2_lastErrorCode 0 "No Error" 1 "Stuff Error" 2 "Form Error" 3 "Ack Error" 4 "Bit recessive Error" 5 "Bit dominant Error" 6 "CRC Error" ;
VAL_ 1441 MDB1_OD_CAN1_ErrorStatus 0 "Ok" 1 "Warn" 2 "Error Passive" 3 "Bus Off" ;
VAL_ 1441 MDB1_OD_CAN1_Status 0 "Reset" 1 "Ready" 2 "Listening" 3 "Sleep_Pending" 4 "Sleep_Active" 5 "ERROR" ;
VAL_ 1441 MDB1_OD_CAN1_autoErrorReset 0 "Disabled" 1 "Enabled" ;
VAL_ 1441 MDB1_OD_CAN1_lastErrorCode 0 "No Error" 1 "Stuff Error" 2 "Form Error" 3 "Ack Error" 4 "Bit recessive Error" 5 "Bit dominant Error" 6 "CRC Error" ;
VAL_ 1441 MDB1_OD_SendOdOnBootup 0 "Disabled" 1 "Enabled" ;
VAL_ 1441 MDB1_OD_NodeStatus 0 "Bootup" 4 "Stopped" 5 "Operational" 127 "Pre-Operational" 128 "Reset" ;
VAL_ 1441 MDB1_SDO_RespCode 5 "ERR: Out of range" 4 "ERR: No access in this state" 3 "ERR: Read only object" 2 "ERR: Write only object" 1 "ERR: Non existing object" 0 "OK" ;
VAL_ 1441 MDB1_SDO_ID 0 "Reserved" 1 "NodeID" 2 "NodeStatus" 3 "ProtocolVersion" 4 "StackVersion" 5 "DbcVersion" 16 "HeartbeatInterval" 32 "SendOdOnBootup" 33 "OdEntrySendInterval" 1040 "CpuUsage" 1041 "MemFree" 1042 "BoardTemp" 1043 "InputVoltage" 1044 "runtime" 1045 "SdcIn" 1046 "SdcOut" 1056 "ChipUID1" 1057 "ChipUID2" 1072 "BuildDate" 1073 "BuildTime" 1104 "CAN1_TxErrCnt" 1105 "CAN1_RxErrCnt" 1106 "CAN1_lastErrorCode" 1107 "CAN1_autoErrorReset" 1108 "CAN1_Baudrate" 1110 "CAN1_Status" 1111 "CAN1_DiscardedTxMessages" 1112 "CAN1_ErrorStatus" 1113 "CAN1_DelayedTxMessages" 1120 "CAN2_TxErrCnt" 1121 "CAN2_RxErrCnt" 1122 "CAN2_lastErrorCode" 1123 "CAN2_autoErrorReset" 1124 "CAN2_Baudrate" 1126 "CAN2_Status" 1127 "CAN2_DiscardedTxMessages" 1128 "CAN2_ErrorStatus" 1129 "CAN2_DelayedTxMessages" ;
VAL_ 1505 MDB1_OD_CAN2_ErrorStatus 0 "Ok" 1 "Warn" 2 "Error Passive" 3 "Bus Off" ;
VAL_ 1505 MDB1_OD_CAN2_Status 0 "Reset" 1 "Ready" 2 "Listening" 3 "Sleep_Pending" 4 "Sleep_Active" 5 "ERROR" ;
VAL_ 1505 MDB1_OD_CAN2_autoErrorReset 0 "Disabled" 1 "Enabled" ;
VAL_ 1505 MDB1_OD_CAN2_lastErrorCode 0 "No Error" 1 "Stuff Error" 2 "Form Error" 3 "Ack Error" 4 "Bit recessive Error" 5 "Bit dominant Error" 6 "CRC Error" ;
VAL_ 1505 MDB1_OD_CAN1_ErrorStatus 0 "Ok" 1 "Warn" 2 "Error Passive" 3 "Bus Off" ;
VAL_ 1505 MDB1_OD_CAN1_Status 0 "Reset" 1 "Ready" 2 "Listening" 3 "Sleep_Pending" 4 "Sleep_Active" 5 "ERROR" ;
VAL_ 1505 MDB1_OD_CAN1_autoErrorReset 0 "Disabled" 1 "Enabled" ;
VAL_ 1505 MDB1_OD_CAN1_lastErrorCode 0 "No Error" 1 "Stuff Error" 2 "Form Error" 3 "Ack Error" 4 "Bit recessive Error" 5 "Bit dominant Error" 6 "CRC Error" ;
VAL_ 1505 MDB1_OD_SendOdOnBootup 0 "Disabled" 1 "Enabled" ;
VAL_ 1505 MDB1_OD_NodeStatus 0 "Bootup" 4 "Stopped" 5 "Operational" 127 "Pre-Operational" 128 "Reset" ;
VAL_ 1505 MDB1_SDO_ID 0 "Reserved" 1 "NodeID" 2 "NodeStatus" 3 "ProtocolVersion" 4 "StackVersion" 5 "DbcVersion" 16 "HeartbeatInterval" 32 "SendOdOnBootup" 33 "OdEntrySendInterval" 1040 "CpuUsage" 1041 "MemFree" 1042 "BoardTemp" 1043 "InputVoltage" 1044 "runtime" 1045 "SdcIn" 1046 "SdcOut" 1056 "ChipUID1" 1057 "ChipUID2" 1072 "BuildDate" 1073 "BuildTime" 1104 "CAN1_TxErrCnt" 1105 "CAN1_RxErrCnt" 1106 "CAN1_lastErrorCode" 1107 "CAN1_autoErrorReset" 1108 "CAN1_Baudrate" 1110 "CAN1_Status" 1111 "CAN1_DiscardedTxMessages" 1112 "CAN1_ErrorStatus" 1113 "CAN1_DelayedTxMessages" 1120 "CAN2_TxErrCnt" 1121 "CAN2_RxErrCnt" 1122 "CAN2_lastErrorCode" 1123 "CAN2_autoErrorReset" 1124 "CAN2_Baudrate" 1126 "CAN2_Status" 1127 "CAN2_DiscardedTxMessages" 1128 "CAN2_ErrorStatus" 1129 "CAN2_DelayedTxMessages" ;
VAL_ 1569 MDB1_SDO_ID 0 "Reserved" 1 "NodeID" 2 "NodeStatus" 3 "ProtocolVersion" 4 "StackVersion" 5 "DbcVersion" 16 "HeartbeatInterval" 32 "SendOdOnBootup" 33 "OdEntrySendInterval" 1040 "CpuUsage" 1041 "MemFree" 1042 "BoardTemp" 1043 "InputVoltage" 1044 "runtime" 1045 "SdcIn" 1046 "SdcOut" 1056 "ChipUID1" 1057 "ChipUID2" 1072 "BuildDate" 1073 "BuildTime" 1104 "CAN1_TxErrCnt" 1105 "CAN1_RxErrCnt" 1106 "CAN1_lastErrorCode" 1107 "CAN1_autoErrorReset" 1108 "CAN1_Baudrate" 1110 "CAN1_Status" 1111 "CAN1_DiscardedTxMessages" 1112 "CAN1_ErrorStatus" 1113 "CAN1_DelayedTxMessages" 1120 "CAN2_TxErrCnt" 1121 "CAN2_RxErrCnt" 1122 "CAN2_lastErrorCode" 1123 "CAN2_autoErrorReset" 1124 "CAN2_Baudrate" 1126 "CAN2_Status" 1127 "CAN2_DiscardedTxMessages" 1128 "CAN2_ErrorStatus" 1129 "CAN2_DelayedTxMessages" ;
VAL_ 1825 MDB1_NodeState 0 "Bootup" 4 "Stopped" 5 "Operational" 127 "Pre-Operational" ;
VAL_ 163 MDB2_E0_OtherError 0 "Ok" 1 "ERR" ;
VAL_ 163 MDB2_W0_OtherWarning 0 "Ok" 1 "WARN" ;
VAL_ 1443 MDB2_OD_CAN2_ErrorStatus 0 "Ok" 1 "Warn" 2 "Error Passive" 3 "Bus Off" ;
VAL_ 1443 MDB2_OD_CAN2_Status 0 "Reset" 1 "Ready" 2 "Listening" 3 "Sleep_Pending" 4 "Sleep_Active" 5 "ERROR" ;
VAL_ 1443 MDB2_OD_CAN2_autoErrorReset 0 "Disabled" 1 "Enabled" ;
VAL_ 1443 MDB2_OD_CAN2_lastErrorCode 0 "No Error" 1 "Stuff Error" 2 "Form Error" 3 "Ack Error" 4 "Bit recessive Error" 5 "Bit dominant Error" 6 "CRC Error" ;
VAL_ 1443 MDB2_OD_CAN1_ErrorStatus 0 "Ok" 1 "Warn" 2 "Error Passive" 3 "Bus Off" ;
VAL_ 1443 MDB2_OD_CAN1_Status 0 "Reset" 1 "Ready" 2 "Listening" 3 "Sleep_Pending" 4 "Sleep_Active" 5 "ERROR" ;
VAL_ 1443 MDB2_OD_CAN1_autoErrorReset 0 "Disabled" 1 "Enabled" ;
VAL_ 1443 MDB2_OD_CAN1_lastErrorCode 0 "No Error" 1 "Stuff Error" 2 "Form Error" 3 "Ack Error" 4 "Bit recessive Error" 5 "Bit dominant Error" 6 "CRC Error" ;
VAL_ 1443 MDB2_OD_SendOdOnBootup 0 "Disabled" 1 "Enabled" ;
VAL_ 1443 MDB2_OD_NodeStatus 0 "Bootup" 4 "Stopped" 5 "Operational" 127 "Pre-Operational" 128 "Reset" ;
VAL_ 1443 MDB2_SDO_RespCode 5 "ERR: Out of range" 4 "ERR: No access in this state" 3 "ERR: Read only object" 2 "ERR: Write only object" 1 "ERR: Non existing object" 0 "OK" ;
VAL_ 1443 MDB2_SDO_ID 0 "Reserved" 1 "NodeID" 2 "NodeStatus" 3 "ProtocolVersion" 4 "StackVersion" 5 "DbcVersion" 16 "HeartbeatInterval" 32 "SendOdOnBootup" 33 "OdEntrySendInterval" 1040 "CpuUsage" 1041 "MemFree" 1042 "BoardTemp" 1043 "InputVoltage" 1044 "runtime" 1045 "SdcIn" 1046 "SdcOut" 1056 "ChipUID1" 1057 "ChipUID2" 1072 "BuildDate" 1073 "BuildTime" 1104 "CAN1_TxErrCnt" 1105 "CAN1_RxErrCnt" 1106 "CAN1_lastErrorCode" 1107 "CAN1_autoErrorReset" 1108 "CAN1_Baudrate" 1110 "CAN1_Status" 1111 "CAN1_DiscardedTxMessages" 1112 "CAN1_ErrorStatus" 1113 "CAN1_DelayedTxMessages" 1120 "CAN2_TxErrCnt" 1121 "CAN2_RxErrCnt" 1122 "CAN2_lastErrorCode" 1123 "CAN2_autoErrorReset" 1124 "CAN2_Baudrate" 1126 "CAN2_Status" 1127 "CAN2_DiscardedTxMessages" 1128 "CAN2_ErrorStatus" 1129 "CAN2_DelayedTxMessages" ;
VAL_ 1507 MDB2_OD_CAN2_ErrorStatus 0 "Ok" 1 "Warn" 2 "Error Passive" 3 "Bus Off" ;
VAL_ 1507 MDB2_OD_CAN2_Status 0 "Reset" 1 "Ready" 2 "Listening" 3 "Sleep_Pending" 4 "Sleep_Active" 5 "ERROR" ;
VAL_ 1507 MDB2_OD_CAN2_autoErrorReset 0 "Disabled" 1 "Enabled" ;
VAL_ 1507 MDB2_OD_CAN2_lastErrorCode 0 "No Error" 1 "Stuff Error" 2 "Form Error" 3 "Ack Error" 4 "Bit recessive Error" 5 "Bit dominant Error" 6 "CRC Error" ;
VAL_ 1507 MDB2_OD_CAN1_ErrorStatus 0 "Ok" 1 "Warn" 2 "Error Passive" 3 "Bus Off" ;
VAL_ 1507 MDB2_OD_CAN1_Status 0 "Reset" 1 "Ready" 2 "Listening" 3 "Sleep_Pending" 4 "Sleep_Active" 5 "ERROR" ;
VAL_ 1507 MDB2_OD_CAN1_autoErrorReset 0 "Disabled" 1 "Enabled" ;
VAL_ 1507 MDB2_OD_CAN1_lastErrorCode 0 "No Error" 1 "Stuff Error" 2 "Form Error" 3 "Ack Error" 4 "Bit recessive Error" 5 "Bit dominant Error" 6 "CRC Error" ;
VAL_ 1507 MDB2_OD_SendOdOnBootup 0 "Disabled" 1 "Enabled" ;
VAL_ 1507 MDB2_OD_NodeStatus 0 "Bootup" 4 "Stopped" 5 "Operational" 127 "Pre-Operational" 128 "Reset" ;
VAL_ 1507 MDB2_SDO_ID 0 "Reserved" 1 "NodeID" 2 "NodeStatus" 3 "ProtocolVersion" 4 "StackVersion" 5 "DbcVersion" 16 "HeartbeatInterval" 32 "SendOdOnBootup" 33 "OdEntrySendInterval" 1040 "CpuUsage" 1041 "MemFree" 1042 "BoardTemp" 1043 "InputVoltage" 1044 "runtime" 1045 "SdcIn" 1046 "SdcOut" 1056 "ChipUID1" 1057 "ChipUID2" 1072 "BuildDate" 1073 "BuildTime" 1104 "CAN1_TxErrCnt" 1105 "CAN1_RxErrCnt" 1106 "CAN1_lastErrorCode" 1107 "CAN1_autoErrorReset" 1108 "CAN1_Baudrate" 1110 "CAN1_Status" 1111 "CAN1_DiscardedTxMessages" 1112 "CAN1_ErrorStatus" 1113 "CAN1_DelayedTxMessages" 1120 "CAN2_TxErrCnt" 1121 "CAN2_RxErrCnt" 1122 "CAN2_lastErrorCode" 1123 "CAN2_autoErrorReset" 1124 "CAN2_Baudrate" 1126 "CAN2_Status" 1127 "CAN2_DiscardedTxMessages" 1128 "CAN2_ErrorStatus" 1129 "CAN2_DelayedTxMessages" ;
VAL_ 1571 MDB2_SDO_ID 0 "Reserved" 1 "NodeID" 2 "NodeStatus" 3 "ProtocolVersion" 4 "StackVersion" 5 "DbcVersion" 16 "HeartbeatInterval" 32 "SendOdOnBootup" 33 "OdEntrySendInterval" 1040 "CpuUsage" 1041 "MemFree" 1042 "BoardTemp" 1043 "InputVoltage" 1044 "runtime" 1045 "SdcIn" 1046 "SdcOut" 1056 "ChipUID1" 1057 "ChipUID2" 1072 "BuildDate" 1073 "BuildTime" 1104 "CAN1_TxErrCnt" 1105 "CAN1_RxErrCnt" 1106 "CAN1_lastErrorCode" 1107 "CAN1_autoErrorReset" 1108 "CAN1_Baudrate" 1110 "CAN1_Status" 1111 "CAN1_DiscardedTxMessages" 1112 "CAN1_ErrorStatus" 1113 "CAN1_DelayedTxMessages" 1120 "CAN2_TxErrCnt" 1121 "CAN2_RxErrCnt" 1122 "CAN2_lastErrorCode" 1123 "CAN2_autoErrorReset" 1124 "CAN2_Baudrate" 1126 "CAN2_Status" 1127 "CAN2_DiscardedTxMessages" 1128 "CAN2_ErrorStatus" 1129 "CAN2_DelayedTxMessages" ;
VAL_ 1827 MDB2_NodeState 0 "Bootup" 4 "Stopped" 5 "Operational" 127 "Pre-Operational" ;
VAL_ 167 MDB3_E0_OtherError 0 "Ok" 1 "ERR" ;
VAL_ 167 MDB3_W0_OtherWarning 0 "Ok" 1 "WARN" ;
